VERSION ""

NS_ :

BS_:

BU_: BSM BSM2 CADM CVADAS ECM EPS ORC CANOE EVCU2

BO_ 609 BRAKE_FD_4: 32 BSM
 SG_ FD14_ASRActive : 90|1@0+ (1,0) [0|1] "-" Vector__XXX
 SG_ FD14_BSM_LnchAbrtSts : 33|2@0+ (1,0) [0|2] "-" Vector__XXX
 SG_ FD14_BSM_LnchCtrl_SftBtn_SelectS : 0|1@0+ (1,0) [0|1] "-" Vector__XXX
 SG_ FD14_BSM_LnchMode : 55|3@0+ (1,0) [0|6] "-" Vector__XXX
 SG_ FD14_CRC_BRAKE4 : 191|8@0+ (1,0) [0|255] "-"  CADM
 SG_ FD14_EPBSts : 115|4@0+ (1,0) [0|14] "-"  CADM,CVADAS
 SG_ FD14_ESC_OFF_Hrd_Sft_Button_sts : 151|3@0+ (1,0) [0|6] "-" Vector__XXX
 SG_ FD14_LaunchRPMsetting_BSM : 63|6@0+ (100,1000) [1000|7300] "rpm" Vector__XXX
 SG_ FD14_MessageCounter_BRAKE4 : 179|4@0+ (1,0) [0|15] "-"  CADM
 SG_ FD14_MSRActive : 92|1@0+ (1,0) [0|1] "-" Vector__XXX
 SG_ FD14_TravelDistance : 87|8@0+ (1,0) [0|255] "m" Vector__XXX

BO_ 1155 BRAKE_FD_5: 32 BSM
 SG_ FD14_ABSFailSts : 87|1@0+ (1,0) [0|1] "-"  ECM
 SG_ FD14_ACCEngaged : 92|1@0+ (1,0) [0|1] "-" Vector__XXX
 SG_ FD14_BSM_THA_Brk_Resp : 15|2@0+ (1,0) [0|3] "-"  CVADAS
 SG_ FD14_BSMSysSts : 89|2@0+ (1,0) [0|3] "-"  CADM
 SG_ FD14_CMMIntervention : 86|1@0+ (1,0) [0|1] "-" Vector__XXX
 SG_ FD14_CRC_BRAKE5 : 191|8@0+ (1,0) [0|255] "-"  BSM2,CADM,CVADAS,ECM
 SG_ FD14_EBDFailSts : 84|1@0+ (1,0) [0|1] "-" Vector__XXX
 SG_ FD14_ERMActive : 111|1@0+ (1,0) [0|1] "-" Vector__XXX
 SG_ FD14_ESC_TRSC_Brk_Resp : 5|2@0+ (1,0) [0|2] "-"  CVADAS
 SG_ FD14_ESCFailSts : 83|1@0+ (1,0) [0|1] "-"  CADM
 SG_ FD14_Function2Sts : 94|1@0+ (1,0) [0|1] "-" Vector__XXX
 SG_ FD14_FunctionFailSts : 81|1@0+ (1,0) [0|1] "-" Vector__XXX
 SG_ FD14_FunctionIntervention : 80|1@0+ (1,0) [0|1] "-" Vector__XXX
 SG_ FD14_FunctionSts : 95|1@0+ (1,0) [0|1] "-"  CADM
 SG_ FD14_MessageCounter_BRAKE5 : 179|4@0+ (1,0) [0|15] "-"  BSM2,CADM,CVADAS,ECM
 SG_ FD14_RollsModeAct : 91|1@0+ (1,0) [0|1] "-"  BSM2,CADM
 SG_ FD14_TSCActive : 110|1@0+ (1,0) [0|1] "-" Vector__XXX

BO_ 205 BRAKE_FD_6: 64 BSM
 SG_ FD14_CRC_BRAKE_FD_6 : 447|8@0+ (1,0) [0|255] "-"  ECM
 SG_ FD14_DriverReq_AxleTrq_Enabled_B : 175|4@0+ (1,0) [0|15] ""  CVADAS,ECM
 SG_ FD14_DriverRequested_AxleTrq_BSM : 159|16@0+ (2,-65534) [-65534|65536] "Nm"  ECM
 SG_ FD14_MessageCounter_BRAKE_FD_6 : 435|4@0+ (1,0) [0|15] "-"  ECM
 SG_ FD14_TotalAxle_Max_Rq_BSM : 51|1@0+ (1,0) [0|1] ""  ECM
 SG_ FD14_TotalAxle_Min_Rq_BSM : 50|1@0+ (1,0) [0|1] ""  ECM
 SG_ FD14_TotalAxle_Rq_BSM : 95|16@0+ (2,-65534) [-65534|65536] "Nm"  ECM

BO_ 514 BRAKE_FD_7: 32 BSM
 SG_ FD14_AEB_Type_Brk : 67|4@0+ (1,0) [0|14] "-"  BSM2,CADM,ORC
 SG_ FD14_Brake_OpStat_Prim : 82|3@0+ (1,0) [0|5] ""  CADM,ORC
 SG_ FD14_BrakePdlPosn : 63|8@0+ (0.4,0) [0|100] "%"  BSM2,CADM
 SG_ FD14_BrkPdl_Flt : 86|1@0+ (1,0) [0|1] "-"  CADM
 SG_ FD14_BrkPdl_Stat : 85|2@0+ (1,0) [0|2] "-"  BSM2,CADM,CVADAS,ECM
 SG_ FD14_BSM_HEALTH_CHECK : 7|8@0+ (1,0) [0|255] ""  BSM2
 SG_ FD14_BSM_OpStat : 74|3@0+ (1,0) [0|5] ""  BSM2,CADM
 SG_ FD14_CRC_BRAKE7 : 191|8@0+ (1,0) [0|255] "-"  BSM2,CADM
 SG_ FD14_MessageCounter_BRAKE7 : 179|4@0+ (1,0) [0|15] "-"  BSM2,CADM
 SG_ FD14_PAM_Brk_Rq_RspSts : 28|2@0+ (1,0) [0|3] "-"  CVADAS

BO_ 257 BRAKE2_FD_1: 64 BSM2
 SG_ FD14_ABSActive_B2 : 37|1@0+ (1,0) [0|1] ""  CADM
 SG_ FD14_Brk_Stat_B2 : 71|2@0+ (1,0) [0|2] ""  CADM
 SG_ FD14_CRC_BRAKE2_1 : 447|8@0+ (1,0) [0|255] "-"  CADM,CVADAS,EPS,ORC
 SG_ FD14_Ft_RrAxleCoupling_TrqRq_B2 : 143|8@0+ (12,0) [0|3060] "Nm" Vector__XXX
 SG_ FD14_Ft_RrTrqCoupling_ModeRq_B2 : 158|2@0+ (1,0) [0|3] "-" Vector__XXX
 SG_ FD14_Inlet_Pressure_Pos : 98|2@0+ (1,0) [0|2] ""  CADM
 SG_ FD14_LHF_FastPulseCounter_B2 : 87|8@0+ (1,0) [0|255] "pulse"  CADM
 SG_ FD14_LHF_Spin_B2 : 39|2@0+ (1,0) [0|3] ""  CADM
 SG_ FD14_LHF_WheelSensorFailSts_B2 : 53|1@0+ (1,0) [0|1] ""  CADM
 SG_ FD14_LHFWheelSpeed_B2 : 52|13@0+ (0.0625,0) [0|511.875] "Km/h"  CADM
 SG_ FD14_MessageCounter_BRAKE2_1 : 435|4@0+ (1,0) [0|15] "-"  CADM,CVADAS,EPS,ORC
 SG_ FD14_R_DIFF_TRQ_RQ_B2 : 151|9@0+ (10,0) [0|5100] "Nm" Vector__XXX
 SG_ FD14_Rear_Diff_BSM_RQ_B2 : 156|2@0+ (1,0) [0|2] "-" Vector__XXX
 SG_ FD14_RHF_FastPulseCounter_B2 : 95|8@0+ (1,0) [0|255] "pulse"  CADM
 SG_ FD14_RHF_Spin_B2 : 55|2@0+ (1,0) [0|3] ""  CADM
 SG_ FD14_RHF_WheelSensorFailSts_B2 : 69|1@0+ (1,0) [0|1] ""  CADM
 SG_ FD14_RHFWheelSpeed_B2 : 68|13@0+ (0.0625,0) [0|511.875] "Km/h"  CADM
 SG_ FD14_VehicleSpeedVSOSig_B2 : 36|13@0+ (0.0625,0) [0|511.875] "Km/h"  CADM,CVADAS,EPS

BO_ 524 BRAKE2_FD_2: 32 BSM2
 SG_ FD14_AEB_Type_Brk_B2 : 43|4@0+ (1,0) [0|15] ""  CADM
 SG_ FD14_Brake_OpStat_Sec : 53|3@0+ (1,0) [0|5] ""  CADM
 SG_ FD14_BrkTrq_B2 : 6|15@0+ (3,0) [0|98301] "Nm"  CADM
 SG_ FD14_BSM2_HEALTH_CHECK : 63|8@0+ (1,0) [0|255] ""  BSM
 SG_ FD14_BSM2_OpStat : 50|3@0+ (1,0) [0|5] ""  BSM,CADM
 SG_ FD14_CRC_BRAKE2_2 : 191|8@0+ (1,0) [0|255] "-"  BSM,CADM,ORC
 SG_ FD14_MessageCounter_BRAKE2_2 : 179|4@0+ (1,0) [0|15] "-"  BSM,CADM,ORC
 SG_ FD14_VehicleStandStillSts_B2 : 47|2@0+ (1,0) [0|2] ""  BSM,CADM

BO_ 1156 BRAKE2_FD_3: 32 BSM2
 SG_ FD14_ABSFailSts_B2 : 7|1@0+ (1,0) [0|1] ""  CADM
 SG_ FD14_CRC_BRAKE2_3 : 191|8@0+ (1,0) [0|255] "-"  CADM,ORC
 SG_ FD14_MessageCounter_BRAKE2_3 : 179|4@0+ (1,0) [0|15] "-"  CADM,ORC
 SG_ FD14_RollsModeAct_B2 : 6|1@0+ (1,0) [0|1] ""  CADM

BO_ 275 CVPAM_FD_Control: 32 CVADAS
 SG_ FD14_CRC_CVPAM_FD_Control : 191|8@0+ (1,0) [0|255] "-"  BSM,EPS
 SG_ FD14_ManoeuvrePhase : 149|1@0+ (1,0) [0|1] "-"  EPS
 SG_ FD14_MessageCounter_CVPAM_FD_Con : 179|4@0+ (1,0) [0|15] "-"  BSM,EPS
 SG_ FD14_ParkingGearShiftReq : 164|3@0+ (1,0) [0|6] "-"  BSM
 SG_ FD14_PPPA_AccelMax : 116|5@0+ (0.1,0) [0|3.1] "m/s2"  BSM
 SG_ FD14_PPPA_AccelMin : 108|5@0+ (0.1,0) [0|3.1] "m/s2"  BSM
 SG_ FD14_PPPA_DecelMax : 100|5@0+ (0.1,0) [0|3.1] "m/s2"  BSM
 SG_ FD14_PPPA_DecelMin : 92|5@0+ (0.1,0) [0|3.1] "m/s2"  BSM
 SG_ FD14_PPPA_Interface_BSM : 182|2@0+ (1,0) [0|2] "-"  BSM
 SG_ FD14_PPPA_JerkAccelMax : 85|6@0+ (0.05,0) [0|3.15] "m/s3"  BSM
 SG_ FD14_PPPA_JerkAccelMin : 77|6@0+ (0.05,0) [0|3.15] "m/s3"  BSM
 SG_ FD14_PPPA_JerkDecelMax : 69|6@0+ (0.05,0) [0|3.15] "m/s3"  BSM
 SG_ FD14_PPPA_JerkDecelMin : 61|6@0+ (0.05,0) [0|3.15] "m/s3"  BSM
 SG_ FD14_PPPA_MaxSpeed : 127|8@0+ (0.0625,0) [0|15.875] "kph"  BSM
 SG_ FD14_PPPA_StandstillRqst : 180|1@0+ (1,0) [0|1] "-"  BSM
 SG_ FD14_PPPA_TargetDistance : 129|10@0+ (1,0) [0|1022] "cm"  BSM
 SG_ FD14_RR_PAM_Brk_RqSts : 150|1@0+ (1,0) [0|1] "-"  BSM
 SG_ FD14_RR_PAM_Dist : 161|10@0+ (1,0) [0|1022] "cm"  BSM
 SG_ FD14_SPM_Lat_Ctrl_RequestSts : 148|2@0+ (1,0) [0|2] "-"  EPS,ORC
 SG_ FD14_TorqueOverlaySteeringReq_SP : 146|11@0+ (0.0078125,-8) [-8|7.9921875] "Nm"  EPS,ORC

BO_ 950 CVPAM_FD_Info: 32 CVADAS
 SG_ FD14_CRC_CVPAM_FD_Info : 191|8@0+ (1,0) [0|255] ""  BSM
 SG_ FD14_MessageCounter_CVPAM_FD_Inf : 179|4@0+ (1,0) [0|15] ""  BSM
 SG_ FD14_ParkingManeuverActive : 66|3@0+ (1,0) [0|6] "-"  BSM

BO_ 1054 ENGINE_FD_1: 32 ECM
 SG_ FD14_CRC_ENGINE1 : 191|8@0+ (1,0) [0|255] "-"  CADM
 SG_ FD14_MessageCounter_ENGINE1 : 179|4@0+ (1,0) [0|15] "-"  CADM
 SG_ FD14_ThermalManagementActive_W : 1|1@0+ (1,0) [0|1] "-"  CADM

BO_ 262 ENGINE_FD_2: 64 ECM
 SG_ FD14_CRC_ENGINE2 : 447|8@0+ (1,0) [0|255] "-"  BSM,CADM,CVADAS,EPS
 SG_ FD14_ECM_LHOM_W : 188|1@0+ (1,0) [0|1] "-"  CADM
 SG_ FD14_EngineSpeed_W : 21|14@0+ (1,0) [0|16382] "1/min"  BSM,CADM,EPS
 SG_ FD14_EngineSts_W : 87|2@0+ (1,0) [0|3] "-"  BSM,CADM,CVADAS,EPS
 SG_ FD14_ESS_ENG_ST_W : 175|4@0+ (1,0) [0|15] "-"  BSM,CADM,CVADAS,EPS
 SG_ FD14_GasPedalPosition_W : 143|8@0+ (0.392,0) [0|99.568] "%"  BSM
 SG_ FD14_GasPedalPositionFailSts_W : 169|1@0+ (1,0) [0|1] "-"  BSM,CADM
 SG_ FD14_LV12PwrFreeRq_W : 176|1@0+ (1,0) [0|1] "-" Vector__XXX
 SG_ FD14_MessageCounter_ENGINE2 : 435|4@0+ (1,0) [0|15] "-"  BSM,CADM,CVADAS,EPS
 SG_ FD14_PowertrainPrplsnActv : 181|1@0+ (1,0) [0|1] ""  BSM,CADM

BO_ 1036 ENGINE_FD_3: 32 ECM
 SG_ FD14_CRC_ENGINE3 : 191|8@0+ (1,0) [0|255] "-"  BSM
 SG_ FD14_MessageCounter_ENGINE3 : 179|4@0+ (1,0) [0|15] "-"  BSM

BO_ 518 ENGINE_FD_5: 32 ECM
 SG_ FD14_CRC_ENGINE5 : 191|8@0+ (1,0) [0|255] "-"  BSM,BSM2,CADM
 SG_ FD14_MessageCounter_ENGINE5 : 179|4@0+ (1,0) [0|15] "-"  BSM,BSM2,CADM
 SG_ FD14_PdlPosActual : 87|8@0+ (0.4,0) [0|100] "%"  BSM,BSM2,CADM,CVADAS
 SG_ FD14_RPMOverRev_W : 115|1@0+ (1,0) [0|1] "-"  CADM

BO_ 1448 ENGINE_FD_7: 32 ECM
 SG_ FD14_CRC_ENGINE7 : 191|8@0+ (1,0) [0|255] "-"  CVADAS
 SG_ FD14_ECM_THA_Resp : 73|2@0+ (1,0) [0|2] "-"  CVADAS
 SG_ FD14_ECM_TRSC_Resp : 7|2@0+ (1,0) [0|2] "-"  CVADAS
 SG_ FD14_MessageCounter_ENGINE7 : 179|4@0+ (1,0) [0|15] "-"  CVADAS

BO_ 264 EPS_FD_1: 32 EPS
 SG_ FD14_CRC_EPS1 : 191|8@0+ (1,0) [0|255] "-"  BSM,CADM,CVADAS,ORC
 SG_ FD14_ElectricSteeringFailSts : 37|1@0+ (1,0) [0|1] "-" Vector__XXX
 SG_ FD14_EngineFanRequestActivation : 38|1@0+ (1,0) [0|1] "-" Vector__XXX
 SG_ FD14_EPS_ADAS_IMC_Fault : 69|1@0+ (1,0) [0|1] ""  CADM
 SG_ FD14_EPS_AsstStat : 55|3@0+ (1,0) [0|6] "-"  CADM
 SG_ FD14_EPS_Curr : 87|8@0+ (1,-50) [-50|204] "Amp" Vector__XXX
 SG_ FD14_EPS_Hands_On_Sts : 67|1@0+ (1,0) [0|1] "-"  CADM,ORC
 SG_ FD14_EPS_HandsOnRecognition : 22|1@0+ (1,0) [0|1] "-"  CVADAS,ORC
 SG_ FD14_EPSMotorTorque : 66|11@0+ (0.004882815,-5) [-5|4.99023949] "Nm"  CADM,ORC
 SG_ FD14_ESA_LAT_CTRL_ResponseSts : 135|3@0+ (1,0) [0|6] "-"  BSM,CADM
 SG_ FD14_HAS_LAT_CTRL_ResponseSts : 101|3@0+ (1,0) [0|7] "-"  CADM,ORC
 SG_ FD14_LKA_LAT_CTRL_ResponseSts : 71|2@0+ (1,0) [0|3] "-"  CADM,ORC
 SG_ FD14_LwsAngle : 7|16@0+ (0.1,-720) [-720|720] "°"  BSM,CADM,CVADAS
 SG_ FD14_LwsAngleType : 52|2@0+ (1,0) [0|2] "-"  BSM,CADM,CVADAS
 SG_ FD14_LwsCalibration : 36|1@0+ (1,0) [0|1] "-"  BSM,CADM
 SG_ FD14_LwsSpeed : 19|12@0+ (1,-2000) [-2000|2094] "°/s"  CADM,CVADAS
 SG_ FD14_MessageCounter_EPS1 : 179|4@0+ (1,0) [0|15] "-"  BSM,CADM,CVADAS,ORC
 SG_ FD14_SPM_Lat_Ctrl_ResponseSts : 103|2@0+ (1,0) [0|3] "-"  CVADAS,ORC
 SG_ FD14_Steering_Column_Torque : 50|11@0+ (0.0078125,-8) [-8|7.984375] "NM"  CADM,CVADAS
 SG_ FD14_Steering_OpStat_Prim : 111|3@0+ (1,0) [0|5] ""  CADM,ORC
 SG_ FD14_SteeringVibration_Fault : 39|1@0+ (1,0) [0|1] "-"  CADM
 SG_ FD14_SteeringVibration_Status : 23|1@0+ (1,0) [0|1] "-"  CADM,ORC

BO_ 1056 EPS_FD_2: 32 EPS
 SG_ FD14_CRC_EPS2 : 191|8@0+ (1,0) [0|255] "0"  CVADAS
 SG_ FD14_EPS_MODE_STAT : 7|3@0+ (1,0) [0|3] "" Vector__XXX
 SG_ FD14_EPS_SteeringTouchStat : 4|1@0+ (1,0) [0|1] ""  CVADAS
 SG_ FD14_EPS_SteeringTouq_Resp : 3|2@0+ (1,0) [0|1] ""  CVADAS
 SG_ FD14_EPS_THA_DriverTorqueOverrid : 1|2@0+ (1,0) [0|1] ""  CVADAS
 SG_ FD14_EPS_THA_SteeringTorqueResp : 13|3@0+ (1,0) [0|6] ""  CVADAS
 SG_ FD14_EPS_Warn_Disp_Rq : 87|3@0+ (1,0) [0|3] "" Vector__XXX
 SG_ FD14_MessageCounter_EPS2 : 179|4@0+ (1,0) [0|15] "0"  CVADAS
 SG_ FD14_THA_SteeringTouchStat : 15|2@0+ (1,0) [0|1] ""  CVADAS

BO_ 1626 IMPACT_INFO: 32 ORC
 SG_ FD14_IMPACT_B : 84|1@0+ (1,0) [0|1] "-" Vector__XXX
 SG_ FD14_IMPACT_C : 85|1@0+ (1,0) [0|1] "-" Vector__XXX
 SG_ FD14_IMPACT_F : 88|1@0+ (1,0) [0|1] "-" Vector__XXX
 SG_ FD14_IMPACT_I : 91|1@0+ (1,0) [0|1] "-" Vector__XXX
 SG_ FD14_IMPACT_K : 92|1@0+ (1,0) [0|1] "-" Vector__XXX
 SG_ FD14_IMPACT_M : 94|1@0+ (1,0) [0|1] "-" Vector__XXX
 SG_ FD14_IMPACTCommand : 80|1@0+ (1,0) [0|1] "-"  CADM
 SG_ FD14_IMPACTConfirm : 81|1@0+ (1,0) [0|1] "-"  CADM
 SG_ FD14_IMPACTFailSts : 82|1@0+ (1,0) [0|1] "-" Vector__XXX
 SG_ FD14_IMPACTThreshold : 103|1@0+ (1,0) [0|1] "-" Vector__XXX

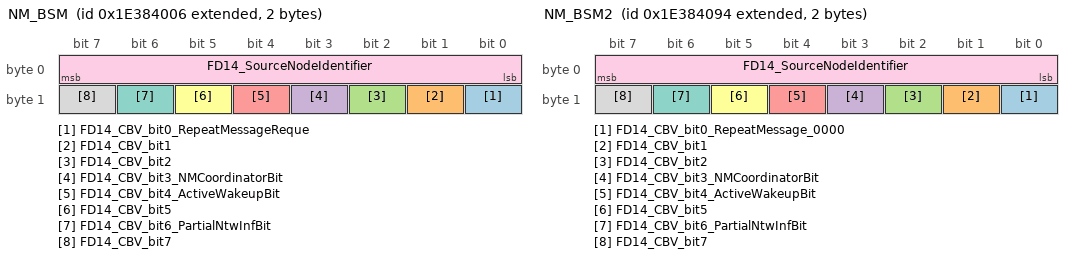
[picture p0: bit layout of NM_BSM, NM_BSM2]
BO_ 2654486534 NM_BSM: 2 BSM
 SG_ FD14_CBV_bit0_RepeatMessageReque : 8|1@0+ (1,0) [0|1] ""  BSM2,CADM,CVADAS,ECM,EPS,ORC
 SG_ FD14_CBV_bit1 : 9|1@0+ (1,0) [0|1] ""  BSM2,CADM,CVADAS,ECM,EPS,ORC
 SG_ FD14_CBV_bit2 : 10|1@0+ (1,0) [0|1] ""  BSM2,CADM,CVADAS,ECM,EPS,ORC
 SG_ FD14_CBV_bit3_NMCoordinatorBit : 11|1@0+ (1,0) [0|1] ""  BSM2,CADM,CVADAS,ECM,EPS,ORC
 SG_ FD14_CBV_bit4_ActiveWakeupBit : 12|1@0+ (1,0) [0|1] ""  BSM2,CADM,CVADAS,ECM,EPS,ORC
 SG_ FD14_CBV_bit5 : 13|1@0+ (1,0) [0|1] ""  BSM2,CADM,CVADAS,ECM,EPS,ORC
 SG_ FD14_CBV_bit6_PartialNtwInfBit : 14|1@0+ (1,0) [0|1] ""  BSM2,CADM,CVADAS,ECM,EPS,ORC
 SG_ FD14_CBV_bit7 : 15|1@0+ (1,0) [0|1] ""  BSM2,CADM,CVADAS,ECM,EPS,ORC
 SG_ FD14_SourceNodeIdentifier : 7|8@0+ (1,0) [0|255] "-"  BSM2,CADM,CVADAS,ECM,EPS,ORC

BO_ 2654486676 NM_BSM2: 2 BSM2
 SG_ FD14_CBV_bit0_RepeatMessage_0000 : 8|1@0+ (1,0) [0|1] ""  BSM,CADM,CVADAS,ECM,EPS,ORC
 SG_ FD14_CBV_bit1 : 9|1@0+ (1,0) [0|1] ""  BSM,CADM,CVADAS,ECM,EPS,ORC
 SG_ FD14_CBV_bit2 : 10|1@0+ (1,0) [0|1] ""  BSM,CADM,CVADAS,ECM,EPS,ORC
 SG_ FD14_CBV_bit3_NMCoordinatorBit : 11|1@0+ (1,0) [0|1] ""  BSM,CADM,CVADAS,ECM,EPS,ORC
 SG_ FD14_CBV_bit4_ActiveWakeupBit : 12|1@0+ (1,0) [0|1] ""  BSM,CADM,CVADAS,ECM,EPS,ORC
 SG_ FD14_CBV_bit5 : 13|1@0+ (1,0) [0|1] ""  BSM,CADM,CVADAS,ECM,EPS,ORC
 SG_ FD14_CBV_bit6_PartialNtwInfBit : 14|1@0+ (1,0) [0|1] ""  BSM,CADM,CVADAS,ECM,EPS,ORC
 SG_ FD14_CBV_bit7 : 15|1@0+ (1,0) [0|1] ""  BSM,CADM,CVADAS,ECM,EPS,ORC
 SG_ FD14_SourceNodeIdentifier : 7|8@0+ (1,0) [0|255] "-"  BSM,CADM,CVADAS,ECM,EPS,ORC

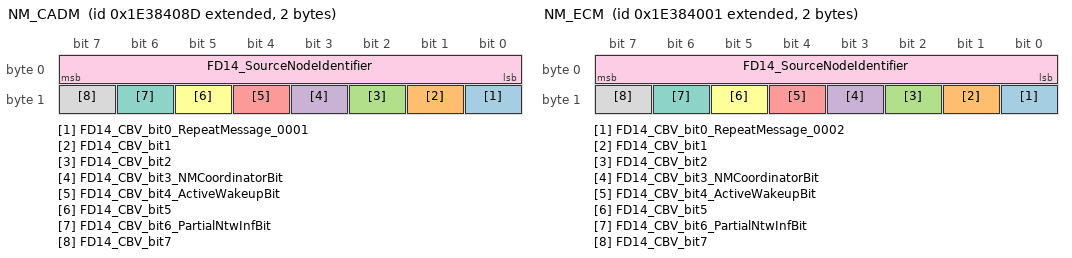
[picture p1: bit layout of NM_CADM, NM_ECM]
BO_ 2654486669 NM_CADM: 2 CADM
 SG_ FD14_CBV_bit0_RepeatMessage_0001 : 8|1@0+ (1,0) [0|1] ""  BSM,BSM2,CVADAS,ECM,EPS,ORC
 SG_ FD14_CBV_bit1 : 9|1@0+ (1,0) [0|1] ""  BSM,BSM2,CVADAS,ECM,EPS,ORC
 SG_ FD14_CBV_bit2 : 10|1@0+ (1,0) [0|1] ""  BSM,BSM2,CVADAS,ECM,EPS,ORC
 SG_ FD14_CBV_bit3_NMCoordinatorBit : 11|1@0+ (1,0) [0|1] ""  BSM,BSM2,CVADAS,ECM,EPS,ORC
 SG_ FD14_CBV_bit4_ActiveWakeupBit : 12|1@0+ (1,0) [0|1] ""  BSM,BSM2,CVADAS,ECM,EPS,ORC
 SG_ FD14_CBV_bit5 : 13|1@0+ (1,0) [0|1] ""  BSM,BSM2,CVADAS,ECM,EPS,ORC
 SG_ FD14_CBV_bit6_PartialNtwInfBit : 14|1@0+ (1,0) [0|1] ""  BSM,BSM2,CVADAS,ECM,EPS,ORC
 SG_ FD14_CBV_bit7 : 15|1@0+ (1,0) [0|1] ""  BSM,BSM2,CVADAS,ECM,EPS,ORC
 SG_ FD14_SourceNodeIdentifier : 7|8@0+ (1,0) [0|255] "-"  BSM,BSM2,CVADAS,ECM,EPS,ORC

BO_ 2654486529 NM_ECM: 2 ECM
 SG_ FD14_CBV_bit0_RepeatMessage_0002 : 8|1@0+ (1,0) [0|1] ""  BSM,BSM2,CADM,CVADAS,EPS,ORC
 SG_ FD14_CBV_bit1 : 9|1@0+ (1,0) [0|1] ""  BSM,BSM2,CADM,CVADAS,EPS,ORC
 SG_ FD14_CBV_bit2 : 10|1@0+ (1,0) [0|1] ""  BSM,BSM2,CADM,CVADAS,EPS,ORC
 SG_ FD14_CBV_bit3_NMCoordinatorBit : 11|1@0+ (1,0) [0|1] ""  BSM,BSM2,CADM,CVADAS,EPS,ORC
 SG_ FD14_CBV_bit4_ActiveWakeupBit : 12|1@0+ (1,0) [0|1] ""  BSM,BSM2,CADM,CVADAS,EPS,ORC
 SG_ FD14_CBV_bit5 : 13|1@0+ (1,0) [0|1] ""  BSM,BSM2,CADM,CVADAS,EPS,ORC
 SG_ FD14_CBV_bit6_PartialNtwInfBit : 14|1@0+ (1,0) [0|1] ""  BSM,BSM2,CADM,CVADAS,EPS,ORC
 SG_ FD14_CBV_bit7 : 15|1@0+ (1,0) [0|1] ""  BSM,BSM2,CADM,CVADAS,EPS,ORC
 SG_ FD14_SourceNodeIdentifier : 7|8@0+ (1,0) [0|255] "-"  BSM,BSM2,CADM,CVADAS,EPS,ORC

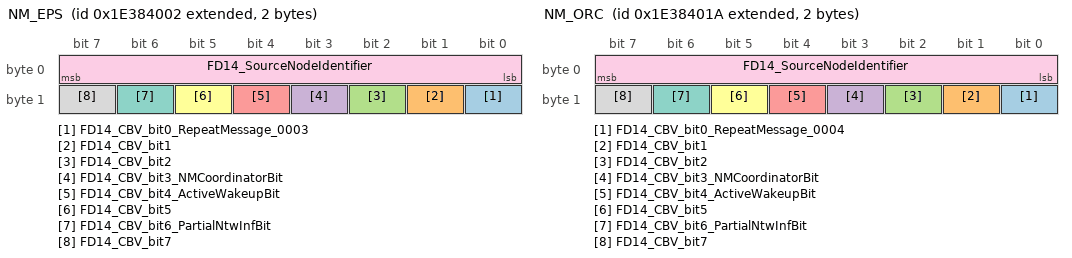
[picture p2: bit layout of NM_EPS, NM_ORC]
BO_ 2654486530 NM_EPS: 2 EPS
 SG_ FD14_CBV_bit0_RepeatMessage_0003 : 8|1@0+ (1,0) [0|1] ""  BSM,BSM2,CADM,CVADAS,ECM,ORC
 SG_ FD14_CBV_bit1 : 9|1@0+ (1,0) [0|1] ""  BSM,BSM2,CADM,CVADAS,ECM,ORC
 SG_ FD14_CBV_bit2 : 10|1@0+ (1,0) [0|1] ""  BSM,BSM2,CADM,CVADAS,ECM,ORC
 SG_ FD14_CBV_bit3_NMCoordinatorBit : 11|1@0+ (1,0) [0|1] ""  BSM,BSM2,CADM,CVADAS,ECM,ORC
 SG_ FD14_CBV_bit4_ActiveWakeupBit : 12|1@0+ (1,0) [0|1] ""  BSM,BSM2,CADM,CVADAS,ECM,ORC
 SG_ FD14_CBV_bit5 : 13|1@0+ (1,0) [0|1] ""  BSM,BSM2,CADM,CVADAS,ECM,ORC
 SG_ FD14_CBV_bit6_PartialNtwInfBit : 14|1@0+ (1,0) [0|1] ""  BSM,BSM2,CADM,CVADAS,ECM,ORC
 SG_ FD14_CBV_bit7 : 15|1@0+ (1,0) [0|1] ""  BSM,BSM2,CADM,CVADAS,ECM,ORC
 SG_ FD14_SourceNodeIdentifier : 7|8@0+ (1,0) [0|255] "-"  BSM,BSM2,CADM,CVADAS,ECM,ORC

BO_ 2654486554 NM_ORC: 2 ORC
 SG_ FD14_CBV_bit0_RepeatMessage_0004 : 8|1@0+ (1,0) [0|1] ""  BSM,BSM2,CADM,CVADAS,ECM,EPS
 SG_ FD14_CBV_bit1 : 9|1@0+ (1,0) [0|1] ""  BSM,BSM2,CADM,CVADAS,ECM,EPS
 SG_ FD14_CBV_bit2 : 10|1@0+ (1,0) [0|1] ""  BSM,BSM2,CADM,CVADAS,ECM,EPS
 SG_ FD14_CBV_bit3_NMCoordinatorBit : 11|1@0+ (1,0) [0|1] ""  BSM,BSM2,CADM,CVADAS,ECM,EPS
 SG_ FD14_CBV_bit4_ActiveWakeupBit : 12|1@0+ (1,0) [0|1] ""  BSM,BSM2,CADM,CVADAS,ECM,EPS
 SG_ FD14_CBV_bit5 : 13|1@0+ (1,0) [0|1] ""  BSM,BSM2,CADM,CVADAS,ECM,EPS
 SG_ FD14_CBV_bit6_PartialNtwInfBit : 14|1@0+ (1,0) [0|1] ""  BSM,BSM2,CADM,CVADAS,ECM,EPS
 SG_ FD14_CBV_bit7 : 15|1@0+ (1,0) [0|1] ""  BSM,BSM2,CADM,CVADAS,ECM,EPS
 SG_ FD14_SourceNodeIdentifier : 7|8@0+ (1,0) [0|255] "-"  BSM,BSM2,CADM,CVADAS,ECM,EPS

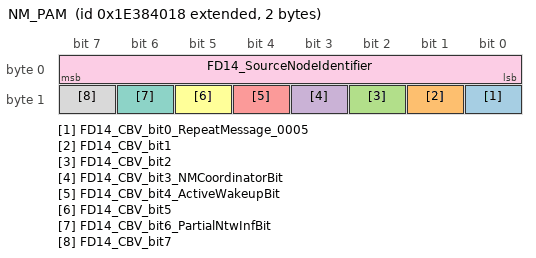
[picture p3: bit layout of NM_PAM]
BO_ 2654486552 NM_PAM: 2 CVADAS
 SG_ FD14_CBV_bit0_RepeatMessage_0005 : 8|1@0+ (1,0) [0|1] ""  BSM,BSM2,CADM,ECM,EPS,ORC
 SG_ FD14_CBV_bit1 : 9|1@0+ (1,0) [0|1] ""  BSM,BSM2,CADM,ECM,EPS,ORC
 SG_ FD14_CBV_bit2 : 10|1@0+ (1,0) [0|1] ""  BSM,BSM2,CADM,ECM,EPS,ORC
 SG_ FD14_CBV_bit3_NMCoordinatorBit : 11|1@0+ (1,0) [0|1] ""  BSM,BSM2,CADM,ECM,EPS,ORC
 SG_ FD14_CBV_bit4_ActiveWakeupBit : 12|1@0+ (1,0) [0|1] ""  BSM,BSM2,CADM,ECM,EPS,ORC
 SG_ FD14_CBV_bit5 : 13|1@0+ (1,0) [0|1] ""  BSM,BSM2,CADM,ECM,EPS,ORC
 SG_ FD14_CBV_bit6_PartialNtwInfBit : 14|1@0+ (1,0) [0|1] ""  BSM,BSM2,CADM,ECM,EPS,ORC
 SG_ FD14_CBV_bit7 : 15|1@0+ (1,0) [0|1] ""  BSM,BSM2,CADM,ECM,EPS,ORC
 SG_ FD14_SourceNodeIdentifier : 7|8@0+ (1,0) [0|255] "-"  BSM,BSM2,CADM,ECM,EPS,ORC

BO_ 611 ORC_FD_1: 32 ORC
 SG_ FD14_CRC_ORC1 : 191|8@0+ (1,0) [0|255] "-"  BSM,CADM
 SG_ FD14_MessageCounter_ORC1 : 179|4@0+ (1,0) [0|15] "-"  BSM,CADM
 SG_ FD14_SBR1RowDriverSeatSts : 94|2@0+ (1,0) [0|2] "-"  BSM,CADM

BO_ 1954 ORC_FD_2: 32 ORC
 SG_ FD14_CRC_ORC2 : 191|8@0+ (1,0) [0|255] "-"  BSM
 SG_ FD14_MessageCounter_ORC2 : 179|4@0+ (1,0) [0|15] "-"  BSM
 SG_ FD14_ORCIdentification : 87|32@0+ (1,0) [0|4294967295] "-"  BSM

BO_ 274 ORC_FD_3: 32 ORC
 SG_ FD14_CRC_ORC3 : 191|8@0+ (1,0) [0|255] "-"  BSM,CADM
 SG_ FD14_InternalError : 165|1@0+ (1,0) [0|1] "-"  BSM,CADM
 SG_ FD14_LatAcceleration : 147|12@0+ (0.02,-40.96) [-40.96|40.92] "m/s^2"  BSM,CADM
 SG_ FD14_LatAccelerationFailSts : 182|1@0+ (1,0) [0|1] "-"  BSM,CADM
 SG_ FD14_LongAcceleration : 131|12@0+ (0.02,-40.96) [-40.96|40.92] "m/s^2"  BSM,CADM
 SG_ FD14_LongAccelerationFailSts : 183|1@0+ (1,0) [0|1] "-"  BSM,CADM
 SG_ FD14_MessageCounter_ORC3 : 179|4@0+ (1,0) [0|15] "-"  BSM,CADM
 SG_ FD14_YawRate : 163|12@0+ (0.08,-163.84) [-163.84|163.68] "deg/s"  BSM,CADM
 SG_ FD14_YawRate_HR : 10|3@0+ (0.02,0) [0|0.06] "deg/s"  CADM
 SG_ FD14_YawRate_HR_Sign : 7|1@0+ (1,0) [0|1] "deg/s"  CADM
 SG_ FD14_YawRateFailSts : 181|1@0+ (1,0) [0|1] "-"  BSM,CADM

BO_ 255 PT_TORQUE_FD_1: 48 ECM
 SG_ FD14_ACC_NCC_TrqEnblRq_Allowed : 23|1@0+ (1,0) [0|1] "-"  CADM
 SG_ FD14_Accel_Pedal_Override : 37|1@0+ (1,0) [0|1] "-"  BSM,CADM,CVADAS
 SG_ FD14_CRC_PT_TORQUE_FD_1 : 319|8@0+ (1,0) [0|255] "-"  BSM,CADM
 SG_ FD14_ESC_TrqEnblRq_Allowed : 38|1@0+ (1,0) [0|1] "-" Vector__XXX
 SG_ FD14_MessageCounter_PT_TORQUE_FD : 307|4@0+ (1,0) [0|15] "-"  BSM,CADM
 SG_ FD14_PPPA_TrqEnblRq_Allowed : 21|1@0+ (1,0) [0|1] "-"  BSM,CVADAS
 SG_ FD14_SSC_TrqEnblRq_Allowed : 22|1@0+ (1,0) [0|1] "-" Vector__XXX
 SG_ FD14_SumTorque_DrvReqMod : 20|13@0+ (0.25,-500) [-500|1547.5] "Nm" Vector__XXX
 SG_ FD14_SumTorqueExp : 34|11@0+ (1,-500) [-500|1546] "Nm" Vector__XXX
 SG_ FD14_SumTorqueMax : 50|11@0+ (1,-500) [-500|1546] "Nm" Vector__XXX
 SG_ FD14_SumTorqueMin : 66|11@0+ (1,-500) [-500|1546] "Nm" Vector__XXX
 SG_ FD14_SumTorqueSel_D_TTC : 82|11@0+ (1,-500) [-500|1546] "Nm" Vector__XXX
 SG_ FD14_SumTorqueStatic : 98|11@0+ (1,-500) [-500|1546] "Nm" Vector__XXX
 SG_ FD14_Total_AxleTorque_Static : 151|16@0+ (2,-65534) [-65534|65536] "Nm"  CADM

BO_ 1472 TRSCM_FD_1: 32 CVADAS
 SG_ FD14_CRC_TRSCM1 : 191|8@0+ (1,0) [0|255] "-"  BSM,ECM,EPS
 SG_ FD14_MessageCounter_TRSCM1 : 179|4@0+ (1,0) [0|15] "-"  BSM,ECM,EPS
 SG_ FD14_THA_EPB_Req : 95|2@0+ (1,0) [0|3] ""  BSM
 SG_ FD14_THA_Speed_Limit : 85|5@0+ (1,0) [0|31] ""  BSM,ECM,EPS
 SG_ FD14_THA_SpeedLimit_Req : 52|2@0+ (1,0) [0|3] ""  BSM,ECM
 SG_ FD14_THA_STAT : 55|3@0+ (1,0) [0|6] ""  BSM,ECM,EPS
 SG_ FD14_THA_SteeringDamping : 79|8@0+ (0.78125,0) [0|199.21875] "%"  EPS
 SG_ FD14_THA_SteeringTorqueInfo : 63|11@0+ (0.0078125,-8) [-8|7.9921875] ""  EPS
 SG_ FD14_THA_SteeringTorqueReq : 87|2@0+ (1,0) [0|3] ""  EPS
 SG_ FD14_TRSC_SpeedLimit_Req : 15|4@0+ (1,0) [0|14] ""  BSM,ECM
 SG_ FD14_TRSC_STAT : 7|3@0+ (1,0) [0|6] ""  BSM,ECM
 SG_ FD14_TRSC_SteeringDamping : 23|8@0+ (0.78125,0) [0|199.21875] "%"  EPS
 SG_ FD14_TRSC_SteeringTorqueInfo : 31|11@0+ (0.0078125,-8) [-8|7.9921875] ""  EPS
 SG_ FD14_TRSC_SteeringTorqueReq : 11|2@0+ (1,0) [0|2] ""  EPS
 SG_ FD14_TRSC_VehicleStop_Req : 36|2@0+ (1,0) [0|2] ""  BSM

CM_ SG_ 609 FD14_ASRActive "This signal is set to Active when the intervention by ASR is Active";
CM_ SG_ 609 FD14_BSM_LnchAbrtSts "Launch Control Abort Status";
CM_ SG_ 609 FD14_BSM_LnchCtrl_SftBtn_SelectS "Soft button launch selected; Launch selected = [1]";
CM_ SG_ 609 FD14_BSM_LnchMode "Launch Control Status";
CM_ SG_ 609 FD14_CRC_BRAKE4 "CRC according to SAE J1850 standard at each frame transmission.";
CM_ SG_ 609 FD14_EPBSts "0";
CM_ SG_ 609 FD14_ESC_OFF_Hrd_Sft_Button_sts "ESC hard button status";
CM_ SG_ 609 FD14_LaunchRPMsetting_BSM "BSM  Launch RPM setting";
CM_ SG_ 609 FD14_MessageCounter_BRAKE4 "This signal is a counter used for safety checks strategies. This counter is incremented of 1 (one) unit at each frame transmission.";
CM_ SG_ 609 FD14_MSRActive "0";
CM_ SG_ 609 FD14_TravelDistance "This signal indicates the travel distance value.";
CM_ SG_ 1155 FD14_ABSFailSts "0";
CM_ SG_ 1155 FD14_ACCEngaged "ACC is engaged";
CM_ SG_ 1155 FD14_BSM_THA_Brk_Resp "BSM braking status for trailer hitch assist";
CM_ SG_ 1155 FD14_BSMSysSts "This signal is used by BSM to indicate its mode";
CM_ SG_ 1155 FD14_CMMIntervention "0";
CM_ SG_ 1155 FD14_CRC_BRAKE5 "CRC according to SAE J1850 standard at each frame transmission.";
CM_ SG_ 1155 FD14_EBDFailSts "0";
CM_ SG_ 1155 FD14_ERMActive "This signal is set to \"active\" when Electronic Roll Mitigation functionality is acting.";
CM_ SG_ 1155 FD14_ESC_TRSC_Brk_Resp "ESC break activation response";
CM_ SG_ 1155 FD14_ESCFailSts "0";
CM_ SG_ 1155 FD14_Function2Sts "Indicates the partial off status of the ESC/TCS system. [0]: Not_Active - Indicates that the ESC/TCS system is enabled, [1]: Active - Indicates that the ESC/TCS engine management is disabled";
CM_ SG_ 1155 FD14_FunctionFailSts "This signal indicates the health status of the traction control system. [0]: Fail_Not_Present, [1]: Fail_Present";
CM_ SG_ 1155 FD14_FunctionIntervention "This signal indicates the BSM is actively controlling the vehicle through either engine torque management or brake pressure modulation.";
CM_ SG_ 1155 FD14_FunctionSts "Indicates the full off status of the ESC/TCS system. [0]: Not_Active - Indicates that the ESC/TCS system is enabled, [1]: Active - Indicates that the ESC/TCS system is completely disabled";
CM_ SG_ 1155 FD14_MessageCounter_BRAKE5 "This signal is a counter used for safety checks strategies. This counter is incremented of 1 (one) unit at each frame transmission.";
CM_ SG_ 1155 FD14_RollsModeAct "This signal indicates when the brake system module is in the Rolls Test mode.";
CM_ SG_ 1155 FD14_TSCActive "This signal is set to \"active\" when Trailer Sway Control functionality is acting";
CM_ SG_ 205 FD14_CRC_BRAKE_FD_6 "CRC according to SAE J1850 standard at each frame transmission.";
CM_ SG_ 205 FD14_DriverReq_AxleTrq_Enabled_B "It indicates the request to enable virtual driver torque interface for BSM driver functions";
CM_ SG_ 205 FD14_DriverRequested_AxleTrq_BSM "Virtual driver torque request from BSM";
CM_ SG_ 205 FD14_MessageCounter_BRAKE_FD_6 "This signal is a counter used for safety checks strategies. This counter is incremented of 1 (one) unit at each frame transmission.";
CM_ SG_ 205 FD14_TotalAxle_Max_Rq_BSM "Combined axle traction torque max limit flag. Active = [1]";
CM_ SG_ 205 FD14_TotalAxle_Min_Rq_BSM "Combined axle traction torque min limit flag. Active = [1]";
CM_ SG_ 205 FD14_TotalAxle_Rq_BSM "Combined axle traction torque request";
CM_ SG_ 514 FD14_AEB_Type_Brk "AEB type brake signal";
CM_ SG_ 514 FD14_Brake_OpStat_Prim "Capability of the Braking system to perform deceleration and/or stability control as reported by primary actuator";
CM_ SG_ 514 FD14_BrakePdlPosn "Brake pedal travel sensor 0-100% (0 = upstop)";
CM_ SG_ 514 FD14_BrkPdl_Flt "Brake Pedal Fault is active, 1=Faulted";
CM_ SG_ 514 FD14_BrkPdl_Stat "Brake pedal state";
CM_ SG_ 514 FD14_BSM_HEALTH_CHECK "BSM_HEALTH_CHECK";
CM_ SG_ 514 FD14_BSM_OpStat "Capability of the primary brake control module to provide deceleration and/or stability control";
CM_ SG_ 514 FD14_CRC_BRAKE7 "CRC according to SAE J1850 standard at each frame transmission.";
CM_ SG_ 514 FD14_MessageCounter_BRAKE7 "This signal is a counter used for safety checks strategies. This counter is incremented of 1 (one) unit at each frame transmission.";
CM_ SG_ 514 FD14_PAM_Brk_Rq_RspSts "PAM Brake Request Response Status made by the BSM for Park Assist with Stop.";
CM_ SG_ 257 FD14_ABSActive_B2 "ABSActive_B2";
CM_ SG_ 257 FD14_Brk_Stat_B2 "Signifies a general braking event (both autonomous and driver requested) with the secondary brake control module";
CM_ SG_ 257 FD14_CRC_BRAKE2_1 "CRC according to SAE J1850 standard at each frame transmission.";
CM_ SG_ 257 FD14_Ft_RrAxleCoupling_TrqRq_B2 "Desired Torque for Center Diff";
CM_ SG_ 257 FD14_Ft_RrTrqCoupling_ModeRq_B2 "ESP Requested Center Differential State";
CM_ SG_ 257 FD14_Inlet_Pressure_Pos "Inlet Pressure Pos Indicates if the secondary brake control module detects upstream brake pressure";
CM_ SG_ 257 FD14_LHF_FastPulseCounter_B2 "LHF_FastPulseCounter_B2";
CM_ SG_ 257 FD14_LHF_Spin_B2 "LHF_Spin_B2";
CM_ SG_ 257 FD14_LHF_WheelSensorFailSts_B2 "LHF_WheelSensorFailSts_B2";
CM_ SG_ 257 FD14_LHFWheelSpeed_B2 "LHFWheelSpeed_B2";
CM_ SG_ 257 FD14_MessageCounter_BRAKE2_1 "This signal is a counter used for safety checks strategies. This counter is incremented of 1 (one) unit at each frame transmission.";
CM_ SG_ 257 FD14_R_DIFF_TRQ_RQ_B2 "Desired Torque for Rear Diff.";
CM_ SG_ 257 FD14_Rear_Diff_BSM_RQ_B2 "ESP Requested Rear Differential State";
CM_ SG_ 257 FD14_RHF_FastPulseCounter_B2 "RHF_FastPulseCounter_B2";
CM_ SG_ 257 FD14_RHF_Spin_B2 "RHF_Spin_B2";
CM_ SG_ 257 FD14_RHF_WheelSensorFailSts_B2 "RHF_WheelSensorFailSts_B2";
CM_ SG_ 257 FD14_RHFWheelSpeed_B2 "RHFWheelSpeed_B2";
CM_ SG_ 257 FD14_VehicleSpeedVSOSig_B2 "VehicleSpeedVSOSig_B2";
CM_ SG_ 524 FD14_AEB_Type_Brk_B2 "AEB_Type_Brk_B2";
CM_ SG_ 524 FD14_Brake_OpStat_Sec "Capability of the Braking system to perform deceleration and/or stability control as reported by the secondary actuator.";
CM_ SG_ 524 FD14_BrkTrq_B2 "BrkTrq_B2";
CM_ SG_ 524 FD14_BSM2_HEALTH_CHECK "BSM2_HEALTH_CHECK";
CM_ SG_ 524 FD14_BSM2_OpStat "Capability of the secondary brake control module to provide deceleration and/or stability control";
CM_ SG_ 524 FD14_CRC_BRAKE2_2 "CRC according to SAE J1850 standard at each frame transmission.";
CM_ SG_ 524 FD14_MessageCounter_BRAKE2_2 "This signal is a counter used for safety checks strategies. This counter is incremented of 1 (one) unit at each frame transmission.";
CM_ SG_ 524 FD14_VehicleStandStillSts_B2 "VehicleStandStillSts_B2";
CM_ SG_ 1156 FD14_ABSFailSts_B2 "ABSFailSts_B2";
CM_ SG_ 1156 FD14_CRC_BRAKE2_3 "CRC according to SAE J1850 standard at each frame transmission.";
CM_ SG_ 1156 FD14_MessageCounter_BRAKE2_3 "This signal is a counter used for safety checks strategies. This counter is incremented of 1 (one) unit at each frame transmission.";
CM_ SG_ 1156 FD14_RollsModeAct_B2 "RollsModeAct_B2";
CM_ SG_ 275 FD14_CRC_CVPAM_FD_Control "CRC according to SAE J1850 standard at each frame transmission.";
CM_ SG_ 275 FD14_ManoeuvrePhase "It indicates the vehicle movement estimated by SPM during semiautomatic parking manoeuvre.";
CM_ SG_ 275 FD14_MessageCounter_CVPAM_FD_Con "This signal is a counter used for safety checks strategies. This counter is incremented of 1 (one) unit at each frame transmission.";
CM_ SG_ 275 FD14_ParkingGearShiftReq "CVPAM Request to autonomously shift gears";
CM_ SG_ 275 FD14_PPPA_AccelMax "Maximum acceleration during a fully autonomous parking maneuver";
CM_ SG_ 275 FD14_PPPA_AccelMin "Minimum acceleration during a fully autonomous parking maneuver";
CM_ SG_ 275 FD14_PPPA_DecelMax "Maximum deceleration (absolute value) during a fully autonomous parking maneuver";
CM_ SG_ 275 FD14_PPPA_DecelMin "Minimum deceleration (absolute value) during a fully autonomous parking maneuver";
CM_ SG_ 275 FD14_PPPA_Interface_BSM "Fully Autonomous Parking Interface status with CVPAM and BSM";
CM_ SG_ 275 FD14_PPPA_JerkAccelMax "Maximum accelerating jerk rate during a fully autonomous parking maneuver";
CM_ SG_ 275 FD14_PPPA_JerkAccelMin "Minimum accelerating jerk rate during a fully autonomous parking maneuver";
CM_ SG_ 275 FD14_PPPA_JerkDecelMax "Maximum decelerating jerk rate (absolute value) during a fully autonomous parking maneuver";
CM_ SG_ 275 FD14_PPPA_JerkDecelMin "Minimum decelerating jerk rate (absolute value) during a fully autonomous parking maneuver";
CM_ SG_ 275 FD14_PPPA_StandstillRqst "Request for vehicle standstill";
CM_ SG_ 275 FD14_RR_PAM_Brk_RqSts "PAM rear brake request";
CM_ SG_ 275 FD14_RR_PAM_Dist "Rear Distance to Nearest Obstacle";
CM_ SG_ 275 FD14_SPM_Lat_Ctrl_RequestSts "SPM Lat Ctrl Request Sts";
CM_ SG_ 275 FD14_TorqueOverlaySteeringReq_SP "This signal indicates the value of the torque requested by the SPM torque overlay.";
CM_ SG_ 950 FD14_CRC_CVPAM_FD_Info "CRC according to SAE J1850 standard at each frame transmission.";
CM_ SG_ 950 FD14_MessageCounter_CVPAM_FD_Inf "This signal is a counter used for safety checks strategies. This counter is incremented of 1 (one) unit at each frame transmission.";
CM_ SG_ 950 FD14_ParkingManeuverActive "Parking information active";
CM_ SG_ 1054 FD14_CRC_ENGINE1 "CRC according to SAE J1850 standard at each frame transmission.";
CM_ SG_ 1054 FD14_MessageCounter_ENGINE1 "This signal is a counter used for safety checks strategies. This counter is incremented of 1 (one) unit at each frame transmission.";
CM_ SG_ 1054 FD14_ThermalManagementActive_W "-";
CM_ SG_ 262 FD14_CRC_ENGINE2 "CRC according to SAE J1850 standard at each frame transmission.";
CM_ SG_ 262 FD14_ECM_LHOM_W "-";
CM_ SG_ 262 FD14_EngineSpeed_W "It gives information on C-CAN network about  engine speed";
CM_ SG_ 262 FD14_EngineSts_W "-";
CM_ SG_ 262 FD14_ESS_ENG_ST_W "ESS Engine State";
CM_ SG_ 262 FD14_GasPedalPosition_W "-";
CM_ SG_ 262 FD14_GasPedalPositionFailSts_W "-";
CM_ SG_ 262 FD14_LV12PwrFreeRq_W "-";
CM_ SG_ 262 FD14_MessageCounter_ENGINE2 "This signal is a counter used for safety checks strategies. This counter is incremented of 1 (one) unit at each frame transmission.";
CM_ SG_ 262 FD14_PowertrainPrplsnActv "Powertrain Propulsion Status.";
CM_ SG_ 1036 FD14_CRC_ENGINE3 "CRC according to SAE J1850 standard at each frame transmission.";
CM_ SG_ 1036 FD14_MessageCounter_ENGINE3 "This signal is a counter used for safety checks strategies. This counter is incremented of 1 (one) unit at each frame transmission.";
CM_ SG_ 518 FD14_CRC_ENGINE5 "CRC according to SAE J1850 standard at each frame transmission.";
CM_ SG_ 518 FD14_MessageCounter_ENGINE5 "This signal is a counter used for safety checks strategies. This counter is incremented of 1 (one) unit at each frame transmission.";
CM_ SG_ 518 FD14_PdlPosActual "Actual pedal position.";
CM_ SG_ 518 FD14_RPMOverRev_W "-";
CM_ SG_ 1448 FD14_CRC_ENGINE7 "CRC according to SAE J1850 standard at each frame transmission.";
CM_ SG_ 1448 FD14_ECM_THA_Resp "ECM speed limiting availability response for trailer hitch assist";
CM_ SG_ 1448 FD14_ECM_TRSC_Resp "Engine break activation response";
CM_ SG_ 1448 FD14_MessageCounter_ENGINE7 "This signal is a counter used for safety checks strategies. This counter is incremented of 1 (one) unit at each frame transmission.";
CM_ SG_ 264 FD14_CRC_EPS1 "CRC according to SAE J1850 standard at each frame transmission.";
CM_ SG_ 264 FD14_ElectricSteeringFailSts "It indicates if system EPS has an internal fault.";
CM_ SG_ 264 FD14_EngineFanRequestActivation "This signal is used to activate the cooling fun by the electric power steering.";
CM_ SG_ 264 FD14_EPS_ADAS_IMC_Fault "Status of the EPS Intra-Module Communciation channel as reported by the primary EPS unit";
CM_ SG_ 264 FD14_EPS_AsstStat "Electric Power Steering Assistance Status";
CM_ SG_ 264 FD14_EPS_Curr "Electric power steering current";
CM_ SG_ 264 FD14_EPS_Hands_On_Sts "EPS Hands on steering wheel status; Hands on steering wheel detected = [1]";
CM_ SG_ 264 FD14_EPS_HandsOnRecognition "EPS Hands On Recognition";
CM_ SG_ 264 FD14_EPSMotorTorque "It represents the torque on the EPS motor output shaft at all times";
CM_ SG_ 264 FD14_ESA_LAT_CTRL_ResponseSts "ESA Lateral Response Status";
CM_ SG_ 264 FD14_HAS_LAT_CTRL_ResponseSts "HAS LAT CTRL Response Sts";
CM_ SG_ 264 FD14_LKA_LAT_CTRL_ResponseSts "LKA LAT CTRL Response Sts";
CM_ SG_ 264 FD14_LwsAngle "This signal indicates the steering angle value, counterclockwise positive.";
CM_ SG_ 264 FD14_LwsAngleType "This signal indicates whether the angle sensor is absolute (all the possible turns/degrees) or not absolute (relative, torque only, etc.).";
CM_ SG_ 264 FD14_LwsCalibration "This signal indicates if the sensor has been calibrated and therefore the steering angle value is exported over Can.";
CM_ SG_ 264 FD14_LwsSpeed "This signal indicates the steering speed value, counterclockwise positive.";
CM_ SG_ 264 FD14_MessageCounter_EPS1 "This signal is a counter used for safety checks strategies. This counter is incremented of 1 (one) unit at each frame transmission.";
CM_ SG_ 264 FD14_SPM_Lat_Ctrl_ResponseSts "SPM Lat Ctrl Response Sts";
CM_ SG_ 264 FD14_Steering_Column_Torque "Steering Column Torque";
CM_ SG_ 264 FD14_Steering_OpStat_Prim "Capability of the Steering system to steer the vehicle as reported by primary actuator";
CM_ SG_ 264 FD14_SteeringVibration_Fault "EPS Steering Wheel vibration fault status";
CM_ SG_ 264 FD14_SteeringVibration_Status "EPS Steering Wheel vibration status";
CM_ SG_ 1056 FD14_CRC_EPS2 "CRC according to SAE J1850 standard at each frame transmission.";
CM_ SG_ 1056 FD14_EPS_MODE_STAT "EPS mode personalization status";
CM_ SG_ 1056 FD14_EPS_SteeringTouchStat "EPS Driver interference during the TRSC event; True = [1] , False= [0]";
CM_ SG_ 1056 FD14_EPS_SteeringTouq_Resp "EPS steering torque overlay activation response";
CM_ SG_ 1056 FD14_EPS_THA_DriverTorqueOverrid "Determines if EPS driver torque on hand wheel is large enough to  override THA";
CM_ SG_ 1056 FD14_EPS_THA_SteeringTorqueResp "EPS steering torque overlay availability response for trailer hitch assist";
CM_ SG_ 1056 FD14_EPS_Warn_Disp_Rq "Electric Power Steering Warning Display Request";
CM_ SG_ 1056 FD14_MessageCounter_EPS2 "This signal is a counter used for safety checks strategies. This counter is incremented of 1 (one) unit at each frame transmission.";
CM_ SG_ 1056 FD14_THA_SteeringTouchStat "EPS hands on status for trailer hitch assist";
CM_ SG_ 1626 FD14_IMPACT_B "EARS Rear Event";
CM_ SG_ 1626 FD14_IMPACT_C "EARS Higher Severity Front Event";
CM_ SG_ 1626 FD14_IMPACT_F "EARS Lower Severity Front Event";
CM_ SG_ 1626 FD14_IMPACT_I "EARS RolloverEvent";
CM_ SG_ 1626 FD14_IMPACT_K "EARS Driver/Left Side Event";
CM_ SG_ 1626 FD14_IMPACT_M "EARS Passenger/Right Side Event";
CM_ SG_ 1626 FD14_IMPACTCommand "This signal is used to indicate that a crash happened";
CM_ SG_ 1626 FD14_IMPACTConfirm "This signal is used to confirm that a crash happened";
CM_ SG_ 1626 FD14_IMPACTFailSts "This signal is used to inform that an internal fault is present in the ORC";
CM_ SG_ 1626 FD14_IMPACTThreshold "Upon a crash, the ORC Calibration Threshold was either \"Met\" or \"Not_Met\".";
CM_ SG_ 2654486534 FD14_CBV_bit0_RepeatMessageReque "Repeat Message Request Bit";
CM_ SG_ 2654486534 FD14_CBV_bit3_NMCoordinatorBit "NM Coordinator Sleep Bit";
CM_ SG_ 2654486534 FD14_CBV_bit4_ActiveWakeupBit "Active Wakeup Bit";
CM_ SG_ 2654486534 FD14_CBV_bit6_PartialNtwInfBit "Partial Network Information Bit (PNI)";
CM_ SG_ 2654486534 FD14_SourceNodeIdentifier "Source Node Identifier";
CM_ SG_ 2654486676 FD14_CBV_bit0_RepeatMessage_0000 "Repeat Message Request Bit";
CM_ SG_ 2654486676 FD14_CBV_bit3_NMCoordinatorBit "NM Coordinator Sleep Bit";
CM_ SG_ 2654486676 FD14_CBV_bit4_ActiveWakeupBit "Active Wakeup Bit";
CM_ SG_ 2654486676 FD14_CBV_bit6_PartialNtwInfBit "Partial Network Information Bit (PNI)";
CM_ SG_ 2654486676 FD14_SourceNodeIdentifier "Source Node Identifier";
CM_ SG_ 2654486669 FD14_CBV_bit0_RepeatMessage_0001 "Repeat Message Request Bit";
CM_ SG_ 2654486669 FD14_CBV_bit3_NMCoordinatorBit "NM Coordinator Sleep Bit";
CM_ SG_ 2654486669 FD14_CBV_bit4_ActiveWakeupBit "Active Wakeup Bit";
CM_ SG_ 2654486669 FD14_CBV_bit6_PartialNtwInfBit "Partial Network Information Bit (PNI)";
CM_ SG_ 2654486669 FD14_SourceNodeIdentifier "Source Node Identifier";
CM_ SG_ 2654486529 FD14_CBV_bit0_RepeatMessage_0002 "Repeat Message Request Bit";
CM_ SG_ 2654486529 FD14_CBV_bit3_NMCoordinatorBit "NM Coordinator Sleep Bit";
CM_ SG_ 2654486529 FD14_CBV_bit4_ActiveWakeupBit "Active Wakeup Bit";
CM_ SG_ 2654486529 FD14_CBV_bit6_PartialNtwInfBit "Partial Network Information Bit (PNI)";
CM_ SG_ 2654486529 FD14_SourceNodeIdentifier "Source Node Identifier";
CM_ SG_ 2654486530 FD14_CBV_bit0_RepeatMessage_0003 "Repeat Message Request Bit";
CM_ SG_ 2654486530 FD14_CBV_bit3_NMCoordinatorBit "NM Coordinator Sleep Bit";
CM_ SG_ 2654486530 FD14_CBV_bit4_ActiveWakeupBit "Active Wakeup Bit";
CM_ SG_ 2654486530 FD14_CBV_bit6_PartialNtwInfBit "Partial Network Information Bit (PNI)";
CM_ SG_ 2654486530 FD14_SourceNodeIdentifier "Source Node Identifier";
CM_ SG_ 2654486554 FD14_CBV_bit0_RepeatMessage_0004 "Repeat Message Request Bit";
CM_ SG_ 2654486554 FD14_CBV_bit3_NMCoordinatorBit "NM Coordinator Sleep Bit";
CM_ SG_ 2654486554 FD14_CBV_bit4_ActiveWakeupBit "Active Wakeup Bit";
CM_ SG_ 2654486554 FD14_CBV_bit6_PartialNtwInfBit "Partial Network Information Bit (PNI)";
CM_ SG_ 2654486554 FD14_SourceNodeIdentifier "Source Node Identifier";
CM_ SG_ 2654486552 FD14_CBV_bit0_RepeatMessage_0005 "Repeat Message Request Bit";
CM_ SG_ 2654486552 FD14_CBV_bit3_NMCoordinatorBit "NM Coordinator Sleep Bit";
CM_ SG_ 2654486552 FD14_CBV_bit4_ActiveWakeupBit "Active Wakeup Bit";
CM_ SG_ 2654486552 FD14_CBV_bit6_PartialNtwInfBit "Partial Network Information Bit (PNI)";
CM_ SG_ 2654486552 FD14_SourceNodeIdentifier "Source Node Identifier";
CM_ SG_ 611 FD14_CRC_ORC1 "CRC according to SAE J1850 standard at each frame transmission.";
CM_ SG_ 611 FD14_MessageCounter_ORC1 "This signal is a counter used for safety checks strategies. This counter is incremented of 1 (one) unit at each frame transmission.";
CM_ SG_ 611 FD14_SBR1RowDriverSeatSts "First row driver seatbelt switch status";
CM_ SG_ 1954 FD14_CRC_ORC2 "CRC according to SAE J1850 standard at each frame transmission.";
CM_ SG_ 1954 FD14_MessageCounter_ORC2 "This signal is a counter used for safety checks strategies. This counter is incremented of 1 (one) unit at each frame transmission.";
CM_ SG_ 1954 FD14_ORCIdentification "ORC identification number.";
CM_ SG_ 274 FD14_CRC_ORC3 "CRC according to SAE J1850 standard at each frame transmission.";
CM_ SG_ 274 FD14_InternalError "This signal indicates if an internal error has been processed";
CM_ SG_ 274 FD14_LatAcceleration "This signal indicates the Lateral Acceleration Value";
CM_ SG_ 274 FD14_LatAccelerationFailSts "This signal indicates the status of Lateral Acceleration Signal";
CM_ SG_ 274 FD14_LongAcceleration "This signal indicates the Longitudinal Acceleration Value";
CM_ SG_ 274 FD14_LongAccelerationFailSts "This signal indicates the status of Longitudinal acceleration signal";
CM_ SG_ 274 FD14_MessageCounter_ORC3 "This signal is a counter used for safety checks strategies. This counter is incremented of 1 (one) unit at each frame transmission.";
CM_ SG_ 274 FD14_YawRate "This signal indicates the Yaw Rate Value";
CM_ SG_ 274 FD14_YawRate_HR "Yaw Rate Additional signal for high resolution.";
CM_ SG_ 274 FD14_YawRate_HR_Sign "Sign of High resolution Yaw Rate signal. 0 = Negative [-]. 1 = Positive [+].";
CM_ SG_ 274 FD14_YawRateFailSts "This signal indicates the Status of Yaw Rate Signal";
CM_ SG_ 255 FD14_ACC_NCC_TrqEnblRq_Allowed "ACC/NCC Torque request allowed. True =[1]";
CM_ SG_ 255 FD14_Accel_Pedal_Override "Driver Accelerator Pedal Override. True =[1]";
CM_ SG_ 255 FD14_CRC_PT_TORQUE_FD_1 "CRC according to SAE J1850 standard at each frame transmission.";
CM_ SG_ 255 FD14_ESC_TrqEnblRq_Allowed "ESC Torque request allowed. True =[1]";
CM_ SG_ 255 FD14_MessageCounter_PT_TORQUE_FD "This signal is a counter used for safety checks strategies. This counter is incremented of 1 (one) unit at each frame transmission.";
CM_ SG_ 255 FD14_PPPA_TrqEnblRq_Allowed "PPPA Torque request allowed. True =[1]";
CM_ SG_ 255 FD14_SSC_TrqEnblRq_Allowed "SCC Torque request allowed. True =[1]";
CM_ SG_ 255 FD14_SumTorque_DrvReqMod "Driver requested sum torque modified";
CM_ SG_ 255 FD14_SumTorqueExp "Expected sum torque based on target transmission input speed";
CM_ SG_ 255 FD14_SumTorqueMax "Maximum sum torque";
CM_ SG_ 255 FD14_SumTorqueMin "Minimum sum torque";
CM_ SG_ 255 FD14_SumTorqueSel_D_TTC "Corrected (substitute) driver torque demand";
CM_ SG_ 255 FD14_SumTorqueStatic "Static sum torque (effective sum torque)";
CM_ SG_ 255 FD14_Total_AxleTorque_Static "Static Axle Torque (effective total Axle torque)";
CM_ SG_ 1472 FD14_CRC_TRSCM1 "CRC according to SAE J1850 standard at each frame transmission.";
CM_ SG_ 1472 FD14_MessageCounter_TRSCM1 "This signal is a counter used for safety checks strategies. This counter is incremented of 1 (one) unit at each frame transmission.";
CM_ SG_ 1472 FD14_THA_EPB_Req "THA EPB securement request";
CM_ SG_ 1472 FD14_THA_Speed_Limit "THA Speed Limiter Threshold";
CM_ SG_ 1472 FD14_THA_SpeedLimit_Req "THA requested speed limit";
CM_ SG_ 1472 FD14_THA_STAT "Current trailer hitch assist maneuver state";
CM_ SG_ 1472 FD14_THA_SteeringDamping "THA Steering Damping";
CM_ SG_ 1472 FD14_THA_SteeringTorqueInfo "THA Steering Torque";
CM_ SG_ 1472 FD14_THA_SteeringTorqueReq "Trailer Hitch Assist steering torque request";
CM_ SG_ 1472 FD14_TRSC_SpeedLimit_Req "TRSC ECM Speed limit request";
CM_ SG_ 1472 FD14_TRSC_STAT "Trailer Reverse steering status signal";
CM_ SG_ 1472 FD14_TRSC_SteeringDamping "TRSC Steering damping percentage";
CM_ SG_ 1472 FD14_TRSC_SteeringTorqueInfo "TRSC Steering Torque";
CM_ SG_ 1472 FD14_TRSC_SteeringTorqueReq "TRSC steering torque overlay activation request";
CM_ SG_ 1472 FD14_TRSC_VehicleStop_Req "TRSC break activation request";
BA_DEF_ SG_  "GenSigStartValue" INT 0 2147483647;
BA_DEF_ SG_  "GenSigInactiveValue" INT 0 2147483647;
BA_DEF_ SG_  "GenSigSendType" ENUM  "NotUsed","OnWrite","OnWriteWithRepetition","OnChange","OnChangeWithRepetition","IfActive","IfActiveWithRepetition","NoSigSendType";
BA_DEF_ SG_  "GenSigTimeoutTime_BSM" INT 0 65535;
BA_DEF_ SG_  "GenSigTimeoutTime_BSM2" INT 0 65535;
BA_DEF_ SG_  "GenSigTimeoutTime_CADM" INT 0 65535;
BA_DEF_ SG_  "GenSigTimeoutTime_CVADAS" INT 0 65535;
BA_DEF_ SG_  "GenSigTimeoutTime_ECM" INT 0 65535;
BA_DEF_ SG_  "GenSigTimeoutTime_EPS" INT 0 65535;
BA_DEF_ SG_  "GenSigTimeoutTime_EVCU2" INT 0 65535;
BA_DEF_ SG_  "GenSigTimeoutTime_ORC" INT 0 65535;
BA_DEF_ BO_  "DiagRequest" ENUM  "No","Yes";
BA_DEF_ BO_  "Type" ENUM  "P","C","PE","COC","PE_Cntrl","E","E_Cntrl","OC","S","BAF","DC","EM","MM","ISO-TP","-";
BA_DEF_ BO_  "DiagResponse" ENUM  "No","Yes";
BA_DEF_ BO_  "NmMessage" ENUM  "No","Yes";
BA_DEF_ BO_  "GenMsgSendType" ENUM  "Cyclic","NotUsed","NotUsed","NotUsed","NotUsed","NotUsed","NotUsed","NotUsed","NoMsgSendType";
BA_DEF_ BO_  "GenMsgNrOfRepetition" INT 0 255;
BA_DEF_ BO_  "GenMsgILSupport" ENUM  "No","Yes";
BA_DEF_ BO_  "GenMsgCycleTimeFast" INT 0 65535;
BA_DEF_ BO_  "GenMsgCycleTime" INT 0 65535;
BA_DEF_ BO_  "GenMsgDelayTime" INT 0 65535;
BA_DEF_ BO_  "NmAsrMessage" ENUM  "No","Yes";
BA_DEF_ BO_  "DiagState" ENUM  "No","Yes";
BA_DEF_ BO_  "DiagConnection" HEX 0 65535;
BA_DEF_ BO_  "VFrameFormat" ENUM  "StandardCAN","ExtendedCAN","reserved","reserved","reserved","reserved","reserved","reserved","reserved","reserved","reserved","reserved","reserved","reserved","StandardCAN_FD","ExtendedCAN_FD";
BA_DEF_ BO_  "CANFD_BRS" ENUM  "No","Yes";
BA_DEF_ SG_  "SystemSignalLongSymbol" STRING ;
BA_DEF_DEF_  "GenSigStartValue" 0;
BA_DEF_DEF_  "GenSigInactiveValue" 0;
BA_DEF_DEF_  "GenSigSendType" "NoSigSendType";
BA_DEF_DEF_  "GenSigTimeoutTime_BSM" 2500;
BA_DEF_DEF_  "GenSigTimeoutTime_BSM2" 2500;
BA_DEF_DEF_  "GenSigTimeoutTime_CADM" 2500;
BA_DEF_DEF_  "GenSigTimeoutTime_CVADAS" 2500;
BA_DEF_DEF_  "GenSigTimeoutTime_ECM" 2500;
BA_DEF_DEF_  "GenSigTimeoutTime_EPS" 2500;
BA_DEF_DEF_  "GenSigTimeoutTime_EVCU2" 2500;
BA_DEF_DEF_  "GenSigTimeoutTime_ORC" 2500;
BA_DEF_DEF_  "DiagRequest" "No";
BA_DEF_DEF_  "Type" "-";
BA_DEF_DEF_  "DiagResponse" "No";
BA_DEF_DEF_  "NmMessage" "No";
BA_DEF_DEF_  "GenMsgSendType" "NoMsgSendType";
BA_DEF_DEF_  "GenMsgNrOfRepetition" 0;
BA_DEF_DEF_  "GenMsgILSupport" "No";
BA_DEF_DEF_  "GenMsgCycleTimeFast" 0;
BA_DEF_DEF_  "GenMsgCycleTime" 0;
BA_DEF_DEF_  "GenMsgDelayTime" 0;
BA_DEF_DEF_  "NmAsrMessage" "No";
BA_DEF_DEF_  "DiagState" "No";
BA_DEF_DEF_  "DiagConnection" 0;
BA_DEF_DEF_  "VFrameFormat" "StandardCAN_FD";
BA_DEF_DEF_  "CANFD_BRS" "No";
BA_DEF_DEF_  "SystemSignalLongSymbol" "";
BA_ "Type" BO_ 609 3;
BA_ "GenMsgSendType" BO_ 609 0;
BA_ "GenMsgNrOfRepetition" BO_ 609 2;
BA_ "GenMsgILSupport" BO_ 609 1;
BA_ "GenMsgCycleTimeFast" BO_ 609 20;
BA_ "GenMsgCycleTime" BO_ 609 100;
BA_ "CANFD_BRS" BO_ 609 1;
BA_ "Type" BO_ 1155 3;
BA_ "GenMsgSendType" BO_ 1155 0;
BA_ "GenMsgNrOfRepetition" BO_ 1155 2;
BA_ "GenMsgILSupport" BO_ 1155 1;
BA_ "GenMsgCycleTimeFast" BO_ 1155 20;
BA_ "GenMsgCycleTime" BO_ 1155 500;
BA_ "GenMsgDelayTime" BO_ 1155 20;
BA_ "CANFD_BRS" BO_ 1155 1;
BA_ "Type" BO_ 205 1;
BA_ "GenMsgSendType" BO_ 205 0;
BA_ "GenMsgILSupport" BO_ 205 1;
BA_ "GenMsgCycleTime" BO_ 205 10;
BA_ "CANFD_BRS" BO_ 205 1;
BA_ "Type" BO_ 514 1;
BA_ "GenMsgSendType" BO_ 514 0;
BA_ "GenMsgILSupport" BO_ 514 1;
BA_ "GenMsgCycleTime" BO_ 514 20;
BA_ "CANFD_BRS" BO_ 514 1;
BA_ "Type" BO_ 257 1;
BA_ "GenMsgSendType" BO_ 257 0;
BA_ "GenMsgILSupport" BO_ 257 1;
BA_ "GenMsgCycleTime" BO_ 257 10;
BA_ "CANFD_BRS" BO_ 257 1;
BA_ "Type" BO_ 524 1;
BA_ "GenMsgSendType" BO_ 524 0;
BA_ "GenMsgILSupport" BO_ 524 1;
BA_ "GenMsgCycleTime" BO_ 524 20;
BA_ "CANFD_BRS" BO_ 524 1;
BA_ "Type" BO_ 1156 3;
BA_ "GenMsgSendType" BO_ 1156 0;
BA_ "GenMsgNrOfRepetition" BO_ 1156 2;
BA_ "GenMsgILSupport" BO_ 1156 1;
BA_ "GenMsgCycleTimeFast" BO_ 1156 20;
BA_ "GenMsgCycleTime" BO_ 1156 500;
BA_ "GenMsgDelayTime" BO_ 1156 20;
BA_ "CANFD_BRS" BO_ 1156 1;
BA_ "Type" BO_ 275 1;
BA_ "GenMsgSendType" BO_ 275 0;
BA_ "GenMsgILSupport" BO_ 275 1;
BA_ "GenMsgCycleTime" BO_ 275 10;
BA_ "CANFD_BRS" BO_ 275 1;
BA_ "Type" BO_ 950 3;
BA_ "GenMsgSendType" BO_ 950 0;
BA_ "GenMsgILSupport" BO_ 950 1;
BA_ "GenMsgCycleTime" BO_ 950 250;
BA_ "CANFD_BRS" BO_ 950 1;
BA_ "Type" BO_ 1054 1;
BA_ "GenMsgSendType" BO_ 1054 0;
BA_ "GenMsgILSupport" BO_ 1054 1;
BA_ "GenMsgCycleTime" BO_ 1054 100;
BA_ "CANFD_BRS" BO_ 1054 1;
BA_ "Type" BO_ 262 1;
BA_ "GenMsgSendType" BO_ 262 0;
BA_ "GenMsgILSupport" BO_ 262 1;
BA_ "GenMsgCycleTime" BO_ 262 10;
BA_ "CANFD_BRS" BO_ 262 1;
BA_ "Type" BO_ 1036 3;
BA_ "GenMsgSendType" BO_ 1036 0;
BA_ "GenMsgNrOfRepetition" BO_ 1036 2;
BA_ "GenMsgILSupport" BO_ 1036 1;
BA_ "GenMsgCycleTimeFast" BO_ 1036 20;
BA_ "GenMsgCycleTime" BO_ 1036 100;
BA_ "GenMsgDelayTime" BO_ 1036 20;
BA_ "CANFD_BRS" BO_ 1036 1;
BA_ "Type" BO_ 518 1;
BA_ "GenMsgSendType" BO_ 518 0;
BA_ "GenMsgILSupport" BO_ 518 1;
BA_ "GenMsgCycleTime" BO_ 518 20;
BA_ "CANFD_BRS" BO_ 518 1;
BA_ "Type" BO_ 1448 3;
BA_ "GenMsgSendType" BO_ 1448 0;
BA_ "GenMsgNrOfRepetition" BO_ 1448 2;
BA_ "GenMsgILSupport" BO_ 1448 1;
BA_ "GenMsgCycleTimeFast" BO_ 1448 20;
BA_ "GenMsgCycleTime" BO_ 1448 1000;
BA_ "GenMsgDelayTime" BO_ 1448 20;
BA_ "CANFD_BRS" BO_ 1448 1;
BA_ "Type" BO_ 264 1;
BA_ "GenMsgSendType" BO_ 264 0;
BA_ "GenMsgILSupport" BO_ 264 1;
BA_ "GenMsgCycleTime" BO_ 264 10;
BA_ "CANFD_BRS" BO_ 264 1;
BA_ "Type" BO_ 1056 1;
BA_ "GenMsgSendType" BO_ 1056 0;
BA_ "GenMsgILSupport" BO_ 1056 1;
BA_ "GenMsgCycleTime" BO_ 1056 100;
BA_ "CANFD_BRS" BO_ 1056 1;
BA_ "Type" BO_ 1626 10;
BA_ "GenMsgSendType" BO_ 1626 0;
BA_ "GenMsgILSupport" BO_ 1626 1;
BA_ "GenMsgCycleTimeFast" BO_ 1626 10;
BA_ "GenMsgCycleTime" BO_ 1626 500;
BA_ "CANFD_BRS" BO_ 1626 1;
BA_ "Type" BO_ 2654486534 8;
BA_ "NmMessage" BO_ 2654486534 1;
BA_ "NmAsrMessage" BO_ 2654486534 1;
BA_ "CANFD_BRS" BO_ 2654486534 1;
BA_ "VFrameFormat" BO_ 2654486534 15;
BA_ "Type" BO_ 2654486676 8;
BA_ "NmMessage" BO_ 2654486676 1;
BA_ "NmAsrMessage" BO_ 2654486676 1;
BA_ "CANFD_BRS" BO_ 2654486676 1;
BA_ "VFrameFormat" BO_ 2654486676 15;
BA_ "Type" BO_ 2654486669 8;
BA_ "NmMessage" BO_ 2654486669 1;
BA_ "NmAsrMessage" BO_ 2654486669 1;
BA_ "CANFD_BRS" BO_ 2654486669 1;
BA_ "VFrameFormat" BO_ 2654486669 15;
BA_ "Type" BO_ 2654486529 8;
BA_ "NmMessage" BO_ 2654486529 1;
BA_ "NmAsrMessage" BO_ 2654486529 1;
BA_ "CANFD_BRS" BO_ 2654486529 1;
BA_ "VFrameFormat" BO_ 2654486529 15;
BA_ "Type" BO_ 2654486530 8;
BA_ "NmMessage" BO_ 2654486530 1;
BA_ "NmAsrMessage" BO_ 2654486530 1;
BA_ "CANFD_BRS" BO_ 2654486530 1;
BA_ "VFrameFormat" BO_ 2654486530 15;
BA_ "Type" BO_ 2654486554 8;
BA_ "NmMessage" BO_ 2654486554 1;
BA_ "NmAsrMessage" BO_ 2654486554 1;
BA_ "CANFD_BRS" BO_ 2654486554 1;
BA_ "VFrameFormat" BO_ 2654486554 15;
BA_ "Type" BO_ 2654486552 8;
BA_ "NmMessage" BO_ 2654486552 1;
BA_ "NmAsrMessage" BO_ 2654486552 1;
BA_ "CANFD_BRS" BO_ 2654486552 1;
BA_ "VFrameFormat" BO_ 2654486552 15;
BA_ "Type" BO_ 611 3;
BA_ "GenMsgSendType" BO_ 611 0;
BA_ "GenMsgILSupport" BO_ 611 1;
BA_ "GenMsgCycleTime" BO_ 611 100;
BA_ "GenMsgDelayTime" BO_ 611 20;
BA_ "CANFD_BRS" BO_ 611 1;
BA_ "Type" BO_ 1954 3;
BA_ "GenMsgSendType" BO_ 1954 0;
BA_ "GenMsgILSupport" BO_ 1954 1;
BA_ "GenMsgCycleTime" BO_ 1954 1000;
BA_ "CANFD_BRS" BO_ 1954 1;
BA_ "Type" BO_ 274 1;
BA_ "GenMsgSendType" BO_ 274 0;
BA_ "GenMsgILSupport" BO_ 274 1;
BA_ "GenMsgCycleTime" BO_ 274 10;
BA_ "CANFD_BRS" BO_ 274 1;
BA_ "Type" BO_ 255 1;
BA_ "GenMsgSendType" BO_ 255 0;
BA_ "GenMsgILSupport" BO_ 255 1;
BA_ "GenMsgCycleTime" BO_ 255 10;
BA_ "CANFD_BRS" BO_ 255 1;
BA_ "Type" BO_ 1472 3;
BA_ "GenMsgSendType" BO_ 1472 0;
BA_ "GenMsgILSupport" BO_ 1472 1;
BA_ "GenMsgCycleTime" BO_ 1472 1000;
BA_ "GenMsgDelayTime" BO_ 1472 20;
BA_ "CANFD_BRS" BO_ 1472 1;
BA_ "GenSigSendType" SG_ 609 FD14_ASRActive 3;
BA_ "GenSigTimeoutTime_BSM" SG_ 609 FD14_ASRActive 0;
BA_ "GenSigTimeoutTime_BSM2" SG_ 609 FD14_ASRActive 0;
BA_ "GenSigTimeoutTime_CADM" SG_ 609 FD14_ASRActive 0;
BA_ "GenSigTimeoutTime_CVADAS" SG_ 609 FD14_ASRActive 0;
BA_ "GenSigTimeoutTime_ECM" SG_ 609 FD14_ASRActive 0;
BA_ "GenSigTimeoutTime_EPS" SG_ 609 FD14_ASRActive 0;
BA_ "GenSigTimeoutTime_ORC" SG_ 609 FD14_ASRActive 0;
BA_ "GenSigTimeoutTime_BSM" SG_ 609 FD14_BSM_LnchAbrtSts 0;
BA_ "GenSigTimeoutTime_BSM2" SG_ 609 FD14_BSM_LnchAbrtSts 0;
BA_ "GenSigTimeoutTime_CADM" SG_ 609 FD14_BSM_LnchAbrtSts 0;
BA_ "GenSigTimeoutTime_CVADAS" SG_ 609 FD14_BSM_LnchAbrtSts 0;
BA_ "GenSigTimeoutTime_ECM" SG_ 609 FD14_BSM_LnchAbrtSts 0;
BA_ "GenSigTimeoutTime_EPS" SG_ 609 FD14_BSM_LnchAbrtSts 0;
BA_ "GenSigTimeoutTime_ORC" SG_ 609 FD14_BSM_LnchAbrtSts 0;
BA_ "GenSigTimeoutTime_BSM" SG_ 609 FD14_BSM_LnchCtrl_SftBtn_SelectS 0;
BA_ "GenSigTimeoutTime_BSM2" SG_ 609 FD14_BSM_LnchCtrl_SftBtn_SelectS 0;
BA_ "GenSigTimeoutTime_CADM" SG_ 609 FD14_BSM_LnchCtrl_SftBtn_SelectS 0;
BA_ "GenSigTimeoutTime_CVADAS" SG_ 609 FD14_BSM_LnchCtrl_SftBtn_SelectS 0;
BA_ "GenSigTimeoutTime_ECM" SG_ 609 FD14_BSM_LnchCtrl_SftBtn_SelectS 0;
BA_ "GenSigTimeoutTime_EPS" SG_ 609 FD14_BSM_LnchCtrl_SftBtn_SelectS 0;
BA_ "GenSigTimeoutTime_ORC" SG_ 609 FD14_BSM_LnchCtrl_SftBtn_SelectS 0;
BA_ "SystemSignalLongSymbol" SG_ 609 FD14_BSM_LnchCtrl_SftBtn_SelectS "FD14_BSM_LnchCtrl_SftBtn_SelectSts";
BA_ "GenSigTimeoutTime_BSM" SG_ 609 FD14_BSM_LnchMode 0;
BA_ "GenSigTimeoutTime_BSM2" SG_ 609 FD14_BSM_LnchMode 0;
BA_ "GenSigTimeoutTime_CADM" SG_ 609 FD14_BSM_LnchMode 0;
BA_ "GenSigTimeoutTime_CVADAS" SG_ 609 FD14_BSM_LnchMode 0;
BA_ "GenSigTimeoutTime_ECM" SG_ 609 FD14_BSM_LnchMode 0;
BA_ "GenSigTimeoutTime_EPS" SG_ 609 FD14_BSM_LnchMode 0;
BA_ "GenSigTimeoutTime_ORC" SG_ 609 FD14_BSM_LnchMode 0;
BA_ "GenSigTimeoutTime_BSM" SG_ 609 FD14_CRC_BRAKE4 0;
BA_ "GenSigTimeoutTime_BSM2" SG_ 609 FD14_CRC_BRAKE4 0;
BA_ "GenSigTimeoutTime_CVADAS" SG_ 609 FD14_CRC_BRAKE4 0;
BA_ "GenSigTimeoutTime_ECM" SG_ 609 FD14_CRC_BRAKE4 0;
BA_ "GenSigTimeoutTime_EPS" SG_ 609 FD14_CRC_BRAKE4 0;
BA_ "GenSigTimeoutTime_ORC" SG_ 609 FD14_CRC_BRAKE4 0;
BA_ "GenSigSendType" SG_ 609 FD14_EPBSts 3;
BA_ "GenSigTimeoutTime_BSM" SG_ 609 FD14_EPBSts 0;
BA_ "GenSigTimeoutTime_BSM2" SG_ 609 FD14_EPBSts 0;
BA_ "GenSigTimeoutTime_ECM" SG_ 609 FD14_EPBSts 0;
BA_ "GenSigTimeoutTime_EPS" SG_ 609 FD14_EPBSts 0;
BA_ "GenSigTimeoutTime_ORC" SG_ 609 FD14_EPBSts 0;
BA_ "GenSigTimeoutTime_BSM" SG_ 609 FD14_ESC_OFF_Hrd_Sft_Button_sts 0;
BA_ "GenSigTimeoutTime_BSM2" SG_ 609 FD14_ESC_OFF_Hrd_Sft_Button_sts 0;
BA_ "GenSigTimeoutTime_CADM" SG_ 609 FD14_ESC_OFF_Hrd_Sft_Button_sts 0;
BA_ "GenSigTimeoutTime_CVADAS" SG_ 609 FD14_ESC_OFF_Hrd_Sft_Button_sts 0;
BA_ "GenSigTimeoutTime_ECM" SG_ 609 FD14_ESC_OFF_Hrd_Sft_Button_sts 0;
BA_ "GenSigTimeoutTime_EPS" SG_ 609 FD14_ESC_OFF_Hrd_Sft_Button_sts 0;
BA_ "GenSigTimeoutTime_ORC" SG_ 609 FD14_ESC_OFF_Hrd_Sft_Button_sts 0;
BA_ "GenSigTimeoutTime_BSM" SG_ 609 FD14_LaunchRPMsetting_BSM 0;
BA_ "GenSigTimeoutTime_BSM2" SG_ 609 FD14_LaunchRPMsetting_BSM 0;
BA_ "GenSigTimeoutTime_CADM" SG_ 609 FD14_LaunchRPMsetting_BSM 0;
BA_ "GenSigTimeoutTime_CVADAS" SG_ 609 FD14_LaunchRPMsetting_BSM 0;
BA_ "GenSigTimeoutTime_ECM" SG_ 609 FD14_LaunchRPMsetting_BSM 0;
BA_ "GenSigTimeoutTime_EPS" SG_ 609 FD14_LaunchRPMsetting_BSM 0;
BA_ "GenSigTimeoutTime_ORC" SG_ 609 FD14_LaunchRPMsetting_BSM 0;
BA_ "GenSigTimeoutTime_BSM" SG_ 609 FD14_MessageCounter_BRAKE4 0;
BA_ "GenSigTimeoutTime_BSM2" SG_ 609 FD14_MessageCounter_BRAKE4 0;
BA_ "GenSigTimeoutTime_CVADAS" SG_ 609 FD14_MessageCounter_BRAKE4 0;
BA_ "GenSigTimeoutTime_ECM" SG_ 609 FD14_MessageCounter_BRAKE4 0;
BA_ "GenSigTimeoutTime_EPS" SG_ 609 FD14_MessageCounter_BRAKE4 0;
BA_ "GenSigTimeoutTime_ORC" SG_ 609 FD14_MessageCounter_BRAKE4 0;
BA_ "GenSigSendType" SG_ 609 FD14_MSRActive 3;
BA_ "GenSigTimeoutTime_BSM" SG_ 609 FD14_MSRActive 0;
BA_ "GenSigTimeoutTime_BSM2" SG_ 609 FD14_MSRActive 0;
BA_ "GenSigTimeoutTime_CADM" SG_ 609 FD14_MSRActive 0;
BA_ "GenSigTimeoutTime_CVADAS" SG_ 609 FD14_MSRActive 0;
BA_ "GenSigTimeoutTime_ECM" SG_ 609 FD14_MSRActive 0;
BA_ "GenSigTimeoutTime_EPS" SG_ 609 FD14_MSRActive 0;
BA_ "GenSigTimeoutTime_ORC" SG_ 609 FD14_MSRActive 0;
BA_ "GenSigTimeoutTime_BSM" SG_ 609 FD14_TravelDistance 0;
BA_ "GenSigTimeoutTime_BSM2" SG_ 609 FD14_TravelDistance 0;
BA_ "GenSigTimeoutTime_CADM" SG_ 609 FD14_TravelDistance 0;
BA_ "GenSigTimeoutTime_CVADAS" SG_ 609 FD14_TravelDistance 0;
BA_ "GenSigTimeoutTime_ECM" SG_ 609 FD14_TravelDistance 0;
BA_ "GenSigTimeoutTime_EPS" SG_ 609 FD14_TravelDistance 0;
BA_ "GenSigTimeoutTime_ORC" SG_ 609 FD14_TravelDistance 0;
BA_ "GenSigSendType" SG_ 1155 FD14_ABSFailSts 3;
BA_ "GenSigTimeoutTime_BSM" SG_ 1155 FD14_ABSFailSts 0;
BA_ "GenSigTimeoutTime_BSM2" SG_ 1155 FD14_ABSFailSts 0;
BA_ "GenSigTimeoutTime_CADM" SG_ 1155 FD14_ABSFailSts 0;
BA_ "GenSigTimeoutTime_CVADAS" SG_ 1155 FD14_ABSFailSts 0;
BA_ "GenSigTimeoutTime_EPS" SG_ 1155 FD14_ABSFailSts 0;
BA_ "GenSigTimeoutTime_ORC" SG_ 1155 FD14_ABSFailSts 0;
BA_ "GenSigSendType" SG_ 1155 FD14_ACCEngaged 3;
BA_ "GenSigTimeoutTime_BSM" SG_ 1155 FD14_ACCEngaged 0;
BA_ "GenSigTimeoutTime_BSM2" SG_ 1155 FD14_ACCEngaged 0;
BA_ "GenSigTimeoutTime_CADM" SG_ 1155 FD14_ACCEngaged 0;
BA_ "GenSigTimeoutTime_CVADAS" SG_ 1155 FD14_ACCEngaged 0;
BA_ "GenSigTimeoutTime_ECM" SG_ 1155 FD14_ACCEngaged 0;
BA_ "GenSigTimeoutTime_EPS" SG_ 1155 FD14_ACCEngaged 0;
BA_ "GenSigTimeoutTime_ORC" SG_ 1155 FD14_ACCEngaged 0;
BA_ "GenSigSendType" SG_ 1155 FD14_BSM_THA_Brk_Resp 4;
BA_ "GenSigTimeoutTime_BSM" SG_ 1155 FD14_BSM_THA_Brk_Resp 0;
BA_ "GenSigTimeoutTime_BSM2" SG_ 1155 FD14_BSM_THA_Brk_Resp 0;
BA_ "GenSigTimeoutTime_CADM" SG_ 1155 FD14_BSM_THA_Brk_Resp 0;
BA_ "GenSigTimeoutTime_ECM" SG_ 1155 FD14_BSM_THA_Brk_Resp 0;
BA_ "GenSigTimeoutTime_EPS" SG_ 1155 FD14_BSM_THA_Brk_Resp 0;
BA_ "GenSigTimeoutTime_ORC" SG_ 1155 FD14_BSM_THA_Brk_Resp 0;
BA_ "GenSigSendType" SG_ 1155 FD14_BSMSysSts 3;
BA_ "GenSigTimeoutTime_BSM" SG_ 1155 FD14_BSMSysSts 0;
BA_ "GenSigTimeoutTime_BSM2" SG_ 1155 FD14_BSMSysSts 0;
BA_ "GenSigTimeoutTime_CVADAS" SG_ 1155 FD14_BSMSysSts 0;
BA_ "GenSigTimeoutTime_ECM" SG_ 1155 FD14_BSMSysSts 0;
BA_ "GenSigTimeoutTime_EPS" SG_ 1155 FD14_BSMSysSts 0;
BA_ "GenSigTimeoutTime_ORC" SG_ 1155 FD14_BSMSysSts 0;
BA_ "GenSigSendType" SG_ 1155 FD14_CMMIntervention 3;
BA_ "GenSigTimeoutTime_BSM" SG_ 1155 FD14_CMMIntervention 0;
BA_ "GenSigTimeoutTime_BSM2" SG_ 1155 FD14_CMMIntervention 0;
BA_ "GenSigTimeoutTime_CADM" SG_ 1155 FD14_CMMIntervention 0;
BA_ "GenSigTimeoutTime_CVADAS" SG_ 1155 FD14_CMMIntervention 0;
BA_ "GenSigTimeoutTime_ECM" SG_ 1155 FD14_CMMIntervention 0;
BA_ "GenSigTimeoutTime_EPS" SG_ 1155 FD14_CMMIntervention 0;
BA_ "GenSigTimeoutTime_ORC" SG_ 1155 FD14_CMMIntervention 0;
BA_ "GenSigTimeoutTime_BSM" SG_ 1155 FD14_CRC_BRAKE5 0;
BA_ "GenSigTimeoutTime_EPS" SG_ 1155 FD14_CRC_BRAKE5 0;
BA_ "GenSigTimeoutTime_ORC" SG_ 1155 FD14_CRC_BRAKE5 0;
BA_ "GenSigSendType" SG_ 1155 FD14_EBDFailSts 3;
BA_ "GenSigTimeoutTime_BSM" SG_ 1155 FD14_EBDFailSts 0;
BA_ "GenSigTimeoutTime_BSM2" SG_ 1155 FD14_EBDFailSts 0;
BA_ "GenSigTimeoutTime_CADM" SG_ 1155 FD14_EBDFailSts 0;
BA_ "GenSigTimeoutTime_CVADAS" SG_ 1155 FD14_EBDFailSts 0;
BA_ "GenSigTimeoutTime_ECM" SG_ 1155 FD14_EBDFailSts 0;
BA_ "GenSigTimeoutTime_EPS" SG_ 1155 FD14_EBDFailSts 0;
BA_ "GenSigTimeoutTime_ORC" SG_ 1155 FD14_EBDFailSts 0;
BA_ "GenSigSendType" SG_ 1155 FD14_ERMActive 3;
BA_ "GenSigTimeoutTime_BSM" SG_ 1155 FD14_ERMActive 0;
BA_ "GenSigTimeoutTime_BSM2" SG_ 1155 FD14_ERMActive 0;
BA_ "GenSigTimeoutTime_CADM" SG_ 1155 FD14_ERMActive 0;
BA_ "GenSigTimeoutTime_CVADAS" SG_ 1155 FD14_ERMActive 0;
BA_ "GenSigTimeoutTime_ECM" SG_ 1155 FD14_ERMActive 0;
BA_ "GenSigTimeoutTime_EPS" SG_ 1155 FD14_ERMActive 0;
BA_ "GenSigTimeoutTime_ORC" SG_ 1155 FD14_ERMActive 0;
BA_ "GenSigSendType" SG_ 1155 FD14_ESC_TRSC_Brk_Resp 3;
BA_ "GenSigTimeoutTime_BSM" SG_ 1155 FD14_ESC_TRSC_Brk_Resp 0;
BA_ "GenSigTimeoutTime_BSM2" SG_ 1155 FD14_ESC_TRSC_Brk_Resp 0;
BA_ "GenSigTimeoutTime_CADM" SG_ 1155 FD14_ESC_TRSC_Brk_Resp 0;
BA_ "GenSigTimeoutTime_ECM" SG_ 1155 FD14_ESC_TRSC_Brk_Resp 0;
BA_ "GenSigTimeoutTime_EPS" SG_ 1155 FD14_ESC_TRSC_Brk_Resp 0;
BA_ "GenSigTimeoutTime_ORC" SG_ 1155 FD14_ESC_TRSC_Brk_Resp 0;
BA_ "GenSigSendType" SG_ 1155 FD14_ESCFailSts 3;
BA_ "GenSigTimeoutTime_BSM" SG_ 1155 FD14_ESCFailSts 0;
BA_ "GenSigTimeoutTime_BSM2" SG_ 1155 FD14_ESCFailSts 0;
BA_ "GenSigTimeoutTime_CVADAS" SG_ 1155 FD14_ESCFailSts 0;
BA_ "GenSigTimeoutTime_ECM" SG_ 1155 FD14_ESCFailSts 0;
BA_ "GenSigTimeoutTime_EPS" SG_ 1155 FD14_ESCFailSts 0;
BA_ "GenSigTimeoutTime_ORC" SG_ 1155 FD14_ESCFailSts 0;
BA_ "GenSigSendType" SG_ 1155 FD14_Function2Sts 3;
BA_ "GenSigTimeoutTime_BSM" SG_ 1155 FD14_Function2Sts 0;
BA_ "GenSigTimeoutTime_BSM2" SG_ 1155 FD14_Function2Sts 0;
BA_ "GenSigTimeoutTime_CADM" SG_ 1155 FD14_Function2Sts 0;
BA_ "GenSigTimeoutTime_CVADAS" SG_ 1155 FD14_Function2Sts 0;
BA_ "GenSigTimeoutTime_ECM" SG_ 1155 FD14_Function2Sts 0;
BA_ "GenSigTimeoutTime_EPS" SG_ 1155 FD14_Function2Sts 0;
BA_ "GenSigTimeoutTime_ORC" SG_ 1155 FD14_Function2Sts 0;
BA_ "GenSigSendType" SG_ 1155 FD14_FunctionFailSts 3;
BA_ "GenSigTimeoutTime_BSM" SG_ 1155 FD14_FunctionFailSts 0;
BA_ "GenSigTimeoutTime_BSM2" SG_ 1155 FD14_FunctionFailSts 0;
BA_ "GenSigTimeoutTime_CADM" SG_ 1155 FD14_FunctionFailSts 0;
BA_ "GenSigTimeoutTime_CVADAS" SG_ 1155 FD14_FunctionFailSts 0;
BA_ "GenSigTimeoutTime_ECM" SG_ 1155 FD14_FunctionFailSts 0;
BA_ "GenSigTimeoutTime_EPS" SG_ 1155 FD14_FunctionFailSts 0;
BA_ "GenSigTimeoutTime_ORC" SG_ 1155 FD14_FunctionFailSts 0;
BA_ "GenSigSendType" SG_ 1155 FD14_FunctionIntervention 3;
BA_ "GenSigTimeoutTime_BSM" SG_ 1155 FD14_FunctionIntervention 0;
BA_ "GenSigTimeoutTime_BSM2" SG_ 1155 FD14_FunctionIntervention 0;
BA_ "GenSigTimeoutTime_CADM" SG_ 1155 FD14_FunctionIntervention 0;
BA_ "GenSigTimeoutTime_CVADAS" SG_ 1155 FD14_FunctionIntervention 0;
BA_ "GenSigTimeoutTime_ECM" SG_ 1155 FD14_FunctionIntervention 0;
BA_ "GenSigTimeoutTime_EPS" SG_ 1155 FD14_FunctionIntervention 0;
BA_ "GenSigTimeoutTime_ORC" SG_ 1155 FD14_FunctionIntervention 0;
BA_ "GenSigSendType" SG_ 1155 FD14_FunctionSts 3;
BA_ "GenSigTimeoutTime_BSM" SG_ 1155 FD14_FunctionSts 0;
BA_ "GenSigTimeoutTime_BSM2" SG_ 1155 FD14_FunctionSts 0;
BA_ "GenSigTimeoutTime_CVADAS" SG_ 1155 FD14_FunctionSts 0;
BA_ "GenSigTimeoutTime_ECM" SG_ 1155 FD14_FunctionSts 0;
BA_ "GenSigTimeoutTime_EPS" SG_ 1155 FD14_FunctionSts 0;
BA_ "GenSigTimeoutTime_ORC" SG_ 1155 FD14_FunctionSts 0;
BA_ "GenSigTimeoutTime_BSM" SG_ 1155 FD14_MessageCounter_BRAKE5 0;
BA_ "GenSigTimeoutTime_EPS" SG_ 1155 FD14_MessageCounter_BRAKE5 0;
BA_ "GenSigTimeoutTime_ORC" SG_ 1155 FD14_MessageCounter_BRAKE5 0;
BA_ "GenSigSendType" SG_ 1155 FD14_RollsModeAct 3;
BA_ "GenSigTimeoutTime_BSM" SG_ 1155 FD14_RollsModeAct 0;
BA_ "GenSigTimeoutTime_CVADAS" SG_ 1155 FD14_RollsModeAct 0;
BA_ "GenSigTimeoutTime_ECM" SG_ 1155 FD14_RollsModeAct 0;
BA_ "GenSigTimeoutTime_EPS" SG_ 1155 FD14_RollsModeAct 0;
BA_ "GenSigTimeoutTime_ORC" SG_ 1155 FD14_RollsModeAct 0;
BA_ "GenSigSendType" SG_ 1155 FD14_TSCActive 3;
BA_ "GenSigTimeoutTime_BSM" SG_ 1155 FD14_TSCActive 0;
BA_ "GenSigTimeoutTime_BSM2" SG_ 1155 FD14_TSCActive 0;
BA_ "GenSigTimeoutTime_CADM" SG_ 1155 FD14_TSCActive 0;
BA_ "GenSigTimeoutTime_CVADAS" SG_ 1155 FD14_TSCActive 0;
BA_ "GenSigTimeoutTime_ECM" SG_ 1155 FD14_TSCActive 0;
BA_ "GenSigTimeoutTime_EPS" SG_ 1155 FD14_TSCActive 0;
BA_ "GenSigTimeoutTime_ORC" SG_ 1155 FD14_TSCActive 0;
BA_ "GenSigTimeoutTime_BSM" SG_ 205 FD14_CRC_BRAKE_FD_6 0;
BA_ "GenSigTimeoutTime_BSM2" SG_ 205 FD14_CRC_BRAKE_FD_6 0;
BA_ "GenSigTimeoutTime_CADM" SG_ 205 FD14_CRC_BRAKE_FD_6 0;
BA_ "GenSigTimeoutTime_CVADAS" SG_ 205 FD14_CRC_BRAKE_FD_6 0;
BA_ "GenSigTimeoutTime_EPS" SG_ 205 FD14_CRC_BRAKE_FD_6 0;
BA_ "GenSigTimeoutTime_ORC" SG_ 205 FD14_CRC_BRAKE_FD_6 0;
BA_ "GenSigTimeoutTime_BSM" SG_ 205 FD14_DriverReq_AxleTrq_Enabled_B 0;
BA_ "GenSigTimeoutTime_BSM2" SG_ 205 FD14_DriverReq_AxleTrq_Enabled_B 0;
BA_ "GenSigTimeoutTime_CADM" SG_ 205 FD14_DriverReq_AxleTrq_Enabled_B 0;
BA_ "GenSigTimeoutTime_EPS" SG_ 205 FD14_DriverReq_AxleTrq_Enabled_B 0;
BA_ "GenSigTimeoutTime_ORC" SG_ 205 FD14_DriverReq_AxleTrq_Enabled_B 0;
BA_ "SystemSignalLongSymbol" SG_ 205 FD14_DriverReq_AxleTrq_Enabled_B "FD14_DriverReq_AxleTrq_Enabled_BSM";
BA_ "GenSigStartValue" SG_ 205 FD14_DriverRequested_AxleTrq_BSM 32767;
BA_ "GenSigTimeoutTime_BSM" SG_ 205 FD14_DriverRequested_AxleTrq_BSM 0;
BA_ "GenSigTimeoutTime_BSM2" SG_ 205 FD14_DriverRequested_AxleTrq_BSM 0;
BA_ "GenSigTimeoutTime_CADM" SG_ 205 FD14_DriverRequested_AxleTrq_BSM 0;
BA_ "GenSigTimeoutTime_CVADAS" SG_ 205 FD14_DriverRequested_AxleTrq_BSM 0;
BA_ "GenSigTimeoutTime_EPS" SG_ 205 FD14_DriverRequested_AxleTrq_BSM 0;
BA_ "GenSigTimeoutTime_ORC" SG_ 205 FD14_DriverRequested_AxleTrq_BSM 0;
BA_ "GenSigTimeoutTime_BSM" SG_ 205 FD14_MessageCounter_BRAKE_FD_6 0;
BA_ "GenSigTimeoutTime_BSM2" SG_ 205 FD14_MessageCounter_BRAKE_FD_6 0;
BA_ "GenSigTimeoutTime_CADM" SG_ 205 FD14_MessageCounter_BRAKE_FD_6 0;
BA_ "GenSigTimeoutTime_CVADAS" SG_ 205 FD14_MessageCounter_BRAKE_FD_6 0;
BA_ "GenSigTimeoutTime_EPS" SG_ 205 FD14_MessageCounter_BRAKE_FD_6 0;
BA_ "GenSigTimeoutTime_ORC" SG_ 205 FD14_MessageCounter_BRAKE_FD_6 0;
BA_ "GenSigTimeoutTime_BSM" SG_ 205 FD14_TotalAxle_Max_Rq_BSM 0;
BA_ "GenSigTimeoutTime_BSM2" SG_ 205 FD14_TotalAxle_Max_Rq_BSM 0;
BA_ "GenSigTimeoutTime_CADM" SG_ 205 FD14_TotalAxle_Max_Rq_BSM 0;
BA_ "GenSigTimeoutTime_CVADAS" SG_ 205 FD14_TotalAxle_Max_Rq_BSM 0;
BA_ "GenSigTimeoutTime_EPS" SG_ 205 FD14_TotalAxle_Max_Rq_BSM 0;
BA_ "GenSigTimeoutTime_ORC" SG_ 205 FD14_TotalAxle_Max_Rq_BSM 0;
BA_ "GenSigTimeoutTime_BSM" SG_ 205 FD14_TotalAxle_Min_Rq_BSM 0;
BA_ "GenSigTimeoutTime_BSM2" SG_ 205 FD14_TotalAxle_Min_Rq_BSM 0;
BA_ "GenSigTimeoutTime_CADM" SG_ 205 FD14_TotalAxle_Min_Rq_BSM 0;
BA_ "GenSigTimeoutTime_CVADAS" SG_ 205 FD14_TotalAxle_Min_Rq_BSM 0;
BA_ "GenSigTimeoutTime_EPS" SG_ 205 FD14_TotalAxle_Min_Rq_BSM 0;
BA_ "GenSigTimeoutTime_ORC" SG_ 205 FD14_TotalAxle_Min_Rq_BSM 0;
BA_ "GenSigStartValue" SG_ 205 FD14_TotalAxle_Rq_BSM 32767;
BA_ "GenSigTimeoutTime_BSM" SG_ 205 FD14_TotalAxle_Rq_BSM 0;
BA_ "GenSigTimeoutTime_BSM2" SG_ 205 FD14_TotalAxle_Rq_BSM 0;
BA_ "GenSigTimeoutTime_CADM" SG_ 205 FD14_TotalAxle_Rq_BSM 0;
BA_ "GenSigTimeoutTime_CVADAS" SG_ 205 FD14_TotalAxle_Rq_BSM 0;
BA_ "GenSigTimeoutTime_EPS" SG_ 205 FD14_TotalAxle_Rq_BSM 0;
BA_ "GenSigTimeoutTime_ORC" SG_ 205 FD14_TotalAxle_Rq_BSM 0;
BA_ "GenSigTimeoutTime_BSM" SG_ 514 FD14_AEB_Type_Brk 0;
BA_ "GenSigTimeoutTime_CVADAS" SG_ 514 FD14_AEB_Type_Brk 0;
BA_ "GenSigTimeoutTime_ECM" SG_ 514 FD14_AEB_Type_Brk 0;
BA_ "GenSigTimeoutTime_EPS" SG_ 514 FD14_AEB_Type_Brk 0;
BA_ "GenSigTimeoutTime_BSM" SG_ 514 FD14_Brake_OpStat_Prim 0;
BA_ "GenSigTimeoutTime_BSM2" SG_ 514 FD14_Brake_OpStat_Prim 0;
BA_ "GenSigTimeoutTime_CVADAS" SG_ 514 FD14_Brake_OpStat_Prim 0;
BA_ "GenSigTimeoutTime_ECM" SG_ 514 FD14_Brake_OpStat_Prim 0;
BA_ "GenSigTimeoutTime_EPS" SG_ 514 FD14_Brake_OpStat_Prim 0;
BA_ "GenSigTimeoutTime_BSM" SG_ 514 FD14_BrakePdlPosn 0;
BA_ "GenSigTimeoutTime_CVADAS" SG_ 514 FD14_BrakePdlPosn 0;
BA_ "GenSigTimeoutTime_ECM" SG_ 514 FD14_BrakePdlPosn 0;
BA_ "GenSigTimeoutTime_EPS" SG_ 514 FD14_BrakePdlPosn 0;
BA_ "GenSigTimeoutTime_ORC" SG_ 514 FD14_BrakePdlPosn 0;
BA_ "GenSigTimeoutTime_BSM" SG_ 514 FD14_BrkPdl_Flt 0;
BA_ "GenSigTimeoutTime_BSM2" SG_ 514 FD14_BrkPdl_Flt 0;
BA_ "GenSigTimeoutTime_CVADAS" SG_ 514 FD14_BrkPdl_Flt 0;
BA_ "GenSigTimeoutTime_ECM" SG_ 514 FD14_BrkPdl_Flt 0;
BA_ "GenSigTimeoutTime_EPS" SG_ 514 FD14_BrkPdl_Flt 0;
BA_ "GenSigTimeoutTime_ORC" SG_ 514 FD14_BrkPdl_Flt 0;
BA_ "GenSigStartValue" SG_ 514 FD14_BrkPdl_Stat 3;
BA_ "GenSigTimeoutTime_BSM" SG_ 514 FD14_BrkPdl_Stat 0;
BA_ "GenSigTimeoutTime_EPS" SG_ 514 FD14_BrkPdl_Stat 0;
BA_ "GenSigTimeoutTime_ORC" SG_ 514 FD14_BrkPdl_Stat 0;
BA_ "GenSigTimeoutTime_BSM" SG_ 514 FD14_BSM_HEALTH_CHECK 0;
BA_ "GenSigTimeoutTime_CADM" SG_ 514 FD14_BSM_HEALTH_CHECK 0;
BA_ "GenSigTimeoutTime_CVADAS" SG_ 514 FD14_BSM_HEALTH_CHECK 0;
BA_ "GenSigTimeoutTime_ECM" SG_ 514 FD14_BSM_HEALTH_CHECK 0;
BA_ "GenSigTimeoutTime_EPS" SG_ 514 FD14_BSM_HEALTH_CHECK 0;
BA_ "GenSigTimeoutTime_ORC" SG_ 514 FD14_BSM_HEALTH_CHECK 0;
BA_ "GenSigTimeoutTime_BSM" SG_ 514 FD14_BSM_OpStat 0;
BA_ "GenSigTimeoutTime_CVADAS" SG_ 514 FD14_BSM_OpStat 0;
BA_ "GenSigTimeoutTime_ECM" SG_ 514 FD14_BSM_OpStat 0;
BA_ "GenSigTimeoutTime_EPS" SG_ 514 FD14_BSM_OpStat 0;
BA_ "GenSigTimeoutTime_ORC" SG_ 514 FD14_BSM_OpStat 0;
BA_ "GenSigTimeoutTime_BSM" SG_ 514 FD14_CRC_BRAKE7 0;
BA_ "GenSigTimeoutTime_CVADAS" SG_ 514 FD14_CRC_BRAKE7 0;
BA_ "GenSigTimeoutTime_ECM" SG_ 514 FD14_CRC_BRAKE7 0;
BA_ "GenSigTimeoutTime_EPS" SG_ 514 FD14_CRC_BRAKE7 0;
BA_ "GenSigTimeoutTime_ORC" SG_ 514 FD14_CRC_BRAKE7 0;
BA_ "GenSigTimeoutTime_BSM" SG_ 514 FD14_MessageCounter_BRAKE7 0;
BA_ "GenSigTimeoutTime_CVADAS" SG_ 514 FD14_MessageCounter_BRAKE7 0;
BA_ "GenSigTimeoutTime_ECM" SG_ 514 FD14_MessageCounter_BRAKE7 0;
BA_ "GenSigTimeoutTime_EPS" SG_ 514 FD14_MessageCounter_BRAKE7 0;
BA_ "GenSigTimeoutTime_ORC" SG_ 514 FD14_MessageCounter_BRAKE7 0;
BA_ "GenSigTimeoutTime_BSM" SG_ 514 FD14_PAM_Brk_Rq_RspSts 0;
BA_ "GenSigTimeoutTime_BSM2" SG_ 514 FD14_PAM_Brk_Rq_RspSts 0;
BA_ "GenSigTimeoutTime_CADM" SG_ 514 FD14_PAM_Brk_Rq_RspSts 0;
BA_ "GenSigTimeoutTime_ECM" SG_ 514 FD14_PAM_Brk_Rq_RspSts 0;
BA_ "GenSigTimeoutTime_EPS" SG_ 514 FD14_PAM_Brk_Rq_RspSts 0;
BA_ "GenSigTimeoutTime_ORC" SG_ 514 FD14_PAM_Brk_Rq_RspSts 0;
BA_ "GenSigTimeoutTime_BSM" SG_ 257 FD14_ABSActive_B2 0;
BA_ "GenSigTimeoutTime_BSM2" SG_ 257 FD14_ABSActive_B2 0;
BA_ "GenSigTimeoutTime_CVADAS" SG_ 257 FD14_ABSActive_B2 0;
BA_ "GenSigTimeoutTime_ECM" SG_ 257 FD14_ABSActive_B2 0;
BA_ "GenSigTimeoutTime_EPS" SG_ 257 FD14_ABSActive_B2 0;
BA_ "GenSigTimeoutTime_ORC" SG_ 257 FD14_ABSActive_B2 0;
BA_ "GenSigTimeoutTime_BSM" SG_ 257 FD14_Brk_Stat_B2 0;
BA_ "GenSigTimeoutTime_BSM2" SG_ 257 FD14_Brk_Stat_B2 0;
BA_ "GenSigTimeoutTime_CVADAS" SG_ 257 FD14_Brk_Stat_B2 0;
BA_ "GenSigTimeoutTime_ECM" SG_ 257 FD14_Brk_Stat_B2 0;
BA_ "GenSigTimeoutTime_EPS" SG_ 257 FD14_Brk_Stat_B2 0;
BA_ "GenSigTimeoutTime_ORC" SG_ 257 FD14_Brk_Stat_B2 0;
BA_ "GenSigTimeoutTime_BSM" SG_ 257 FD14_CRC_BRAKE2_1 0;
BA_ "GenSigTimeoutTime_BSM2" SG_ 257 FD14_CRC_BRAKE2_1 0;
BA_ "GenSigTimeoutTime_ECM" SG_ 257 FD14_CRC_BRAKE2_1 0;
BA_ "GenSigStartValue" SG_ 257 FD14_Ft_RrAxleCoupling_TrqRq_B2 254;
BA_ "GenSigTimeoutTime_BSM" SG_ 257 FD14_Ft_RrAxleCoupling_TrqRq_B2 0;
BA_ "GenSigTimeoutTime_BSM2" SG_ 257 FD14_Ft_RrAxleCoupling_TrqRq_B2 0;
BA_ "GenSigTimeoutTime_CADM" SG_ 257 FD14_Ft_RrAxleCoupling_TrqRq_B2 0;
BA_ "GenSigTimeoutTime_CVADAS" SG_ 257 FD14_Ft_RrAxleCoupling_TrqRq_B2 0;
BA_ "GenSigTimeoutTime_ECM" SG_ 257 FD14_Ft_RrAxleCoupling_TrqRq_B2 0;
BA_ "GenSigTimeoutTime_EPS" SG_ 257 FD14_Ft_RrAxleCoupling_TrqRq_B2 0;
BA_ "GenSigTimeoutTime_ORC" SG_ 257 FD14_Ft_RrAxleCoupling_TrqRq_B2 0;
BA_ "GenSigTimeoutTime_BSM" SG_ 257 FD14_Ft_RrTrqCoupling_ModeRq_B2 0;
BA_ "GenSigTimeoutTime_BSM2" SG_ 257 FD14_Ft_RrTrqCoupling_ModeRq_B2 0;
BA_ "GenSigTimeoutTime_CADM" SG_ 257 FD14_Ft_RrTrqCoupling_ModeRq_B2 0;
BA_ "GenSigTimeoutTime_CVADAS" SG_ 257 FD14_Ft_RrTrqCoupling_ModeRq_B2 0;
BA_ "GenSigTimeoutTime_ECM" SG_ 257 FD14_Ft_RrTrqCoupling_ModeRq_B2 0;
BA_ "GenSigTimeoutTime_EPS" SG_ 257 FD14_Ft_RrTrqCoupling_ModeRq_B2 0;
BA_ "GenSigTimeoutTime_ORC" SG_ 257 FD14_Ft_RrTrqCoupling_ModeRq_B2 0;
BA_ "GenSigTimeoutTime_BSM" SG_ 257 FD14_Inlet_Pressure_Pos 0;
BA_ "GenSigTimeoutTime_BSM2" SG_ 257 FD14_Inlet_Pressure_Pos 0;
BA_ "GenSigTimeoutTime_CVADAS" SG_ 257 FD14_Inlet_Pressure_Pos 0;
BA_ "GenSigTimeoutTime_ECM" SG_ 257 FD14_Inlet_Pressure_Pos 0;
BA_ "GenSigTimeoutTime_EPS" SG_ 257 FD14_Inlet_Pressure_Pos 0;
BA_ "GenSigTimeoutTime_ORC" SG_ 257 FD14_Inlet_Pressure_Pos 0;
BA_ "GenSigTimeoutTime_BSM" SG_ 257 FD14_LHF_FastPulseCounter_B2 0;
BA_ "GenSigTimeoutTime_BSM2" SG_ 257 FD14_LHF_FastPulseCounter_B2 0;
BA_ "GenSigTimeoutTime_CVADAS" SG_ 257 FD14_LHF_FastPulseCounter_B2 0;
BA_ "GenSigTimeoutTime_ECM" SG_ 257 FD14_LHF_FastPulseCounter_B2 0;
BA_ "GenSigTimeoutTime_EPS" SG_ 257 FD14_LHF_FastPulseCounter_B2 0;
BA_ "GenSigTimeoutTime_ORC" SG_ 257 FD14_LHF_FastPulseCounter_B2 0;
BA_ "GenSigTimeoutTime_BSM" SG_ 257 FD14_LHF_Spin_B2 0;
BA_ "GenSigTimeoutTime_BSM2" SG_ 257 FD14_LHF_Spin_B2 0;
BA_ "GenSigTimeoutTime_CVADAS" SG_ 257 FD14_LHF_Spin_B2 0;
BA_ "GenSigTimeoutTime_ECM" SG_ 257 FD14_LHF_Spin_B2 0;
BA_ "GenSigTimeoutTime_EPS" SG_ 257 FD14_LHF_Spin_B2 0;
BA_ "GenSigTimeoutTime_ORC" SG_ 257 FD14_LHF_Spin_B2 0;
BA_ "GenSigTimeoutTime_BSM" SG_ 257 FD14_LHF_WheelSensorFailSts_B2 0;
BA_ "GenSigTimeoutTime_BSM2" SG_ 257 FD14_LHF_WheelSensorFailSts_B2 0;
BA_ "GenSigTimeoutTime_CVADAS" SG_ 257 FD14_LHF_WheelSensorFailSts_B2 0;
BA_ "GenSigTimeoutTime_ECM" SG_ 257 FD14_LHF_WheelSensorFailSts_B2 0;
BA_ "GenSigTimeoutTime_EPS" SG_ 257 FD14_LHF_WheelSensorFailSts_B2 0;
BA_ "GenSigTimeoutTime_ORC" SG_ 257 FD14_LHF_WheelSensorFailSts_B2 0;
BA_ "GenSigTimeoutTime_BSM" SG_ 257 FD14_LHFWheelSpeed_B2 0;
BA_ "GenSigTimeoutTime_BSM2" SG_ 257 FD14_LHFWheelSpeed_B2 0;
BA_ "GenSigTimeoutTime_CVADAS" SG_ 257 FD14_LHFWheelSpeed_B2 0;
BA_ "GenSigTimeoutTime_ECM" SG_ 257 FD14_LHFWheelSpeed_B2 0;
BA_ "GenSigTimeoutTime_EPS" SG_ 257 FD14_LHFWheelSpeed_B2 0;
BA_ "GenSigTimeoutTime_ORC" SG_ 257 FD14_LHFWheelSpeed_B2 0;
BA_ "GenSigTimeoutTime_BSM" SG_ 257 FD14_MessageCounter_BRAKE2_1 0;
BA_ "GenSigTimeoutTime_BSM2" SG_ 257 FD14_MessageCounter_BRAKE2_1 0;
BA_ "GenSigTimeoutTime_ECM" SG_ 257 FD14_MessageCounter_BRAKE2_1 0;
BA_ "GenSigStartValue" SG_ 257 FD14_R_DIFF_TRQ_RQ_B2 511;
BA_ "GenSigTimeoutTime_BSM" SG_ 257 FD14_R_DIFF_TRQ_RQ_B2 0;
BA_ "GenSigTimeoutTime_BSM2" SG_ 257 FD14_R_DIFF_TRQ_RQ_B2 0;
BA_ "GenSigTimeoutTime_CADM" SG_ 257 FD14_R_DIFF_TRQ_RQ_B2 0;
BA_ "GenSigTimeoutTime_CVADAS" SG_ 257 FD14_R_DIFF_TRQ_RQ_B2 0;
BA_ "GenSigTimeoutTime_ECM" SG_ 257 FD14_R_DIFF_TRQ_RQ_B2 0;
BA_ "GenSigTimeoutTime_EPS" SG_ 257 FD14_R_DIFF_TRQ_RQ_B2 0;
BA_ "GenSigTimeoutTime_ORC" SG_ 257 FD14_R_DIFF_TRQ_RQ_B2 0;
BA_ "GenSigTimeoutTime_BSM" SG_ 257 FD14_Rear_Diff_BSM_RQ_B2 0;
BA_ "GenSigTimeoutTime_BSM2" SG_ 257 FD14_Rear_Diff_BSM_RQ_B2 0;
BA_ "GenSigTimeoutTime_CADM" SG_ 257 FD14_Rear_Diff_BSM_RQ_B2 0;
BA_ "GenSigTimeoutTime_CVADAS" SG_ 257 FD14_Rear_Diff_BSM_RQ_B2 0;
BA_ "GenSigTimeoutTime_ECM" SG_ 257 FD14_Rear_Diff_BSM_RQ_B2 0;
BA_ "GenSigTimeoutTime_EPS" SG_ 257 FD14_Rear_Diff_BSM_RQ_B2 0;
BA_ "GenSigTimeoutTime_ORC" SG_ 257 FD14_Rear_Diff_BSM_RQ_B2 0;
BA_ "GenSigTimeoutTime_BSM" SG_ 257 FD14_RHF_FastPulseCounter_B2 0;
BA_ "GenSigTimeoutTime_BSM2" SG_ 257 FD14_RHF_FastPulseCounter_B2 0;
BA_ "GenSigTimeoutTime_CVADAS" SG_ 257 FD14_RHF_FastPulseCounter_B2 0;
BA_ "GenSigTimeoutTime_ECM" SG_ 257 FD14_RHF_FastPulseCounter_B2 0;
BA_ "GenSigTimeoutTime_EPS" SG_ 257 FD14_RHF_FastPulseCounter_B2 0;
BA_ "GenSigTimeoutTime_ORC" SG_ 257 FD14_RHF_FastPulseCounter_B2 0;
BA_ "GenSigTimeoutTime_BSM" SG_ 257 FD14_RHF_Spin_B2 0;
BA_ "GenSigTimeoutTime_BSM2" SG_ 257 FD14_RHF_Spin_B2 0;
BA_ "GenSigTimeoutTime_CVADAS" SG_ 257 FD14_RHF_Spin_B2 0;
BA_ "GenSigTimeoutTime_ECM" SG_ 257 FD14_RHF_Spin_B2 0;
BA_ "GenSigTimeoutTime_EPS" SG_ 257 FD14_RHF_Spin_B2 0;
BA_ "GenSigTimeoutTime_ORC" SG_ 257 FD14_RHF_Spin_B2 0;
BA_ "GenSigTimeoutTime_BSM" SG_ 257 FD14_RHF_WheelSensorFailSts_B2 0;
BA_ "GenSigTimeoutTime_BSM2" SG_ 257 FD14_RHF_WheelSensorFailSts_B2 0;
BA_ "GenSigTimeoutTime_CVADAS" SG_ 257 FD14_RHF_WheelSensorFailSts_B2 0;
BA_ "GenSigTimeoutTime_ECM" SG_ 257 FD14_RHF_WheelSensorFailSts_B2 0;
BA_ "GenSigTimeoutTime_EPS" SG_ 257 FD14_RHF_WheelSensorFailSts_B2 0;
BA_ "GenSigTimeoutTime_ORC" SG_ 257 FD14_RHF_WheelSensorFailSts_B2 0;
BA_ "GenSigTimeoutTime_BSM" SG_ 257 FD14_RHFWheelSpeed_B2 0;
BA_ "GenSigTimeoutTime_BSM2" SG_ 257 FD14_RHFWheelSpeed_B2 0;
BA_ "GenSigTimeoutTime_CVADAS" SG_ 257 FD14_RHFWheelSpeed_B2 0;
BA_ "GenSigTimeoutTime_ECM" SG_ 257 FD14_RHFWheelSpeed_B2 0;
BA_ "GenSigTimeoutTime_EPS" SG_ 257 FD14_RHFWheelSpeed_B2 0;
BA_ "GenSigTimeoutTime_ORC" SG_ 257 FD14_RHFWheelSpeed_B2 0;
BA_ "GenSigTimeoutTime_BSM" SG_ 257 FD14_VehicleSpeedVSOSig_B2 0;
BA_ "GenSigTimeoutTime_BSM2" SG_ 257 FD14_VehicleSpeedVSOSig_B2 0;
BA_ "GenSigTimeoutTime_ECM" SG_ 257 FD14_VehicleSpeedVSOSig_B2 0;
BA_ "GenSigTimeoutTime_ORC" SG_ 257 FD14_VehicleSpeedVSOSig_B2 0;
BA_ "GenSigTimeoutTime_BSM" SG_ 524 FD14_AEB_Type_Brk_B2 0;
BA_ "GenSigTimeoutTime_BSM2" SG_ 524 FD14_AEB_Type_Brk_B2 0;
BA_ "GenSigTimeoutTime_CVADAS" SG_ 524 FD14_AEB_Type_Brk_B2 0;
BA_ "GenSigTimeoutTime_ECM" SG_ 524 FD14_AEB_Type_Brk_B2 0;
BA_ "GenSigTimeoutTime_EPS" SG_ 524 FD14_AEB_Type_Brk_B2 0;
BA_ "GenSigTimeoutTime_ORC" SG_ 524 FD14_AEB_Type_Brk_B2 0;
BA_ "GenSigTimeoutTime_BSM" SG_ 524 FD14_Brake_OpStat_Sec 0;
BA_ "GenSigTimeoutTime_BSM2" SG_ 524 FD14_Brake_OpStat_Sec 0;
BA_ "GenSigTimeoutTime_CVADAS" SG_ 524 FD14_Brake_OpStat_Sec 0;
BA_ "GenSigTimeoutTime_ECM" SG_ 524 FD14_Brake_OpStat_Sec 0;
BA_ "GenSigTimeoutTime_EPS" SG_ 524 FD14_Brake_OpStat_Sec 0;
BA_ "GenSigTimeoutTime_ORC" SG_ 524 FD14_Brake_OpStat_Sec 0;
BA_ "GenSigStartValue" SG_ 524 FD14_BrkTrq_B2 32767;
BA_ "GenSigTimeoutTime_BSM" SG_ 524 FD14_BrkTrq_B2 0;
BA_ "GenSigTimeoutTime_BSM2" SG_ 524 FD14_BrkTrq_B2 0;
BA_ "GenSigTimeoutTime_CVADAS" SG_ 524 FD14_BrkTrq_B2 0;
BA_ "GenSigTimeoutTime_ECM" SG_ 524 FD14_BrkTrq_B2 0;
BA_ "GenSigTimeoutTime_EPS" SG_ 524 FD14_BrkTrq_B2 0;
BA_ "GenSigTimeoutTime_ORC" SG_ 524 FD14_BrkTrq_B2 0;
BA_ "GenSigTimeoutTime_BSM2" SG_ 524 FD14_BSM2_HEALTH_CHECK 0;
BA_ "GenSigTimeoutTime_CADM" SG_ 524 FD14_BSM2_HEALTH_CHECK 0;
BA_ "GenSigTimeoutTime_CVADAS" SG_ 524 FD14_BSM2_HEALTH_CHECK 0;
BA_ "GenSigTimeoutTime_ECM" SG_ 524 FD14_BSM2_HEALTH_CHECK 0;
BA_ "GenSigTimeoutTime_EPS" SG_ 524 FD14_BSM2_HEALTH_CHECK 0;
BA_ "GenSigTimeoutTime_ORC" SG_ 524 FD14_BSM2_HEALTH_CHECK 0;
BA_ "GenSigTimeoutTime_BSM2" SG_ 524 FD14_BSM2_OpStat 0;
BA_ "GenSigTimeoutTime_CVADAS" SG_ 524 FD14_BSM2_OpStat 0;
BA_ "GenSigTimeoutTime_ECM" SG_ 524 FD14_BSM2_OpStat 0;
BA_ "GenSigTimeoutTime_EPS" SG_ 524 FD14_BSM2_OpStat 0;
BA_ "GenSigTimeoutTime_ORC" SG_ 524 FD14_BSM2_OpStat 0;
BA_ "GenSigTimeoutTime_BSM2" SG_ 524 FD14_CRC_BRAKE2_2 0;
BA_ "GenSigTimeoutTime_CVADAS" SG_ 524 FD14_CRC_BRAKE2_2 0;
BA_ "GenSigTimeoutTime_ECM" SG_ 524 FD14_CRC_BRAKE2_2 0;
BA_ "GenSigTimeoutTime_EPS" SG_ 524 FD14_CRC_BRAKE2_2 0;
BA_ "GenSigTimeoutTime_BSM2" SG_ 524 FD14_MessageCounter_BRAKE2_2 0;
BA_ "GenSigTimeoutTime_CVADAS" SG_ 524 FD14_MessageCounter_BRAKE2_2 0;
BA_ "GenSigTimeoutTime_ECM" SG_ 524 FD14_MessageCounter_BRAKE2_2 0;
BA_ "GenSigTimeoutTime_EPS" SG_ 524 FD14_MessageCounter_BRAKE2_2 0;
BA_ "GenSigStartValue" SG_ 524 FD14_VehicleStandStillSts_B2 1;
BA_ "GenSigTimeoutTime_BSM2" SG_ 524 FD14_VehicleStandStillSts_B2 0;
BA_ "GenSigTimeoutTime_CVADAS" SG_ 524 FD14_VehicleStandStillSts_B2 0;
BA_ "GenSigTimeoutTime_ECM" SG_ 524 FD14_VehicleStandStillSts_B2 0;
BA_ "GenSigTimeoutTime_EPS" SG_ 524 FD14_VehicleStandStillSts_B2 0;
BA_ "GenSigTimeoutTime_ORC" SG_ 524 FD14_VehicleStandStillSts_B2 0;
BA_ "GenSigSendType" SG_ 1156 FD14_ABSFailSts_B2 4;
BA_ "GenSigTimeoutTime_BSM" SG_ 1156 FD14_ABSFailSts_B2 0;
BA_ "GenSigTimeoutTime_BSM2" SG_ 1156 FD14_ABSFailSts_B2 0;
BA_ "GenSigTimeoutTime_CVADAS" SG_ 1156 FD14_ABSFailSts_B2 0;
BA_ "GenSigTimeoutTime_ECM" SG_ 1156 FD14_ABSFailSts_B2 0;
BA_ "GenSigTimeoutTime_EPS" SG_ 1156 FD14_ABSFailSts_B2 0;
BA_ "GenSigTimeoutTime_ORC" SG_ 1156 FD14_ABSFailSts_B2 0;
BA_ "GenSigTimeoutTime_BSM" SG_ 1156 FD14_CRC_BRAKE2_3 0;
BA_ "GenSigTimeoutTime_BSM2" SG_ 1156 FD14_CRC_BRAKE2_3 0;
BA_ "GenSigTimeoutTime_CVADAS" SG_ 1156 FD14_CRC_BRAKE2_3 0;
BA_ "GenSigTimeoutTime_ECM" SG_ 1156 FD14_CRC_BRAKE2_3 0;
BA_ "GenSigTimeoutTime_EPS" SG_ 1156 FD14_CRC_BRAKE2_3 0;
BA_ "GenSigTimeoutTime_BSM" SG_ 1156 FD14_MessageCounter_BRAKE2_3 0;
BA_ "GenSigTimeoutTime_BSM2" SG_ 1156 FD14_MessageCounter_BRAKE2_3 0;
BA_ "GenSigTimeoutTime_CVADAS" SG_ 1156 FD14_MessageCounter_BRAKE2_3 0;
BA_ "GenSigTimeoutTime_ECM" SG_ 1156 FD14_MessageCounter_BRAKE2_3 0;
BA_ "GenSigTimeoutTime_EPS" SG_ 1156 FD14_MessageCounter_BRAKE2_3 0;
BA_ "GenSigSendType" SG_ 1156 FD14_RollsModeAct_B2 4;
BA_ "GenSigTimeoutTime_BSM" SG_ 1156 FD14_RollsModeAct_B2 0;
BA_ "GenSigTimeoutTime_BSM2" SG_ 1156 FD14_RollsModeAct_B2 0;
BA_ "GenSigTimeoutTime_CVADAS" SG_ 1156 FD14_RollsModeAct_B2 0;
BA_ "GenSigTimeoutTime_ECM" SG_ 1156 FD14_RollsModeAct_B2 0;
BA_ "GenSigTimeoutTime_EPS" SG_ 1156 FD14_RollsModeAct_B2 0;
BA_ "GenSigTimeoutTime_ORC" SG_ 1156 FD14_RollsModeAct_B2 0;
BA_ "GenSigTimeoutTime_BSM2" SG_ 275 FD14_CRC_CVPAM_FD_Control 0;
BA_ "GenSigTimeoutTime_CADM" SG_ 275 FD14_CRC_CVPAM_FD_Control 0;
BA_ "GenSigTimeoutTime_CVADAS" SG_ 275 FD14_CRC_CVPAM_FD_Control 0;
BA_ "GenSigTimeoutTime_ECM" SG_ 275 FD14_CRC_CVPAM_FD_Control 0;
BA_ "GenSigTimeoutTime_ORC" SG_ 275 FD14_CRC_CVPAM_FD_Control 0;
BA_ "GenSigTimeoutTime_BSM" SG_ 275 FD14_ManoeuvrePhase 0;
BA_ "GenSigTimeoutTime_BSM2" SG_ 275 FD14_ManoeuvrePhase 0;
BA_ "GenSigTimeoutTime_CADM" SG_ 275 FD14_ManoeuvrePhase 0;
BA_ "GenSigTimeoutTime_CVADAS" SG_ 275 FD14_ManoeuvrePhase 0;
BA_ "GenSigTimeoutTime_ECM" SG_ 275 FD14_ManoeuvrePhase 0;
BA_ "GenSigTimeoutTime_ORC" SG_ 275 FD14_ManoeuvrePhase 0;
BA_ "GenSigTimeoutTime_BSM2" SG_ 275 FD14_MessageCounter_CVPAM_FD_Con 0;
BA_ "GenSigTimeoutTime_CADM" SG_ 275 FD14_MessageCounter_CVPAM_FD_Con 0;
BA_ "GenSigTimeoutTime_CVADAS" SG_ 275 FD14_MessageCounter_CVPAM_FD_Con 0;
BA_ "GenSigTimeoutTime_ECM" SG_ 275 FD14_MessageCounter_CVPAM_FD_Con 0;
BA_ "GenSigTimeoutTime_ORC" SG_ 275 FD14_MessageCounter_CVPAM_FD_Con 0;
BA_ "SystemSignalLongSymbol" SG_ 275 FD14_MessageCounter_CVPAM_FD_Con "FD14_MessageCounter_CVPAM_FD_Control";
BA_ "GenSigTimeoutTime_BSM2" SG_ 275 FD14_ParkingGearShiftReq 0;
BA_ "GenSigTimeoutTime_CADM" SG_ 275 FD14_ParkingGearShiftReq 0;
BA_ "GenSigTimeoutTime_CVADAS" SG_ 275 FD14_ParkingGearShiftReq 0;
BA_ "GenSigTimeoutTime_ECM" SG_ 275 FD14_ParkingGearShiftReq 0;
BA_ "GenSigTimeoutTime_EPS" SG_ 275 FD14_ParkingGearShiftReq 0;
BA_ "GenSigTimeoutTime_ORC" SG_ 275 FD14_ParkingGearShiftReq 0;
BA_ "GenSigTimeoutTime_BSM2" SG_ 275 FD14_PPPA_AccelMax 0;
BA_ "GenSigTimeoutTime_CADM" SG_ 275 FD14_PPPA_AccelMax 0;
BA_ "GenSigTimeoutTime_CVADAS" SG_ 275 FD14_PPPA_AccelMax 0;
BA_ "GenSigTimeoutTime_ECM" SG_ 275 FD14_PPPA_AccelMax 0;
BA_ "GenSigTimeoutTime_EPS" SG_ 275 FD14_PPPA_AccelMax 0;
BA_ "GenSigTimeoutTime_ORC" SG_ 275 FD14_PPPA_AccelMax 0;
BA_ "GenSigTimeoutTime_BSM2" SG_ 275 FD14_PPPA_AccelMin 0;
BA_ "GenSigTimeoutTime_CADM" SG_ 275 FD14_PPPA_AccelMin 0;
BA_ "GenSigTimeoutTime_CVADAS" SG_ 275 FD14_PPPA_AccelMin 0;
BA_ "GenSigTimeoutTime_ECM" SG_ 275 FD14_PPPA_AccelMin 0;
BA_ "GenSigTimeoutTime_EPS" SG_ 275 FD14_PPPA_AccelMin 0;
BA_ "GenSigTimeoutTime_ORC" SG_ 275 FD14_PPPA_AccelMin 0;
BA_ "GenSigTimeoutTime_BSM2" SG_ 275 FD14_PPPA_DecelMax 0;
BA_ "GenSigTimeoutTime_CADM" SG_ 275 FD14_PPPA_DecelMax 0;
BA_ "GenSigTimeoutTime_CVADAS" SG_ 275 FD14_PPPA_DecelMax 0;
BA_ "GenSigTimeoutTime_ECM" SG_ 275 FD14_PPPA_DecelMax 0;
BA_ "GenSigTimeoutTime_EPS" SG_ 275 FD14_PPPA_DecelMax 0;
BA_ "GenSigTimeoutTime_ORC" SG_ 275 FD14_PPPA_DecelMax 0;
BA_ "GenSigTimeoutTime_BSM2" SG_ 275 FD14_PPPA_DecelMin 0;
BA_ "GenSigTimeoutTime_CADM" SG_ 275 FD14_PPPA_DecelMin 0;
BA_ "GenSigTimeoutTime_CVADAS" SG_ 275 FD14_PPPA_DecelMin 0;
BA_ "GenSigTimeoutTime_ECM" SG_ 275 FD14_PPPA_DecelMin 0;
BA_ "GenSigTimeoutTime_EPS" SG_ 275 FD14_PPPA_DecelMin 0;
BA_ "GenSigTimeoutTime_ORC" SG_ 275 FD14_PPPA_DecelMin 0;
BA_ "GenSigTimeoutTime_BSM2" SG_ 275 FD14_PPPA_Interface_BSM 0;
BA_ "GenSigTimeoutTime_CADM" SG_ 275 FD14_PPPA_Interface_BSM 0;
BA_ "GenSigTimeoutTime_CVADAS" SG_ 275 FD14_PPPA_Interface_BSM 0;
BA_ "GenSigTimeoutTime_ECM" SG_ 275 FD14_PPPA_Interface_BSM 0;
BA_ "GenSigTimeoutTime_EPS" SG_ 275 FD14_PPPA_Interface_BSM 0;
BA_ "GenSigTimeoutTime_ORC" SG_ 275 FD14_PPPA_Interface_BSM 0;
BA_ "GenSigTimeoutTime_BSM2" SG_ 275 FD14_PPPA_JerkAccelMax 0;
BA_ "GenSigTimeoutTime_CADM" SG_ 275 FD14_PPPA_JerkAccelMax 0;
BA_ "GenSigTimeoutTime_CVADAS" SG_ 275 FD14_PPPA_JerkAccelMax 0;
BA_ "GenSigTimeoutTime_ECM" SG_ 275 FD14_PPPA_JerkAccelMax 0;
BA_ "GenSigTimeoutTime_EPS" SG_ 275 FD14_PPPA_JerkAccelMax 0;
BA_ "GenSigTimeoutTime_ORC" SG_ 275 FD14_PPPA_JerkAccelMax 0;
BA_ "GenSigTimeoutTime_BSM2" SG_ 275 FD14_PPPA_JerkAccelMin 0;
BA_ "GenSigTimeoutTime_CADM" SG_ 275 FD14_PPPA_JerkAccelMin 0;
BA_ "GenSigTimeoutTime_CVADAS" SG_ 275 FD14_PPPA_JerkAccelMin 0;
BA_ "GenSigTimeoutTime_ECM" SG_ 275 FD14_PPPA_JerkAccelMin 0;
BA_ "GenSigTimeoutTime_EPS" SG_ 275 FD14_PPPA_JerkAccelMin 0;
BA_ "GenSigTimeoutTime_ORC" SG_ 275 FD14_PPPA_JerkAccelMin 0;
BA_ "GenSigTimeoutTime_BSM2" SG_ 275 FD14_PPPA_JerkDecelMax 0;
BA_ "GenSigTimeoutTime_CADM" SG_ 275 FD14_PPPA_JerkDecelMax 0;
BA_ "GenSigTimeoutTime_CVADAS" SG_ 275 FD14_PPPA_JerkDecelMax 0;
BA_ "GenSigTimeoutTime_ECM" SG_ 275 FD14_PPPA_JerkDecelMax 0;
BA_ "GenSigTimeoutTime_EPS" SG_ 275 FD14_PPPA_JerkDecelMax 0;
BA_ "GenSigTimeoutTime_ORC" SG_ 275 FD14_PPPA_JerkDecelMax 0;
BA_ "GenSigTimeoutTime_BSM2" SG_ 275 FD14_PPPA_JerkDecelMin 0;
BA_ "GenSigTimeoutTime_CADM" SG_ 275 FD14_PPPA_JerkDecelMin 0;
BA_ "GenSigTimeoutTime_CVADAS" SG_ 275 FD14_PPPA_JerkDecelMin 0;
BA_ "GenSigTimeoutTime_ECM" SG_ 275 FD14_PPPA_JerkDecelMin 0;
BA_ "GenSigTimeoutTime_EPS" SG_ 275 FD14_PPPA_JerkDecelMin 0;
BA_ "GenSigTimeoutTime_ORC" SG_ 275 FD14_PPPA_JerkDecelMin 0;
BA_ "GenSigTimeoutTime_BSM2" SG_ 275 FD14_PPPA_MaxSpeed 0;
BA_ "GenSigTimeoutTime_CADM" SG_ 275 FD14_PPPA_MaxSpeed 0;
BA_ "GenSigTimeoutTime_CVADAS" SG_ 275 FD14_PPPA_MaxSpeed 0;
BA_ "GenSigTimeoutTime_ECM" SG_ 275 FD14_PPPA_MaxSpeed 0;
BA_ "GenSigTimeoutTime_EPS" SG_ 275 FD14_PPPA_MaxSpeed 0;
BA_ "GenSigTimeoutTime_ORC" SG_ 275 FD14_PPPA_MaxSpeed 0;
BA_ "GenSigTimeoutTime_BSM2" SG_ 275 FD14_PPPA_StandstillRqst 0;
BA_ "GenSigTimeoutTime_CADM" SG_ 275 FD14_PPPA_StandstillRqst 0;
BA_ "GenSigTimeoutTime_CVADAS" SG_ 275 FD14_PPPA_StandstillRqst 0;
BA_ "GenSigTimeoutTime_ECM" SG_ 275 FD14_PPPA_StandstillRqst 0;
BA_ "GenSigTimeoutTime_EPS" SG_ 275 FD14_PPPA_StandstillRqst 0;
BA_ "GenSigTimeoutTime_ORC" SG_ 275 FD14_PPPA_StandstillRqst 0;
BA_ "GenSigTimeoutTime_BSM2" SG_ 275 FD14_PPPA_TargetDistance 0;
BA_ "GenSigTimeoutTime_CADM" SG_ 275 FD14_PPPA_TargetDistance 0;
BA_ "GenSigTimeoutTime_CVADAS" SG_ 275 FD14_PPPA_TargetDistance 0;
BA_ "GenSigTimeoutTime_ECM" SG_ 275 FD14_PPPA_TargetDistance 0;
BA_ "GenSigTimeoutTime_EPS" SG_ 275 FD14_PPPA_TargetDistance 0;
BA_ "GenSigTimeoutTime_ORC" SG_ 275 FD14_PPPA_TargetDistance 0;
BA_ "GenSigTimeoutTime_BSM2" SG_ 275 FD14_RR_PAM_Brk_RqSts 0;
BA_ "GenSigTimeoutTime_CADM" SG_ 275 FD14_RR_PAM_Brk_RqSts 0;
BA_ "GenSigTimeoutTime_CVADAS" SG_ 275 FD14_RR_PAM_Brk_RqSts 0;
BA_ "GenSigTimeoutTime_ECM" SG_ 275 FD14_RR_PAM_Brk_RqSts 0;
BA_ "GenSigTimeoutTime_EPS" SG_ 275 FD14_RR_PAM_Brk_RqSts 0;
BA_ "GenSigTimeoutTime_ORC" SG_ 275 FD14_RR_PAM_Brk_RqSts 0;
BA_ "GenSigTimeoutTime_BSM2" SG_ 275 FD14_RR_PAM_Dist 0;
BA_ "GenSigTimeoutTime_CADM" SG_ 275 FD14_RR_PAM_Dist 0;
BA_ "GenSigTimeoutTime_CVADAS" SG_ 275 FD14_RR_PAM_Dist 0;
BA_ "GenSigTimeoutTime_ECM" SG_ 275 FD14_RR_PAM_Dist 0;
BA_ "GenSigTimeoutTime_EPS" SG_ 275 FD14_RR_PAM_Dist 0;
BA_ "GenSigTimeoutTime_ORC" SG_ 275 FD14_RR_PAM_Dist 0;
BA_ "GenSigTimeoutTime_BSM" SG_ 275 FD14_SPM_Lat_Ctrl_RequestSts 0;
BA_ "GenSigTimeoutTime_BSM2" SG_ 275 FD14_SPM_Lat_Ctrl_RequestSts 0;
BA_ "GenSigTimeoutTime_CADM" SG_ 275 FD14_SPM_Lat_Ctrl_RequestSts 0;
BA_ "GenSigTimeoutTime_CVADAS" SG_ 275 FD14_SPM_Lat_Ctrl_RequestSts 0;
BA_ "GenSigTimeoutTime_ECM" SG_ 275 FD14_SPM_Lat_Ctrl_RequestSts 0;
BA_ "GenSigStartValue" SG_ 275 FD14_TorqueOverlaySteeringReq_SP 1024;
BA_ "GenSigTimeoutTime_BSM" SG_ 275 FD14_TorqueOverlaySteeringReq_SP 0;
BA_ "GenSigTimeoutTime_BSM2" SG_ 275 FD14_TorqueOverlaySteeringReq_SP 0;
BA_ "GenSigTimeoutTime_CADM" SG_ 275 FD14_TorqueOverlaySteeringReq_SP 0;
BA_ "GenSigTimeoutTime_CVADAS" SG_ 275 FD14_TorqueOverlaySteeringReq_SP 0;
BA_ "GenSigTimeoutTime_ECM" SG_ 275 FD14_TorqueOverlaySteeringReq_SP 0;
BA_ "SystemSignalLongSymbol" SG_ 275 FD14_TorqueOverlaySteeringReq_SP "FD14_TorqueOverlaySteeringReq_SPM";
BA_ "GenSigTimeoutTime_BSM2" SG_ 950 FD14_CRC_CVPAM_FD_Info 0;
BA_ "GenSigTimeoutTime_CADM" SG_ 950 FD14_CRC_CVPAM_FD_Info 0;
BA_ "GenSigTimeoutTime_CVADAS" SG_ 950 FD14_CRC_CVPAM_FD_Info 0;
BA_ "GenSigTimeoutTime_ECM" SG_ 950 FD14_CRC_CVPAM_FD_Info 0;
BA_ "GenSigTimeoutTime_EPS" SG_ 950 FD14_CRC_CVPAM_FD_Info 0;
BA_ "SystemSignalLongSymbol" SG_ 950 FD14_MessageCounter_CVPAM_FD_Inf "FD14_MessageCounter_CVPAM_FD_Info";
BA_ "GenSigSendType" SG_ 950 FD14_ParkingManeuverActive 3;
BA_ "GenSigTimeoutTime_BSM2" SG_ 950 FD14_ParkingManeuverActive 0;
BA_ "GenSigTimeoutTime_CADM" SG_ 950 FD14_ParkingManeuverActive 0;
BA_ "GenSigTimeoutTime_CVADAS" SG_ 950 FD14_ParkingManeuverActive 0;
BA_ "GenSigTimeoutTime_ECM" SG_ 950 FD14_ParkingManeuverActive 0;
BA_ "GenSigTimeoutTime_EPS" SG_ 950 FD14_ParkingManeuverActive 0;
BA_ "GenSigTimeoutTime_ORC" SG_ 950 FD14_ParkingManeuverActive 0;
BA_ "GenSigTimeoutTime_BSM" SG_ 1054 FD14_CRC_ENGINE1 0;
BA_ "GenSigTimeoutTime_BSM2" SG_ 1054 FD14_CRC_ENGINE1 0;
BA_ "GenSigTimeoutTime_CVADAS" SG_ 1054 FD14_CRC_ENGINE1 0;
BA_ "GenSigTimeoutTime_ECM" SG_ 1054 FD14_CRC_ENGINE1 0;
BA_ "GenSigTimeoutTime_EPS" SG_ 1054 FD14_CRC_ENGINE1 0;
BA_ "GenSigTimeoutTime_ORC" SG_ 1054 FD14_CRC_ENGINE1 0;
BA_ "GenSigTimeoutTime_BSM" SG_ 1054 FD14_MessageCounter_ENGINE1 0;
BA_ "GenSigTimeoutTime_BSM2" SG_ 1054 FD14_MessageCounter_ENGINE1 0;
BA_ "GenSigTimeoutTime_CVADAS" SG_ 1054 FD14_MessageCounter_ENGINE1 0;
BA_ "GenSigTimeoutTime_ECM" SG_ 1054 FD14_MessageCounter_ENGINE1 0;
BA_ "GenSigTimeoutTime_EPS" SG_ 1054 FD14_MessageCounter_ENGINE1 0;
BA_ "GenSigTimeoutTime_ORC" SG_ 1054 FD14_MessageCounter_ENGINE1 0;
BA_ "GenSigTimeoutTime_BSM" SG_ 1054 FD14_ThermalManagementActive_W 0;
BA_ "GenSigTimeoutTime_BSM2" SG_ 1054 FD14_ThermalManagementActive_W 0;
BA_ "GenSigTimeoutTime_CVADAS" SG_ 1054 FD14_ThermalManagementActive_W 0;
BA_ "GenSigTimeoutTime_ECM" SG_ 1054 FD14_ThermalManagementActive_W 0;
BA_ "GenSigTimeoutTime_EPS" SG_ 1054 FD14_ThermalManagementActive_W 0;
BA_ "GenSigTimeoutTime_ORC" SG_ 1054 FD14_ThermalManagementActive_W 0;
BA_ "GenSigTimeoutTime_BSM2" SG_ 262 FD14_CRC_ENGINE2 0;
BA_ "GenSigTimeoutTime_ECM" SG_ 262 FD14_CRC_ENGINE2 0;
BA_ "GenSigTimeoutTime_ORC" SG_ 262 FD14_CRC_ENGINE2 0;
BA_ "GenSigTimeoutTime_BSM" SG_ 262 FD14_ECM_LHOM_W 0;
BA_ "GenSigTimeoutTime_BSM2" SG_ 262 FD14_ECM_LHOM_W 0;
BA_ "GenSigTimeoutTime_CVADAS" SG_ 262 FD14_ECM_LHOM_W 0;
BA_ "GenSigTimeoutTime_ECM" SG_ 262 FD14_ECM_LHOM_W 0;
BA_ "GenSigTimeoutTime_EPS" SG_ 262 FD14_ECM_LHOM_W 0;
BA_ "GenSigTimeoutTime_ORC" SG_ 262 FD14_ECM_LHOM_W 0;
BA_ "GenSigTimeoutTime_BSM2" SG_ 262 FD14_EngineSpeed_W 0;
BA_ "GenSigTimeoutTime_CVADAS" SG_ 262 FD14_EngineSpeed_W 0;
BA_ "GenSigTimeoutTime_ECM" SG_ 262 FD14_EngineSpeed_W 0;
BA_ "GenSigTimeoutTime_ORC" SG_ 262 FD14_EngineSpeed_W 0;
BA_ "GenSigStartValue" SG_ 262 FD14_EngineSts_W 3;
BA_ "GenSigTimeoutTime_BSM2" SG_ 262 FD14_EngineSts_W 0;
BA_ "GenSigTimeoutTime_ECM" SG_ 262 FD14_EngineSts_W 0;
BA_ "GenSigTimeoutTime_ORC" SG_ 262 FD14_EngineSts_W 0;
BA_ "GenSigStartValue" SG_ 262 FD14_ESS_ENG_ST_W 15;
BA_ "GenSigSendType" SG_ 262 FD14_ESS_ENG_ST_W 3;
BA_ "GenSigTimeoutTime_BSM2" SG_ 262 FD14_ESS_ENG_ST_W 0;
BA_ "GenSigTimeoutTime_ECM" SG_ 262 FD14_ESS_ENG_ST_W 0;
BA_ "GenSigTimeoutTime_ORC" SG_ 262 FD14_ESS_ENG_ST_W 0;
BA_ "GenSigTimeoutTime_BSM2" SG_ 262 FD14_GasPedalPosition_W 0;
BA_ "GenSigTimeoutTime_CADM" SG_ 262 FD14_GasPedalPosition_W 0;
BA_ "GenSigTimeoutTime_CVADAS" SG_ 262 FD14_GasPedalPosition_W 0;
BA_ "GenSigTimeoutTime_ECM" SG_ 262 FD14_GasPedalPosition_W 0;
BA_ "GenSigTimeoutTime_EPS" SG_ 262 FD14_GasPedalPosition_W 0;
BA_ "GenSigTimeoutTime_ORC" SG_ 262 FD14_GasPedalPosition_W 0;
BA_ "GenSigTimeoutTime_BSM2" SG_ 262 FD14_GasPedalPositionFailSts_W 0;
BA_ "GenSigTimeoutTime_CVADAS" SG_ 262 FD14_GasPedalPositionFailSts_W 0;
BA_ "GenSigTimeoutTime_ECM" SG_ 262 FD14_GasPedalPositionFailSts_W 0;
BA_ "GenSigTimeoutTime_EPS" SG_ 262 FD14_GasPedalPositionFailSts_W 0;
BA_ "GenSigTimeoutTime_ORC" SG_ 262 FD14_GasPedalPositionFailSts_W 0;
BA_ "GenSigTimeoutTime_BSM" SG_ 262 FD14_LV12PwrFreeRq_W 0;
BA_ "GenSigTimeoutTime_BSM2" SG_ 262 FD14_LV12PwrFreeRq_W 0;
BA_ "GenSigTimeoutTime_CADM" SG_ 262 FD14_LV12PwrFreeRq_W 0;
BA_ "GenSigTimeoutTime_CVADAS" SG_ 262 FD14_LV12PwrFreeRq_W 0;
BA_ "GenSigTimeoutTime_ECM" SG_ 262 FD14_LV12PwrFreeRq_W 0;
BA_ "GenSigTimeoutTime_EPS" SG_ 262 FD14_LV12PwrFreeRq_W 0;
BA_ "GenSigTimeoutTime_ORC" SG_ 262 FD14_LV12PwrFreeRq_W 0;
BA_ "GenSigTimeoutTime_BSM2" SG_ 262 FD14_MessageCounter_ENGINE2 0;
BA_ "GenSigTimeoutTime_ECM" SG_ 262 FD14_MessageCounter_ENGINE2 0;
BA_ "GenSigTimeoutTime_ORC" SG_ 262 FD14_MessageCounter_ENGINE2 0;
BA_ "GenSigTimeoutTime_BSM2" SG_ 262 FD14_PowertrainPrplsnActv 0;
BA_ "GenSigTimeoutTime_CVADAS" SG_ 262 FD14_PowertrainPrplsnActv 0;
BA_ "GenSigTimeoutTime_ECM" SG_ 262 FD14_PowertrainPrplsnActv 0;
BA_ "GenSigTimeoutTime_EPS" SG_ 262 FD14_PowertrainPrplsnActv 0;
BA_ "GenSigTimeoutTime_ORC" SG_ 262 FD14_PowertrainPrplsnActv 0;
BA_ "GenSigTimeoutTime_BSM2" SG_ 1036 FD14_CRC_ENGINE3 0;
BA_ "GenSigTimeoutTime_CADM" SG_ 1036 FD14_CRC_ENGINE3 0;
BA_ "GenSigTimeoutTime_CVADAS" SG_ 1036 FD14_CRC_ENGINE3 0;
BA_ "GenSigTimeoutTime_ECM" SG_ 1036 FD14_CRC_ENGINE3 0;
BA_ "GenSigTimeoutTime_EPS" SG_ 1036 FD14_CRC_ENGINE3 0;
BA_ "GenSigTimeoutTime_ORC" SG_ 1036 FD14_CRC_ENGINE3 0;
BA_ "GenSigTimeoutTime_BSM2" SG_ 1036 FD14_MessageCounter_ENGINE3 0;
BA_ "GenSigTimeoutTime_CADM" SG_ 1036 FD14_MessageCounter_ENGINE3 0;
BA_ "GenSigTimeoutTime_CVADAS" SG_ 1036 FD14_MessageCounter_ENGINE3 0;
BA_ "GenSigTimeoutTime_ECM" SG_ 1036 FD14_MessageCounter_ENGINE3 0;
BA_ "GenSigTimeoutTime_EPS" SG_ 1036 FD14_MessageCounter_ENGINE3 0;
BA_ "GenSigTimeoutTime_ORC" SG_ 1036 FD14_MessageCounter_ENGINE3 0;
BA_ "GenSigTimeoutTime_CVADAS" SG_ 518 FD14_CRC_ENGINE5 0;
BA_ "GenSigTimeoutTime_ECM" SG_ 518 FD14_CRC_ENGINE5 0;
BA_ "GenSigTimeoutTime_EPS" SG_ 518 FD14_CRC_ENGINE5 0;
BA_ "GenSigTimeoutTime_ORC" SG_ 518 FD14_CRC_ENGINE5 0;
BA_ "GenSigTimeoutTime_CVADAS" SG_ 518 FD14_MessageCounter_ENGINE5 0;
BA_ "GenSigTimeoutTime_ECM" SG_ 518 FD14_MessageCounter_ENGINE5 0;
BA_ "GenSigTimeoutTime_EPS" SG_ 518 FD14_MessageCounter_ENGINE5 0;
BA_ "GenSigTimeoutTime_ORC" SG_ 518 FD14_MessageCounter_ENGINE5 0;
BA_ "GenSigStartValue" SG_ 518 FD14_PdlPosActual 1;
BA_ "GenSigTimeoutTime_ECM" SG_ 518 FD14_PdlPosActual 0;
BA_ "GenSigTimeoutTime_EPS" SG_ 518 FD14_PdlPosActual 0;
BA_ "GenSigTimeoutTime_ORC" SG_ 518 FD14_PdlPosActual 0;
BA_ "GenSigTimeoutTime_BSM" SG_ 518 FD14_RPMOverRev_W 0;
BA_ "GenSigTimeoutTime_BSM2" SG_ 518 FD14_RPMOverRev_W 0;
BA_ "GenSigTimeoutTime_CVADAS" SG_ 518 FD14_RPMOverRev_W 0;
BA_ "GenSigTimeoutTime_ECM" SG_ 518 FD14_RPMOverRev_W 0;
BA_ "GenSigTimeoutTime_EPS" SG_ 518 FD14_RPMOverRev_W 0;
BA_ "GenSigTimeoutTime_ORC" SG_ 518 FD14_RPMOverRev_W 0;
BA_ "GenSigTimeoutTime_BSM" SG_ 1448 FD14_CRC_ENGINE7 0;
BA_ "GenSigTimeoutTime_BSM2" SG_ 1448 FD14_CRC_ENGINE7 0;
BA_ "GenSigTimeoutTime_CADM" SG_ 1448 FD14_CRC_ENGINE7 0;
BA_ "GenSigTimeoutTime_ECM" SG_ 1448 FD14_CRC_ENGINE7 0;
BA_ "GenSigTimeoutTime_EPS" SG_ 1448 FD14_CRC_ENGINE7 0;
BA_ "GenSigTimeoutTime_ORC" SG_ 1448 FD14_CRC_ENGINE7 0;
BA_ "GenSigSendType" SG_ 1448 FD14_ECM_THA_Resp 4;
BA_ "GenSigTimeoutTime_BSM" SG_ 1448 FD14_ECM_THA_Resp 0;
BA_ "GenSigTimeoutTime_BSM2" SG_ 1448 FD14_ECM_THA_Resp 0;
BA_ "GenSigTimeoutTime_CADM" SG_ 1448 FD14_ECM_THA_Resp 0;
BA_ "GenSigTimeoutTime_ECM" SG_ 1448 FD14_ECM_THA_Resp 0;
BA_ "GenSigTimeoutTime_EPS" SG_ 1448 FD14_ECM_THA_Resp 0;
BA_ "GenSigTimeoutTime_ORC" SG_ 1448 FD14_ECM_THA_Resp 0;
BA_ "GenSigSendType" SG_ 1448 FD14_ECM_TRSC_Resp 3;
BA_ "GenSigTimeoutTime_BSM" SG_ 1448 FD14_ECM_TRSC_Resp 0;
BA_ "GenSigTimeoutTime_BSM2" SG_ 1448 FD14_ECM_TRSC_Resp 0;
BA_ "GenSigTimeoutTime_CADM" SG_ 1448 FD14_ECM_TRSC_Resp 0;
BA_ "GenSigTimeoutTime_ECM" SG_ 1448 FD14_ECM_TRSC_Resp 0;
BA_ "GenSigTimeoutTime_EPS" SG_ 1448 FD14_ECM_TRSC_Resp 0;
BA_ "GenSigTimeoutTime_ORC" SG_ 1448 FD14_ECM_TRSC_Resp 0;
BA_ "GenSigTimeoutTime_BSM" SG_ 1448 FD14_MessageCounter_ENGINE7 0;
BA_ "GenSigTimeoutTime_BSM2" SG_ 1448 FD14_MessageCounter_ENGINE7 0;
BA_ "GenSigTimeoutTime_CADM" SG_ 1448 FD14_MessageCounter_ENGINE7 0;
BA_ "GenSigTimeoutTime_ECM" SG_ 1448 FD14_MessageCounter_ENGINE7 0;
BA_ "GenSigTimeoutTime_EPS" SG_ 1448 FD14_MessageCounter_ENGINE7 0;
BA_ "GenSigTimeoutTime_ORC" SG_ 1448 FD14_MessageCounter_ENGINE7 0;
BA_ "GenSigTimeoutTime_BSM2" SG_ 264 FD14_CRC_EPS1 0;
BA_ "GenSigTimeoutTime_ECM" SG_ 264 FD14_CRC_EPS1 0;
BA_ "GenSigTimeoutTime_EPS" SG_ 264 FD14_CRC_EPS1 0;
BA_ "GenSigTimeoutTime_BSM" SG_ 264 FD14_ElectricSteeringFailSts 0;
BA_ "GenSigTimeoutTime_BSM2" SG_ 264 FD14_ElectricSteeringFailSts 0;
BA_ "GenSigTimeoutTime_CADM" SG_ 264 FD14_ElectricSteeringFailSts 0;
BA_ "GenSigTimeoutTime_CVADAS" SG_ 264 FD14_ElectricSteeringFailSts 0;
BA_ "GenSigTimeoutTime_ECM" SG_ 264 FD14_ElectricSteeringFailSts 0;
BA_ "GenSigTimeoutTime_EPS" SG_ 264 FD14_ElectricSteeringFailSts 0;
BA_ "GenSigTimeoutTime_ORC" SG_ 264 FD14_ElectricSteeringFailSts 0;
BA_ "GenSigTimeoutTime_BSM" SG_ 264 FD14_EngineFanRequestActivation 0;
BA_ "GenSigTimeoutTime_BSM2" SG_ 264 FD14_EngineFanRequestActivation 0;
BA_ "GenSigTimeoutTime_CADM" SG_ 264 FD14_EngineFanRequestActivation 0;
BA_ "GenSigTimeoutTime_CVADAS" SG_ 264 FD14_EngineFanRequestActivation 0;
BA_ "GenSigTimeoutTime_ECM" SG_ 264 FD14_EngineFanRequestActivation 0;
BA_ "GenSigTimeoutTime_EPS" SG_ 264 FD14_EngineFanRequestActivation 0;
BA_ "GenSigTimeoutTime_ORC" SG_ 264 FD14_EngineFanRequestActivation 0;
BA_ "GenSigTimeoutTime_BSM" SG_ 264 FD14_EPS_ADAS_IMC_Fault 0;
BA_ "GenSigTimeoutTime_BSM2" SG_ 264 FD14_EPS_ADAS_IMC_Fault 0;
BA_ "GenSigTimeoutTime_CVADAS" SG_ 264 FD14_EPS_ADAS_IMC_Fault 0;
BA_ "GenSigTimeoutTime_ECM" SG_ 264 FD14_EPS_ADAS_IMC_Fault 0;
BA_ "GenSigTimeoutTime_EPS" SG_ 264 FD14_EPS_ADAS_IMC_Fault 0;
BA_ "GenSigTimeoutTime_ORC" SG_ 264 FD14_EPS_ADAS_IMC_Fault 0;
BA_ "GenSigStartValue" SG_ 264 FD14_EPS_AsstStat 1;
BA_ "GenSigTimeoutTime_BSM" SG_ 264 FD14_EPS_AsstStat 0;
BA_ "GenSigTimeoutTime_BSM2" SG_ 264 FD14_EPS_AsstStat 0;
BA_ "GenSigTimeoutTime_CVADAS" SG_ 264 FD14_EPS_AsstStat 0;
BA_ "GenSigTimeoutTime_ECM" SG_ 264 FD14_EPS_AsstStat 0;
BA_ "GenSigTimeoutTime_EPS" SG_ 264 FD14_EPS_AsstStat 0;
BA_ "GenSigTimeoutTime_ORC" SG_ 264 FD14_EPS_AsstStat 0;
BA_ "GenSigStartValue" SG_ 264 FD14_EPS_Curr 255;
BA_ "GenSigTimeoutTime_BSM" SG_ 264 FD14_EPS_Curr 0;
BA_ "GenSigTimeoutTime_BSM2" SG_ 264 FD14_EPS_Curr 0;
BA_ "GenSigTimeoutTime_CADM" SG_ 264 FD14_EPS_Curr 0;
BA_ "GenSigTimeoutTime_CVADAS" SG_ 264 FD14_EPS_Curr 0;
BA_ "GenSigTimeoutTime_ECM" SG_ 264 FD14_EPS_Curr 0;
BA_ "GenSigTimeoutTime_EPS" SG_ 264 FD14_EPS_Curr 0;
BA_ "GenSigTimeoutTime_ORC" SG_ 264 FD14_EPS_Curr 0;
BA_ "GenSigTimeoutTime_BSM" SG_ 264 FD14_EPS_Hands_On_Sts 0;
BA_ "GenSigTimeoutTime_BSM2" SG_ 264 FD14_EPS_Hands_On_Sts 0;
BA_ "GenSigTimeoutTime_CVADAS" SG_ 264 FD14_EPS_Hands_On_Sts 0;
BA_ "GenSigTimeoutTime_ECM" SG_ 264 FD14_EPS_Hands_On_Sts 0;
BA_ "GenSigTimeoutTime_EPS" SG_ 264 FD14_EPS_Hands_On_Sts 0;
BA_ "GenSigTimeoutTime_BSM" SG_ 264 FD14_EPS_HandsOnRecognition 0;
BA_ "GenSigTimeoutTime_BSM2" SG_ 264 FD14_EPS_HandsOnRecognition 0;
BA_ "GenSigTimeoutTime_CADM" SG_ 264 FD14_EPS_HandsOnRecognition 0;
BA_ "GenSigTimeoutTime_ECM" SG_ 264 FD14_EPS_HandsOnRecognition 0;
BA_ "GenSigTimeoutTime_EPS" SG_ 264 FD14_EPS_HandsOnRecognition 0;
BA_ "GenSigStartValue" SG_ 264 FD14_EPSMotorTorque 1024;
BA_ "GenSigTimeoutTime_BSM" SG_ 264 FD14_EPSMotorTorque 0;
BA_ "GenSigTimeoutTime_BSM2" SG_ 264 FD14_EPSMotorTorque 0;
BA_ "GenSigTimeoutTime_CVADAS" SG_ 264 FD14_EPSMotorTorque 0;
BA_ "GenSigTimeoutTime_ECM" SG_ 264 FD14_EPSMotorTorque 0;
BA_ "GenSigTimeoutTime_EPS" SG_ 264 FD14_EPSMotorTorque 0;
BA_ "GenSigTimeoutTime_BSM2" SG_ 264 FD14_ESA_LAT_CTRL_ResponseSts 0;
BA_ "GenSigTimeoutTime_CVADAS" SG_ 264 FD14_ESA_LAT_CTRL_ResponseSts 0;
BA_ "GenSigTimeoutTime_ECM" SG_ 264 FD14_ESA_LAT_CTRL_ResponseSts 0;
BA_ "GenSigTimeoutTime_EPS" SG_ 264 FD14_ESA_LAT_CTRL_ResponseSts 0;
BA_ "GenSigTimeoutTime_ORC" SG_ 264 FD14_ESA_LAT_CTRL_ResponseSts 0;
BA_ "GenSigTimeoutTime_BSM" SG_ 264 FD14_HAS_LAT_CTRL_ResponseSts 0;
BA_ "GenSigTimeoutTime_BSM2" SG_ 264 FD14_HAS_LAT_CTRL_ResponseSts 0;
BA_ "GenSigTimeoutTime_CVADAS" SG_ 264 FD14_HAS_LAT_CTRL_ResponseSts 0;
BA_ "GenSigTimeoutTime_ECM" SG_ 264 FD14_HAS_LAT_CTRL_ResponseSts 0;
BA_ "GenSigTimeoutTime_EPS" SG_ 264 FD14_HAS_LAT_CTRL_ResponseSts 0;
BA_ "GenSigTimeoutTime_BSM" SG_ 264 FD14_LKA_LAT_CTRL_ResponseSts 0;
BA_ "GenSigTimeoutTime_BSM2" SG_ 264 FD14_LKA_LAT_CTRL_ResponseSts 0;
BA_ "GenSigTimeoutTime_CVADAS" SG_ 264 FD14_LKA_LAT_CTRL_ResponseSts 0;
BA_ "GenSigTimeoutTime_ECM" SG_ 264 FD14_LKA_LAT_CTRL_ResponseSts 0;
BA_ "GenSigTimeoutTime_EPS" SG_ 264 FD14_LKA_LAT_CTRL_ResponseSts 0;
BA_ "GenSigTimeoutTime_BSM2" SG_ 264 FD14_LwsAngle 0;
BA_ "GenSigTimeoutTime_ECM" SG_ 264 FD14_LwsAngle 0;
BA_ "GenSigTimeoutTime_EPS" SG_ 264 FD14_LwsAngle 0;
BA_ "GenSigTimeoutTime_ORC" SG_ 264 FD14_LwsAngle 0;
BA_ "GenSigTimeoutTime_BSM2" SG_ 264 FD14_LwsAngleType 0;
BA_ "GenSigTimeoutTime_ECM" SG_ 264 FD14_LwsAngleType 0;
BA_ "GenSigTimeoutTime_EPS" SG_ 264 FD14_LwsAngleType 0;
BA_ "GenSigTimeoutTime_ORC" SG_ 264 FD14_LwsAngleType 0;
BA_ "GenSigTimeoutTime_BSM2" SG_ 264 FD14_LwsCalibration 0;
BA_ "GenSigTimeoutTime_CVADAS" SG_ 264 FD14_LwsCalibration 0;
BA_ "GenSigTimeoutTime_ECM" SG_ 264 FD14_LwsCalibration 0;
BA_ "GenSigTimeoutTime_EPS" SG_ 264 FD14_LwsCalibration 0;
BA_ "GenSigTimeoutTime_ORC" SG_ 264 FD14_LwsCalibration 0;
BA_ "GenSigTimeoutTime_BSM" SG_ 264 FD14_LwsSpeed 0;
BA_ "GenSigTimeoutTime_BSM2" SG_ 264 FD14_LwsSpeed 0;
BA_ "GenSigTimeoutTime_ECM" SG_ 264 FD14_LwsSpeed 0;
BA_ "GenSigTimeoutTime_EPS" SG_ 264 FD14_LwsSpeed 0;
BA_ "GenSigTimeoutTime_ORC" SG_ 264 FD14_LwsSpeed 0;
BA_ "GenSigTimeoutTime_BSM2" SG_ 264 FD14_MessageCounter_EPS1 0;
BA_ "GenSigTimeoutTime_ECM" SG_ 264 FD14_MessageCounter_EPS1 0;
BA_ "GenSigTimeoutTime_EPS" SG_ 264 FD14_MessageCounter_EPS1 0;
BA_ "GenSigTimeoutTime_BSM" SG_ 264 FD14_SPM_Lat_Ctrl_ResponseSts 0;
BA_ "GenSigTimeoutTime_BSM2" SG_ 264 FD14_SPM_Lat_Ctrl_ResponseSts 0;
BA_ "GenSigTimeoutTime_CADM" SG_ 264 FD14_SPM_Lat_Ctrl_ResponseSts 0;
BA_ "GenSigTimeoutTime_ECM" SG_ 264 FD14_SPM_Lat_Ctrl_ResponseSts 0;
BA_ "GenSigTimeoutTime_EPS" SG_ 264 FD14_SPM_Lat_Ctrl_ResponseSts 0;
BA_ "GenSigTimeoutTime_BSM" SG_ 264 FD14_Steering_Column_Torque 0;
BA_ "GenSigTimeoutTime_BSM2" SG_ 264 FD14_Steering_Column_Torque 0;
BA_ "GenSigTimeoutTime_ECM" SG_ 264 FD14_Steering_Column_Torque 0;
BA_ "GenSigTimeoutTime_EPS" SG_ 264 FD14_Steering_Column_Torque 0;
BA_ "GenSigTimeoutTime_ORC" SG_ 264 FD14_Steering_Column_Torque 0;
BA_ "GenSigTimeoutTime_BSM" SG_ 264 FD14_Steering_OpStat_Prim 0;
BA_ "GenSigTimeoutTime_BSM2" SG_ 264 FD14_Steering_OpStat_Prim 0;
BA_ "GenSigTimeoutTime_CVADAS" SG_ 264 FD14_Steering_OpStat_Prim 0;
BA_ "GenSigTimeoutTime_ECM" SG_ 264 FD14_Steering_OpStat_Prim 0;
BA_ "GenSigTimeoutTime_EPS" SG_ 264 FD14_Steering_OpStat_Prim 0;
BA_ "GenSigTimeoutTime_BSM" SG_ 264 FD14_SteeringVibration_Fault 0;
BA_ "GenSigTimeoutTime_BSM2" SG_ 264 FD14_SteeringVibration_Fault 0;
BA_ "GenSigTimeoutTime_CVADAS" SG_ 264 FD14_SteeringVibration_Fault 0;
BA_ "GenSigTimeoutTime_ECM" SG_ 264 FD14_SteeringVibration_Fault 0;
BA_ "GenSigTimeoutTime_EPS" SG_ 264 FD14_SteeringVibration_Fault 0;
BA_ "GenSigTimeoutTime_ORC" SG_ 264 FD14_SteeringVibration_Fault 0;
BA_ "GenSigTimeoutTime_BSM" SG_ 264 FD14_SteeringVibration_Status 0;
BA_ "GenSigTimeoutTime_BSM2" SG_ 264 FD14_SteeringVibration_Status 0;
BA_ "GenSigTimeoutTime_CVADAS" SG_ 264 FD14_SteeringVibration_Status 0;
BA_ "GenSigTimeoutTime_ECM" SG_ 264 FD14_SteeringVibration_Status 0;
BA_ "GenSigTimeoutTime_EPS" SG_ 264 FD14_SteeringVibration_Status 0;
BA_ "GenSigTimeoutTime_BSM" SG_ 1056 FD14_CRC_EPS2 0;
BA_ "GenSigTimeoutTime_BSM2" SG_ 1056 FD14_CRC_EPS2 0;
BA_ "GenSigTimeoutTime_CADM" SG_ 1056 FD14_CRC_EPS2 0;
BA_ "GenSigTimeoutTime_ECM" SG_ 1056 FD14_CRC_EPS2 0;
BA_ "GenSigTimeoutTime_EPS" SG_ 1056 FD14_CRC_EPS2 0;
BA_ "GenSigTimeoutTime_ORC" SG_ 1056 FD14_CRC_EPS2 0;
BA_ "GenSigTimeoutTime_BSM" SG_ 1056 FD14_EPS_MODE_STAT 0;
BA_ "GenSigTimeoutTime_BSM2" SG_ 1056 FD14_EPS_MODE_STAT 0;
BA_ "GenSigTimeoutTime_CADM" SG_ 1056 FD14_EPS_MODE_STAT 0;
BA_ "GenSigTimeoutTime_CVADAS" SG_ 1056 FD14_EPS_MODE_STAT 0;
BA_ "GenSigTimeoutTime_ECM" SG_ 1056 FD14_EPS_MODE_STAT 0;
BA_ "GenSigTimeoutTime_EPS" SG_ 1056 FD14_EPS_MODE_STAT 0;
BA_ "GenSigTimeoutTime_ORC" SG_ 1056 FD14_EPS_MODE_STAT 0;
BA_ "GenSigTimeoutTime_BSM" SG_ 1056 FD14_EPS_SteeringTouchStat 0;
BA_ "GenSigTimeoutTime_BSM2" SG_ 1056 FD14_EPS_SteeringTouchStat 0;
BA_ "GenSigTimeoutTime_CADM" SG_ 1056 FD14_EPS_SteeringTouchStat 0;
BA_ "GenSigTimeoutTime_ECM" SG_ 1056 FD14_EPS_SteeringTouchStat 0;
BA_ "GenSigTimeoutTime_EPS" SG_ 1056 FD14_EPS_SteeringTouchStat 0;
BA_ "GenSigTimeoutTime_ORC" SG_ 1056 FD14_EPS_SteeringTouchStat 0;
BA_ "GenSigTimeoutTime_BSM" SG_ 1056 FD14_EPS_SteeringTouq_Resp 0;
BA_ "GenSigTimeoutTime_BSM2" SG_ 1056 FD14_EPS_SteeringTouq_Resp 0;
BA_ "GenSigTimeoutTime_CADM" SG_ 1056 FD14_EPS_SteeringTouq_Resp 0;
BA_ "GenSigTimeoutTime_ECM" SG_ 1056 FD14_EPS_SteeringTouq_Resp 0;
BA_ "GenSigTimeoutTime_EPS" SG_ 1056 FD14_EPS_SteeringTouq_Resp 0;
BA_ "GenSigTimeoutTime_ORC" SG_ 1056 FD14_EPS_SteeringTouq_Resp 0;
BA_ "GenSigTimeoutTime_BSM" SG_ 1056 FD14_EPS_THA_DriverTorqueOverrid 0;
BA_ "GenSigTimeoutTime_BSM2" SG_ 1056 FD14_EPS_THA_DriverTorqueOverrid 0;
BA_ "GenSigTimeoutTime_CADM" SG_ 1056 FD14_EPS_THA_DriverTorqueOverrid 0;
BA_ "GenSigTimeoutTime_ECM" SG_ 1056 FD14_EPS_THA_DriverTorqueOverrid 0;
BA_ "GenSigTimeoutTime_EPS" SG_ 1056 FD14_EPS_THA_DriverTorqueOverrid 0;
BA_ "GenSigTimeoutTime_ORC" SG_ 1056 FD14_EPS_THA_DriverTorqueOverrid 0;
BA_ "SystemSignalLongSymbol" SG_ 1056 FD14_EPS_THA_DriverTorqueOverrid "FD14_EPS_THA_DriverTorqueOverride";
BA_ "GenSigTimeoutTime_BSM" SG_ 1056 FD14_EPS_THA_SteeringTorqueResp 0;
BA_ "GenSigTimeoutTime_BSM2" SG_ 1056 FD14_EPS_THA_SteeringTorqueResp 0;
BA_ "GenSigTimeoutTime_CADM" SG_ 1056 FD14_EPS_THA_SteeringTorqueResp 0;
BA_ "GenSigTimeoutTime_ECM" SG_ 1056 FD14_EPS_THA_SteeringTorqueResp 0;
BA_ "GenSigTimeoutTime_EPS" SG_ 1056 FD14_EPS_THA_SteeringTorqueResp 0;
BA_ "GenSigTimeoutTime_ORC" SG_ 1056 FD14_EPS_THA_SteeringTorqueResp 0;
BA_ "GenSigTimeoutTime_BSM" SG_ 1056 FD14_EPS_Warn_Disp_Rq 0;
BA_ "GenSigTimeoutTime_BSM2" SG_ 1056 FD14_EPS_Warn_Disp_Rq 0;
BA_ "GenSigTimeoutTime_CADM" SG_ 1056 FD14_EPS_Warn_Disp_Rq 0;
BA_ "GenSigTimeoutTime_CVADAS" SG_ 1056 FD14_EPS_Warn_Disp_Rq 0;
BA_ "GenSigTimeoutTime_ECM" SG_ 1056 FD14_EPS_Warn_Disp_Rq 0;
BA_ "GenSigTimeoutTime_EPS" SG_ 1056 FD14_EPS_Warn_Disp_Rq 0;
BA_ "GenSigTimeoutTime_ORC" SG_ 1056 FD14_EPS_Warn_Disp_Rq 0;
BA_ "GenSigTimeoutTime_BSM" SG_ 1056 FD14_MessageCounter_EPS2 0;
BA_ "GenSigTimeoutTime_BSM2" SG_ 1056 FD14_MessageCounter_EPS2 0;
BA_ "GenSigTimeoutTime_CADM" SG_ 1056 FD14_MessageCounter_EPS2 0;
BA_ "GenSigTimeoutTime_ECM" SG_ 1056 FD14_MessageCounter_EPS2 0;
BA_ "GenSigTimeoutTime_EPS" SG_ 1056 FD14_MessageCounter_EPS2 0;
BA_ "GenSigTimeoutTime_ORC" SG_ 1056 FD14_MessageCounter_EPS2 0;
BA_ "GenSigTimeoutTime_BSM" SG_ 1056 FD14_THA_SteeringTouchStat 0;
BA_ "GenSigTimeoutTime_BSM2" SG_ 1056 FD14_THA_SteeringTouchStat 0;
BA_ "GenSigTimeoutTime_CADM" SG_ 1056 FD14_THA_SteeringTouchStat 0;
BA_ "GenSigTimeoutTime_ECM" SG_ 1056 FD14_THA_SteeringTouchStat 0;
BA_ "GenSigTimeoutTime_EPS" SG_ 1056 FD14_THA_SteeringTouchStat 0;
BA_ "GenSigTimeoutTime_ORC" SG_ 1056 FD14_THA_SteeringTouchStat 0;
BA_ "GenSigTimeoutTime_BSM" SG_ 1626 FD14_IMPACT_B 0;
BA_ "GenSigTimeoutTime_BSM2" SG_ 1626 FD14_IMPACT_B 0;
BA_ "GenSigTimeoutTime_CADM" SG_ 1626 FD14_IMPACT_B 0;
BA_ "GenSigTimeoutTime_CVADAS" SG_ 1626 FD14_IMPACT_B 0;
BA_ "GenSigTimeoutTime_ECM" SG_ 1626 FD14_IMPACT_B 0;
BA_ "GenSigTimeoutTime_EPS" SG_ 1626 FD14_IMPACT_B 0;
BA_ "GenSigTimeoutTime_ORC" SG_ 1626 FD14_IMPACT_B 0;
BA_ "GenSigTimeoutTime_BSM" SG_ 1626 FD14_IMPACT_C 0;
BA_ "GenSigTimeoutTime_BSM2" SG_ 1626 FD14_IMPACT_C 0;
BA_ "GenSigTimeoutTime_CADM" SG_ 1626 FD14_IMPACT_C 0;
BA_ "GenSigTimeoutTime_CVADAS" SG_ 1626 FD14_IMPACT_C 0;
BA_ "GenSigTimeoutTime_ECM" SG_ 1626 FD14_IMPACT_C 0;
BA_ "GenSigTimeoutTime_EPS" SG_ 1626 FD14_IMPACT_C 0;
BA_ "GenSigTimeoutTime_ORC" SG_ 1626 FD14_IMPACT_C 0;
BA_ "GenSigTimeoutTime_BSM" SG_ 1626 FD14_IMPACT_F 0;
BA_ "GenSigTimeoutTime_BSM2" SG_ 1626 FD14_IMPACT_F 0;
BA_ "GenSigTimeoutTime_CADM" SG_ 1626 FD14_IMPACT_F 0;
BA_ "GenSigTimeoutTime_CVADAS" SG_ 1626 FD14_IMPACT_F 0;
BA_ "GenSigTimeoutTime_ECM" SG_ 1626 FD14_IMPACT_F 0;
BA_ "GenSigTimeoutTime_EPS" SG_ 1626 FD14_IMPACT_F 0;
BA_ "GenSigTimeoutTime_ORC" SG_ 1626 FD14_IMPACT_F 0;
BA_ "GenSigTimeoutTime_BSM" SG_ 1626 FD14_IMPACT_I 0;
BA_ "GenSigTimeoutTime_BSM2" SG_ 1626 FD14_IMPACT_I 0;
BA_ "GenSigTimeoutTime_CADM" SG_ 1626 FD14_IMPACT_I 0;
BA_ "GenSigTimeoutTime_CVADAS" SG_ 1626 FD14_IMPACT_I 0;
BA_ "GenSigTimeoutTime_ECM" SG_ 1626 FD14_IMPACT_I 0;
BA_ "GenSigTimeoutTime_EPS" SG_ 1626 FD14_IMPACT_I 0;
BA_ "GenSigTimeoutTime_ORC" SG_ 1626 FD14_IMPACT_I 0;
BA_ "GenSigTimeoutTime_BSM" SG_ 1626 FD14_IMPACT_K 0;
BA_ "GenSigTimeoutTime_BSM2" SG_ 1626 FD14_IMPACT_K 0;
BA_ "GenSigTimeoutTime_CADM" SG_ 1626 FD14_IMPACT_K 0;
BA_ "GenSigTimeoutTime_CVADAS" SG_ 1626 FD14_IMPACT_K 0;
BA_ "GenSigTimeoutTime_ECM" SG_ 1626 FD14_IMPACT_K 0;
BA_ "GenSigTimeoutTime_EPS" SG_ 1626 FD14_IMPACT_K 0;
BA_ "GenSigTimeoutTime_ORC" SG_ 1626 FD14_IMPACT_K 0;
BA_ "GenSigTimeoutTime_BSM" SG_ 1626 FD14_IMPACT_M 0;
BA_ "GenSigTimeoutTime_BSM2" SG_ 1626 FD14_IMPACT_M 0;
BA_ "GenSigTimeoutTime_CADM" SG_ 1626 FD14_IMPACT_M 0;
BA_ "GenSigTimeoutTime_CVADAS" SG_ 1626 FD14_IMPACT_M 0;
BA_ "GenSigTimeoutTime_ECM" SG_ 1626 FD14_IMPACT_M 0;
BA_ "GenSigTimeoutTime_EPS" SG_ 1626 FD14_IMPACT_M 0;
BA_ "GenSigTimeoutTime_ORC" SG_ 1626 FD14_IMPACT_M 0;
BA_ "GenSigSendType" SG_ 1626 FD14_IMPACTCommand 5;
BA_ "GenSigTimeoutTime_BSM" SG_ 1626 FD14_IMPACTCommand 0;
BA_ "GenSigTimeoutTime_BSM2" SG_ 1626 FD14_IMPACTCommand 0;
BA_ "GenSigTimeoutTime_CVADAS" SG_ 1626 FD14_IMPACTCommand 0;
BA_ "GenSigTimeoutTime_ECM" SG_ 1626 FD14_IMPACTCommand 0;
BA_ "GenSigTimeoutTime_EPS" SG_ 1626 FD14_IMPACTCommand 0;
BA_ "GenSigTimeoutTime_ORC" SG_ 1626 FD14_IMPACTCommand 0;
BA_ "GenSigStartValue" SG_ 1626 FD14_IMPACTConfirm 1;
BA_ "GenSigInactiveValue" SG_ 1626 FD14_IMPACTConfirm 1;
BA_ "GenSigSendType" SG_ 1626 FD14_IMPACTConfirm 5;
BA_ "GenSigTimeoutTime_BSM" SG_ 1626 FD14_IMPACTConfirm 0;
BA_ "GenSigTimeoutTime_BSM2" SG_ 1626 FD14_IMPACTConfirm 0;
BA_ "GenSigTimeoutTime_CVADAS" SG_ 1626 FD14_IMPACTConfirm 0;
BA_ "GenSigTimeoutTime_ECM" SG_ 1626 FD14_IMPACTConfirm 0;
BA_ "GenSigTimeoutTime_EPS" SG_ 1626 FD14_IMPACTConfirm 0;
BA_ "GenSigTimeoutTime_ORC" SG_ 1626 FD14_IMPACTConfirm 0;
BA_ "GenSigSendType" SG_ 1626 FD14_IMPACTFailSts 5;
BA_ "GenSigTimeoutTime_BSM" SG_ 1626 FD14_IMPACTFailSts 0;
BA_ "GenSigTimeoutTime_BSM2" SG_ 1626 FD14_IMPACTFailSts 0;
BA_ "GenSigTimeoutTime_CADM" SG_ 1626 FD14_IMPACTFailSts 0;
BA_ "GenSigTimeoutTime_CVADAS" SG_ 1626 FD14_IMPACTFailSts 0;
BA_ "GenSigTimeoutTime_ECM" SG_ 1626 FD14_IMPACTFailSts 0;
BA_ "GenSigTimeoutTime_EPS" SG_ 1626 FD14_IMPACTFailSts 0;
BA_ "GenSigTimeoutTime_ORC" SG_ 1626 FD14_IMPACTFailSts 0;
BA_ "GenSigTimeoutTime_BSM" SG_ 1626 FD14_IMPACTThreshold 0;
BA_ "GenSigTimeoutTime_BSM2" SG_ 1626 FD14_IMPACTThreshold 0;
BA_ "GenSigTimeoutTime_CADM" SG_ 1626 FD14_IMPACTThreshold 0;
BA_ "GenSigTimeoutTime_CVADAS" SG_ 1626 FD14_IMPACTThreshold 0;
BA_ "GenSigTimeoutTime_ECM" SG_ 1626 FD14_IMPACTThreshold 0;
BA_ "GenSigTimeoutTime_EPS" SG_ 1626 FD14_IMPACTThreshold 0;
BA_ "GenSigTimeoutTime_ORC" SG_ 1626 FD14_IMPACTThreshold 0;
BA_ "GenSigTimeoutTime_BSM" SG_ 2654486534 FD14_CBV_bit0_RepeatMessageReque 0;
BA_ "GenSigTimeoutTime_BSM2" SG_ 2654486534 FD14_CBV_bit0_RepeatMessageReque 0;
BA_ "GenSigTimeoutTime_CADM" SG_ 2654486534 FD14_CBV_bit0_RepeatMessageReque 0;
BA_ "GenSigTimeoutTime_CVADAS" SG_ 2654486534 FD14_CBV_bit0_RepeatMessageReque 0;
BA_ "GenSigTimeoutTime_ECM" SG_ 2654486534 FD14_CBV_bit0_RepeatMessageReque 0;
BA_ "GenSigTimeoutTime_EPS" SG_ 2654486534 FD14_CBV_bit0_RepeatMessageReque 0;
BA_ "GenSigTimeoutTime_ORC" SG_ 2654486534 FD14_CBV_bit0_RepeatMessageReque 0;
BA_ "SystemSignalLongSymbol" SG_ 2654486534 FD14_CBV_bit0_RepeatMessageReque "FD14_CBV_bit0_RepeatMessageRequestBit";
BA_ "GenSigTimeoutTime_BSM" SG_ 2654486534 FD14_CBV_bit1 0;
BA_ "GenSigTimeoutTime_BSM2" SG_ 2654486534 FD14_CBV_bit1 0;
BA_ "GenSigTimeoutTime_CADM" SG_ 2654486534 FD14_CBV_bit1 0;
BA_ "GenSigTimeoutTime_CVADAS" SG_ 2654486534 FD14_CBV_bit1 0;
BA_ "GenSigTimeoutTime_ECM" SG_ 2654486534 FD14_CBV_bit1 0;
BA_ "GenSigTimeoutTime_EPS" SG_ 2654486534 FD14_CBV_bit1 0;
BA_ "GenSigTimeoutTime_ORC" SG_ 2654486534 FD14_CBV_bit1 0;
BA_ "GenSigTimeoutTime_BSM" SG_ 2654486534 FD14_CBV_bit2 0;
BA_ "GenSigTimeoutTime_BSM2" SG_ 2654486534 FD14_CBV_bit2 0;
BA_ "GenSigTimeoutTime_CADM" SG_ 2654486534 FD14_CBV_bit2 0;
BA_ "GenSigTimeoutTime_CVADAS" SG_ 2654486534 FD14_CBV_bit2 0;
BA_ "GenSigTimeoutTime_ECM" SG_ 2654486534 FD14_CBV_bit2 0;
BA_ "GenSigTimeoutTime_EPS" SG_ 2654486534 FD14_CBV_bit2 0;
BA_ "GenSigTimeoutTime_ORC" SG_ 2654486534 FD14_CBV_bit2 0;
BA_ "GenSigTimeoutTime_BSM" SG_ 2654486534 FD14_CBV_bit3_NMCoordinatorBit 0;
BA_ "GenSigTimeoutTime_BSM2" SG_ 2654486534 FD14_CBV_bit3_NMCoordinatorBit 0;
BA_ "GenSigTimeoutTime_CADM" SG_ 2654486534 FD14_CBV_bit3_NMCoordinatorBit 0;
BA_ "GenSigTimeoutTime_CVADAS" SG_ 2654486534 FD14_CBV_bit3_NMCoordinatorBit 0;
BA_ "GenSigTimeoutTime_ECM" SG_ 2654486534 FD14_CBV_bit3_NMCoordinatorBit 0;
BA_ "GenSigTimeoutTime_EPS" SG_ 2654486534 FD14_CBV_bit3_NMCoordinatorBit 0;
BA_ "GenSigTimeoutTime_ORC" SG_ 2654486534 FD14_CBV_bit3_NMCoordinatorBit 0;
BA_ "GenSigTimeoutTime_BSM" SG_ 2654486534 FD14_CBV_bit4_ActiveWakeupBit 0;
BA_ "GenSigTimeoutTime_BSM2" SG_ 2654486534 FD14_CBV_bit4_ActiveWakeupBit 0;
BA_ "GenSigTimeoutTime_CADM" SG_ 2654486534 FD14_CBV_bit4_ActiveWakeupBit 0;
BA_ "GenSigTimeoutTime_CVADAS" SG_ 2654486534 FD14_CBV_bit4_ActiveWakeupBit 0;
BA_ "GenSigTimeoutTime_ECM" SG_ 2654486534 FD14_CBV_bit4_ActiveWakeupBit 0;
BA_ "GenSigTimeoutTime_EPS" SG_ 2654486534 FD14_CBV_bit4_ActiveWakeupBit 0;
BA_ "GenSigTimeoutTime_ORC" SG_ 2654486534 FD14_CBV_bit4_ActiveWakeupBit 0;
BA_ "GenSigTimeoutTime_BSM" SG_ 2654486534 FD14_CBV_bit5 0;
BA_ "GenSigTimeoutTime_BSM2" SG_ 2654486534 FD14_CBV_bit5 0;
BA_ "GenSigTimeoutTime_CADM" SG_ 2654486534 FD14_CBV_bit5 0;
BA_ "GenSigTimeoutTime_CVADAS" SG_ 2654486534 FD14_CBV_bit5 0;
BA_ "GenSigTimeoutTime_ECM" SG_ 2654486534 FD14_CBV_bit5 0;
BA_ "GenSigTimeoutTime_EPS" SG_ 2654486534 FD14_CBV_bit5 0;
BA_ "GenSigTimeoutTime_ORC" SG_ 2654486534 FD14_CBV_bit5 0;
BA_ "GenSigTimeoutTime_BSM" SG_ 2654486534 FD14_CBV_bit6_PartialNtwInfBit 0;
BA_ "GenSigTimeoutTime_BSM2" SG_ 2654486534 FD14_CBV_bit6_PartialNtwInfBit 0;
BA_ "GenSigTimeoutTime_CADM" SG_ 2654486534 FD14_CBV_bit6_PartialNtwInfBit 0;
BA_ "GenSigTimeoutTime_CVADAS" SG_ 2654486534 FD14_CBV_bit6_PartialNtwInfBit 0;
BA_ "GenSigTimeoutTime_ECM" SG_ 2654486534 FD14_CBV_bit6_PartialNtwInfBit 0;
BA_ "GenSigTimeoutTime_EPS" SG_ 2654486534 FD14_CBV_bit6_PartialNtwInfBit 0;
BA_ "GenSigTimeoutTime_ORC" SG_ 2654486534 FD14_CBV_bit6_PartialNtwInfBit 0;
BA_ "GenSigTimeoutTime_BSM" SG_ 2654486534 FD14_CBV_bit7 0;
BA_ "GenSigTimeoutTime_BSM2" SG_ 2654486534 FD14_CBV_bit7 0;
BA_ "GenSigTimeoutTime_CADM" SG_ 2654486534 FD14_CBV_bit7 0;
BA_ "GenSigTimeoutTime_CVADAS" SG_ 2654486534 FD14_CBV_bit7 0;
BA_ "GenSigTimeoutTime_ECM" SG_ 2654486534 FD14_CBV_bit7 0;
BA_ "GenSigTimeoutTime_EPS" SG_ 2654486534 FD14_CBV_bit7 0;
BA_ "GenSigTimeoutTime_ORC" SG_ 2654486534 FD14_CBV_bit7 0;
BA_ "GenSigTimeoutTime_BSM" SG_ 2654486534 FD14_SourceNodeIdentifier 0;
BA_ "GenSigTimeoutTime_BSM2" SG_ 2654486534 FD14_SourceNodeIdentifier 0;
BA_ "GenSigTimeoutTime_CADM" SG_ 2654486534 FD14_SourceNodeIdentifier 0;
BA_ "GenSigTimeoutTime_CVADAS" SG_ 2654486534 FD14_SourceNodeIdentifier 0;
BA_ "GenSigTimeoutTime_ECM" SG_ 2654486534 FD14_SourceNodeIdentifier 0;
BA_ "GenSigTimeoutTime_EPS" SG_ 2654486534 FD14_SourceNodeIdentifier 0;
BA_ "GenSigTimeoutTime_ORC" SG_ 2654486534 FD14_SourceNodeIdentifier 0;
BA_ "GenSigTimeoutTime_BSM" SG_ 2654486676 FD14_CBV_bit0_RepeatMessage_0000 0;
BA_ "GenSigTimeoutTime_BSM2" SG_ 2654486676 FD14_CBV_bit0_RepeatMessage_0000 0;
BA_ "GenSigTimeoutTime_CADM" SG_ 2654486676 FD14_CBV_bit0_RepeatMessage_0000 0;
BA_ "GenSigTimeoutTime_CVADAS" SG_ 2654486676 FD14_CBV_bit0_RepeatMessage_0000 0;
BA_ "GenSigTimeoutTime_ECM" SG_ 2654486676 FD14_CBV_bit0_RepeatMessage_0000 0;
BA_ "GenSigTimeoutTime_EPS" SG_ 2654486676 FD14_CBV_bit0_RepeatMessage_0000 0;
BA_ "GenSigTimeoutTime_ORC" SG_ 2654486676 FD14_CBV_bit0_RepeatMessage_0000 0;
BA_ "SystemSignalLongSymbol" SG_ 2654486676 FD14_CBV_bit0_RepeatMessage_0000 "FD14_CBV_bit0_RepeatMessageRequestBit";
BA_ "GenSigTimeoutTime_BSM" SG_ 2654486676 FD14_CBV_bit1 0;
BA_ "GenSigTimeoutTime_BSM2" SG_ 2654486676 FD14_CBV_bit1 0;
BA_ "GenSigTimeoutTime_CADM" SG_ 2654486676 FD14_CBV_bit1 0;
BA_ "GenSigTimeoutTime_CVADAS" SG_ 2654486676 FD14_CBV_bit1 0;
BA_ "GenSigTimeoutTime_ECM" SG_ 2654486676 FD14_CBV_bit1 0;
BA_ "GenSigTimeoutTime_EPS" SG_ 2654486676 FD14_CBV_bit1 0;
BA_ "GenSigTimeoutTime_ORC" SG_ 2654486676 FD14_CBV_bit1 0;
BA_ "GenSigTimeoutTime_BSM" SG_ 2654486676 FD14_CBV_bit2 0;
BA_ "GenSigTimeoutTime_BSM2" SG_ 2654486676 FD14_CBV_bit2 0;
BA_ "GenSigTimeoutTime_CADM" SG_ 2654486676 FD14_CBV_bit2 0;
BA_ "GenSigTimeoutTime_CVADAS" SG_ 2654486676 FD14_CBV_bit2 0;
BA_ "GenSigTimeoutTime_ECM" SG_ 2654486676 FD14_CBV_bit2 0;
BA_ "GenSigTimeoutTime_EPS" SG_ 2654486676 FD14_CBV_bit2 0;
BA_ "GenSigTimeoutTime_ORC" SG_ 2654486676 FD14_CBV_bit2 0;
BA_ "GenSigTimeoutTime_BSM" SG_ 2654486676 FD14_CBV_bit3_NMCoordinatorBit 0;
BA_ "GenSigTimeoutTime_BSM2" SG_ 2654486676 FD14_CBV_bit3_NMCoordinatorBit 0;
BA_ "GenSigTimeoutTime_CADM" SG_ 2654486676 FD14_CBV_bit3_NMCoordinatorBit 0;
BA_ "GenSigTimeoutTime_CVADAS" SG_ 2654486676 FD14_CBV_bit3_NMCoordinatorBit 0;
BA_ "GenSigTimeoutTime_ECM" SG_ 2654486676 FD14_CBV_bit3_NMCoordinatorBit 0;
BA_ "GenSigTimeoutTime_EPS" SG_ 2654486676 FD14_CBV_bit3_NMCoordinatorBit 0;
BA_ "GenSigTimeoutTime_ORC" SG_ 2654486676 FD14_CBV_bit3_NMCoordinatorBit 0;
BA_ "GenSigTimeoutTime_BSM" SG_ 2654486676 FD14_CBV_bit4_ActiveWakeupBit 0;
BA_ "GenSigTimeoutTime_BSM2" SG_ 2654486676 FD14_CBV_bit4_ActiveWakeupBit 0;
BA_ "GenSigTimeoutTime_CADM" SG_ 2654486676 FD14_CBV_bit4_ActiveWakeupBit 0;
BA_ "GenSigTimeoutTime_CVADAS" SG_ 2654486676 FD14_CBV_bit4_ActiveWakeupBit 0;
BA_ "GenSigTimeoutTime_ECM" SG_ 2654486676 FD14_CBV_bit4_ActiveWakeupBit 0;
BA_ "GenSigTimeoutTime_EPS" SG_ 2654486676 FD14_CBV_bit4_ActiveWakeupBit 0;
BA_ "GenSigTimeoutTime_ORC" SG_ 2654486676 FD14_CBV_bit4_ActiveWakeupBit 0;
BA_ "GenSigTimeoutTime_BSM" SG_ 2654486676 FD14_CBV_bit5 0;
BA_ "GenSigTimeoutTime_BSM2" SG_ 2654486676 FD14_CBV_bit5 0;
BA_ "GenSigTimeoutTime_CADM" SG_ 2654486676 FD14_CBV_bit5 0;
BA_ "GenSigTimeoutTime_CVADAS" SG_ 2654486676 FD14_CBV_bit5 0;
BA_ "GenSigTimeoutTime_ECM" SG_ 2654486676 FD14_CBV_bit5 0;
BA_ "GenSigTimeoutTime_EPS" SG_ 2654486676 FD14_CBV_bit5 0;
BA_ "GenSigTimeoutTime_ORC" SG_ 2654486676 FD14_CBV_bit5 0;
BA_ "GenSigTimeoutTime_BSM" SG_ 2654486676 FD14_CBV_bit6_PartialNtwInfBit 0;
BA_ "GenSigTimeoutTime_BSM2" SG_ 2654486676 FD14_CBV_bit6_PartialNtwInfBit 0;
BA_ "GenSigTimeoutTime_CADM" SG_ 2654486676 FD14_CBV_bit6_PartialNtwInfBit 0;
BA_ "GenSigTimeoutTime_CVADAS" SG_ 2654486676 FD14_CBV_bit6_PartialNtwInfBit 0;
BA_ "GenSigTimeoutTime_ECM" SG_ 2654486676 FD14_CBV_bit6_PartialNtwInfBit 0;
BA_ "GenSigTimeoutTime_EPS" SG_ 2654486676 FD14_CBV_bit6_PartialNtwInfBit 0;
BA_ "GenSigTimeoutTime_ORC" SG_ 2654486676 FD14_CBV_bit6_PartialNtwInfBit 0;
BA_ "GenSigTimeoutTime_BSM" SG_ 2654486676 FD14_CBV_bit7 0;
BA_ "GenSigTimeoutTime_BSM2" SG_ 2654486676 FD14_CBV_bit7 0;
BA_ "GenSigTimeoutTime_CADM" SG_ 2654486676 FD14_CBV_bit7 0;
BA_ "GenSigTimeoutTime_CVADAS" SG_ 2654486676 FD14_CBV_bit7 0;
BA_ "GenSigTimeoutTime_ECM" SG_ 2654486676 FD14_CBV_bit7 0;
BA_ "GenSigTimeoutTime_EPS" SG_ 2654486676 FD14_CBV_bit7 0;
BA_ "GenSigTimeoutTime_ORC" SG_ 2654486676 FD14_CBV_bit7 0;
BA_ "GenSigTimeoutTime_BSM" SG_ 2654486676 FD14_SourceNodeIdentifier 0;
BA_ "GenSigTimeoutTime_BSM2" SG_ 2654486676 FD14_SourceNodeIdentifier 0;
BA_ "GenSigTimeoutTime_CADM" SG_ 2654486676 FD14_SourceNodeIdentifier 0;
BA_ "GenSigTimeoutTime_CVADAS" SG_ 2654486676 FD14_SourceNodeIdentifier 0;
BA_ "GenSigTimeoutTime_ECM" SG_ 2654486676 FD14_SourceNodeIdentifier 0;
BA_ "GenSigTimeoutTime_EPS" SG_ 2654486676 FD14_SourceNodeIdentifier 0;
BA_ "GenSigTimeoutTime_ORC" SG_ 2654486676 FD14_SourceNodeIdentifier 0;
BA_ "GenSigTimeoutTime_BSM" SG_ 2654486669 FD14_CBV_bit0_RepeatMessage_0001 0;
BA_ "GenSigTimeoutTime_BSM2" SG_ 2654486669 FD14_CBV_bit0_RepeatMessage_0001 0;
BA_ "GenSigTimeoutTime_CADM" SG_ 2654486669 FD14_CBV_bit0_RepeatMessage_0001 0;
BA_ "GenSigTimeoutTime_CVADAS" SG_ 2654486669 FD14_CBV_bit0_RepeatMessage_0001 0;
BA_ "GenSigTimeoutTime_ECM" SG_ 2654486669 FD14_CBV_bit0_RepeatMessage_0001 0;
BA_ "GenSigTimeoutTime_EPS" SG_ 2654486669 FD14_CBV_bit0_RepeatMessage_0001 0;
BA_ "GenSigTimeoutTime_ORC" SG_ 2654486669 FD14_CBV_bit0_RepeatMessage_0001 0;
BA_ "SystemSignalLongSymbol" SG_ 2654486669 FD14_CBV_bit0_RepeatMessage_0001 "FD14_CBV_bit0_RepeatMessageRequestBit";
BA_ "GenSigTimeoutTime_BSM" SG_ 2654486669 FD14_CBV_bit1 0;
BA_ "GenSigTimeoutTime_BSM2" SG_ 2654486669 FD14_CBV_bit1 0;
BA_ "GenSigTimeoutTime_CADM" SG_ 2654486669 FD14_CBV_bit1 0;
BA_ "GenSigTimeoutTime_CVADAS" SG_ 2654486669 FD14_CBV_bit1 0;
BA_ "GenSigTimeoutTime_ECM" SG_ 2654486669 FD14_CBV_bit1 0;
BA_ "GenSigTimeoutTime_EPS" SG_ 2654486669 FD14_CBV_bit1 0;
BA_ "GenSigTimeoutTime_ORC" SG_ 2654486669 FD14_CBV_bit1 0;
BA_ "GenSigTimeoutTime_BSM" SG_ 2654486669 FD14_CBV_bit2 0;
BA_ "GenSigTimeoutTime_BSM2" SG_ 2654486669 FD14_CBV_bit2 0;
BA_ "GenSigTimeoutTime_CADM" SG_ 2654486669 FD14_CBV_bit2 0;
BA_ "GenSigTimeoutTime_CVADAS" SG_ 2654486669 FD14_CBV_bit2 0;
BA_ "GenSigTimeoutTime_ECM" SG_ 2654486669 FD14_CBV_bit2 0;
BA_ "GenSigTimeoutTime_EPS" SG_ 2654486669 FD14_CBV_bit2 0;
BA_ "GenSigTimeoutTime_ORC" SG_ 2654486669 FD14_CBV_bit2 0;
BA_ "GenSigTimeoutTime_BSM" SG_ 2654486669 FD14_CBV_bit3_NMCoordinatorBit 0;
BA_ "GenSigTimeoutTime_BSM2" SG_ 2654486669 FD14_CBV_bit3_NMCoordinatorBit 0;
BA_ "GenSigTimeoutTime_CADM" SG_ 2654486669 FD14_CBV_bit3_NMCoordinatorBit 0;
BA_ "GenSigTimeoutTime_CVADAS" SG_ 2654486669 FD14_CBV_bit3_NMCoordinatorBit 0;
BA_ "GenSigTimeoutTime_ECM" SG_ 2654486669 FD14_CBV_bit3_NMCoordinatorBit 0;
BA_ "GenSigTimeoutTime_EPS" SG_ 2654486669 FD14_CBV_bit3_NMCoordinatorBit 0;
BA_ "GenSigTimeoutTime_ORC" SG_ 2654486669 FD14_CBV_bit3_NMCoordinatorBit 0;
BA_ "GenSigTimeoutTime_BSM" SG_ 2654486669 FD14_CBV_bit4_ActiveWakeupBit 0;
BA_ "GenSigTimeoutTime_BSM2" SG_ 2654486669 FD14_CBV_bit4_ActiveWakeupBit 0;
BA_ "GenSigTimeoutTime_CADM" SG_ 2654486669 FD14_CBV_bit4_ActiveWakeupBit 0;
BA_ "GenSigTimeoutTime_CVADAS" SG_ 2654486669 FD14_CBV_bit4_ActiveWakeupBit 0;
BA_ "GenSigTimeoutTime_ECM" SG_ 2654486669 FD14_CBV_bit4_ActiveWakeupBit 0;
BA_ "GenSigTimeoutTime_EPS" SG_ 2654486669 FD14_CBV_bit4_ActiveWakeupBit 0;
BA_ "GenSigTimeoutTime_ORC" SG_ 2654486669 FD14_CBV_bit4_ActiveWakeupBit 0;
BA_ "GenSigTimeoutTime_BSM" SG_ 2654486669 FD14_CBV_bit5 0;
BA_ "GenSigTimeoutTime_BSM2" SG_ 2654486669 FD14_CBV_bit5 0;
BA_ "GenSigTimeoutTime_CADM" SG_ 2654486669 FD14_CBV_bit5 0;
BA_ "GenSigTimeoutTime_CVADAS" SG_ 2654486669 FD14_CBV_bit5 0;
BA_ "GenSigTimeoutTime_ECM" SG_ 2654486669 FD14_CBV_bit5 0;
BA_ "GenSigTimeoutTime_EPS" SG_ 2654486669 FD14_CBV_bit5 0;
BA_ "GenSigTimeoutTime_ORC" SG_ 2654486669 FD14_CBV_bit5 0;
BA_ "GenSigTimeoutTime_BSM" SG_ 2654486669 FD14_CBV_bit6_PartialNtwInfBit 0;
BA_ "GenSigTimeoutTime_BSM2" SG_ 2654486669 FD14_CBV_bit6_PartialNtwInfBit 0;
BA_ "GenSigTimeoutTime_CADM" SG_ 2654486669 FD14_CBV_bit6_PartialNtwInfBit 0;
BA_ "GenSigTimeoutTime_CVADAS" SG_ 2654486669 FD14_CBV_bit6_PartialNtwInfBit 0;
BA_ "GenSigTimeoutTime_ECM" SG_ 2654486669 FD14_CBV_bit6_PartialNtwInfBit 0;
BA_ "GenSigTimeoutTime_EPS" SG_ 2654486669 FD14_CBV_bit6_PartialNtwInfBit 0;
BA_ "GenSigTimeoutTime_ORC" SG_ 2654486669 FD14_CBV_bit6_PartialNtwInfBit 0;
BA_ "GenSigTimeoutTime_BSM" SG_ 2654486669 FD14_CBV_bit7 0;
BA_ "GenSigTimeoutTime_BSM2" SG_ 2654486669 FD14_CBV_bit7 0;
BA_ "GenSigTimeoutTime_CADM" SG_ 2654486669 FD14_CBV_bit7 0;
BA_ "GenSigTimeoutTime_CVADAS" SG_ 2654486669 FD14_CBV_bit7 0;
BA_ "GenSigTimeoutTime_ECM" SG_ 2654486669 FD14_CBV_bit7 0;
BA_ "GenSigTimeoutTime_EPS" SG_ 2654486669 FD14_CBV_bit7 0;
BA_ "GenSigTimeoutTime_ORC" SG_ 2654486669 FD14_CBV_bit7 0;
BA_ "GenSigTimeoutTime_BSM" SG_ 2654486669 FD14_SourceNodeIdentifier 0;
BA_ "GenSigTimeoutTime_BSM2" SG_ 2654486669 FD14_SourceNodeIdentifier 0;
BA_ "GenSigTimeoutTime_CADM" SG_ 2654486669 FD14_SourceNodeIdentifier 0;
BA_ "GenSigTimeoutTime_CVADAS" SG_ 2654486669 FD14_SourceNodeIdentifier 0;
BA_ "GenSigTimeoutTime_ECM" SG_ 2654486669 FD14_SourceNodeIdentifier 0;
BA_ "GenSigTimeoutTime_EPS" SG_ 2654486669 FD14_SourceNodeIdentifier 0;
BA_ "GenSigTimeoutTime_ORC" SG_ 2654486669 FD14_SourceNodeIdentifier 0;
BA_ "GenSigTimeoutTime_BSM" SG_ 2654486529 FD14_CBV_bit0_RepeatMessage_0002 0;
BA_ "GenSigTimeoutTime_BSM2" SG_ 2654486529 FD14_CBV_bit0_RepeatMessage_0002 0;
BA_ "GenSigTimeoutTime_CADM" SG_ 2654486529 FD14_CBV_bit0_RepeatMessage_0002 0;
BA_ "GenSigTimeoutTime_CVADAS" SG_ 2654486529 FD14_CBV_bit0_RepeatMessage_0002 0;
BA_ "GenSigTimeoutTime_ECM" SG_ 2654486529 FD14_CBV_bit0_RepeatMessage_0002 0;
BA_ "GenSigTimeoutTime_EPS" SG_ 2654486529 FD14_CBV_bit0_RepeatMessage_0002 0;
BA_ "GenSigTimeoutTime_ORC" SG_ 2654486529 FD14_CBV_bit0_RepeatMessage_0002 0;
BA_ "SystemSignalLongSymbol" SG_ 2654486529 FD14_CBV_bit0_RepeatMessage_0002 "FD14_CBV_bit0_RepeatMessageRequestBit";
BA_ "GenSigTimeoutTime_BSM" SG_ 2654486529 FD14_CBV_bit1 0;
BA_ "GenSigTimeoutTime_BSM2" SG_ 2654486529 FD14_CBV_bit1 0;
BA_ "GenSigTimeoutTime_CADM" SG_ 2654486529 FD14_CBV_bit1 0;
BA_ "GenSigTimeoutTime_CVADAS" SG_ 2654486529 FD14_CBV_bit1 0;
BA_ "GenSigTimeoutTime_ECM" SG_ 2654486529 FD14_CBV_bit1 0;
BA_ "GenSigTimeoutTime_EPS" SG_ 2654486529 FD14_CBV_bit1 0;
BA_ "GenSigTimeoutTime_ORC" SG_ 2654486529 FD14_CBV_bit1 0;
BA_ "GenSigTimeoutTime_BSM" SG_ 2654486529 FD14_CBV_bit2 0;
BA_ "GenSigTimeoutTime_BSM2" SG_ 2654486529 FD14_CBV_bit2 0;
BA_ "GenSigTimeoutTime_CADM" SG_ 2654486529 FD14_CBV_bit2 0;
BA_ "GenSigTimeoutTime_CVADAS" SG_ 2654486529 FD14_CBV_bit2 0;
BA_ "GenSigTimeoutTime_ECM" SG_ 2654486529 FD14_CBV_bit2 0;
BA_ "GenSigTimeoutTime_EPS" SG_ 2654486529 FD14_CBV_bit2 0;
BA_ "GenSigTimeoutTime_ORC" SG_ 2654486529 FD14_CBV_bit2 0;
BA_ "GenSigTimeoutTime_BSM" SG_ 2654486529 FD14_CBV_bit3_NMCoordinatorBit 0;
BA_ "GenSigTimeoutTime_BSM2" SG_ 2654486529 FD14_CBV_bit3_NMCoordinatorBit 0;
BA_ "GenSigTimeoutTime_CADM" SG_ 2654486529 FD14_CBV_bit3_NMCoordinatorBit 0;
BA_ "GenSigTimeoutTime_CVADAS" SG_ 2654486529 FD14_CBV_bit3_NMCoordinatorBit 0;
BA_ "GenSigTimeoutTime_ECM" SG_ 2654486529 FD14_CBV_bit3_NMCoordinatorBit 0;
BA_ "GenSigTimeoutTime_EPS" SG_ 2654486529 FD14_CBV_bit3_NMCoordinatorBit 0;
BA_ "GenSigTimeoutTime_ORC" SG_ 2654486529 FD14_CBV_bit3_NMCoordinatorBit 0;
BA_ "GenSigTimeoutTime_BSM" SG_ 2654486529 FD14_CBV_bit4_ActiveWakeupBit 0;
BA_ "GenSigTimeoutTime_BSM2" SG_ 2654486529 FD14_CBV_bit4_ActiveWakeupBit 0;
BA_ "GenSigTimeoutTime_CADM" SG_ 2654486529 FD14_CBV_bit4_ActiveWakeupBit 0;
BA_ "GenSigTimeoutTime_CVADAS" SG_ 2654486529 FD14_CBV_bit4_ActiveWakeupBit 0;
BA_ "GenSigTimeoutTime_ECM" SG_ 2654486529 FD14_CBV_bit4_ActiveWakeupBit 0;
BA_ "GenSigTimeoutTime_EPS" SG_ 2654486529 FD14_CBV_bit4_ActiveWakeupBit 0;
BA_ "GenSigTimeoutTime_ORC" SG_ 2654486529 FD14_CBV_bit4_ActiveWakeupBit 0;
BA_ "GenSigTimeoutTime_BSM" SG_ 2654486529 FD14_CBV_bit5 0;
BA_ "GenSigTimeoutTime_BSM2" SG_ 2654486529 FD14_CBV_bit5 0;
BA_ "GenSigTimeoutTime_CADM" SG_ 2654486529 FD14_CBV_bit5 0;
BA_ "GenSigTimeoutTime_CVADAS" SG_ 2654486529 FD14_CBV_bit5 0;
BA_ "GenSigTimeoutTime_ECM" SG_ 2654486529 FD14_CBV_bit5 0;
BA_ "GenSigTimeoutTime_EPS" SG_ 2654486529 FD14_CBV_bit5 0;
BA_ "GenSigTimeoutTime_ORC" SG_ 2654486529 FD14_CBV_bit5 0;
BA_ "GenSigTimeoutTime_BSM" SG_ 2654486529 FD14_CBV_bit6_PartialNtwInfBit 0;
BA_ "GenSigTimeoutTime_BSM2" SG_ 2654486529 FD14_CBV_bit6_PartialNtwInfBit 0;
BA_ "GenSigTimeoutTime_CADM" SG_ 2654486529 FD14_CBV_bit6_PartialNtwInfBit 0;
BA_ "GenSigTimeoutTime_CVADAS" SG_ 2654486529 FD14_CBV_bit6_PartialNtwInfBit 0;
BA_ "GenSigTimeoutTime_ECM" SG_ 2654486529 FD14_CBV_bit6_PartialNtwInfBit 0;
BA_ "GenSigTimeoutTime_EPS" SG_ 2654486529 FD14_CBV_bit6_PartialNtwInfBit 0;
BA_ "GenSigTimeoutTime_ORC" SG_ 2654486529 FD14_CBV_bit6_PartialNtwInfBit 0;
BA_ "GenSigTimeoutTime_BSM" SG_ 2654486529 FD14_CBV_bit7 0;
BA_ "GenSigTimeoutTime_BSM2" SG_ 2654486529 FD14_CBV_bit7 0;
BA_ "GenSigTimeoutTime_CADM" SG_ 2654486529 FD14_CBV_bit7 0;
BA_ "GenSigTimeoutTime_CVADAS" SG_ 2654486529 FD14_CBV_bit7 0;
BA_ "GenSigTimeoutTime_ECM" SG_ 2654486529 FD14_CBV_bit7 0;
BA_ "GenSigTimeoutTime_EPS" SG_ 2654486529 FD14_CBV_bit7 0;
BA_ "GenSigTimeoutTime_ORC" SG_ 2654486529 FD14_CBV_bit7 0;
BA_ "GenSigTimeoutTime_BSM" SG_ 2654486529 FD14_SourceNodeIdentifier 0;
BA_ "GenSigTimeoutTime_BSM2" SG_ 2654486529 FD14_SourceNodeIdentifier 0;
BA_ "GenSigTimeoutTime_CADM" SG_ 2654486529 FD14_SourceNodeIdentifier 0;
BA_ "GenSigTimeoutTime_CVADAS" SG_ 2654486529 FD14_SourceNodeIdentifier 0;
BA_ "GenSigTimeoutTime_ECM" SG_ 2654486529 FD14_SourceNodeIdentifier 0;
BA_ "GenSigTimeoutTime_EPS" SG_ 2654486529 FD14_SourceNodeIdentifier 0;
BA_ "GenSigTimeoutTime_ORC" SG_ 2654486529 FD14_SourceNodeIdentifier 0;
BA_ "GenSigTimeoutTime_BSM" SG_ 2654486530 FD14_CBV_bit0_RepeatMessage_0003 0;
BA_ "GenSigTimeoutTime_BSM2" SG_ 2654486530 FD14_CBV_bit0_RepeatMessage_0003 0;
BA_ "GenSigTimeoutTime_CADM" SG_ 2654486530 FD14_CBV_bit0_RepeatMessage_0003 0;
BA_ "GenSigTimeoutTime_CVADAS" SG_ 2654486530 FD14_CBV_bit0_RepeatMessage_0003 0;
BA_ "GenSigTimeoutTime_ECM" SG_ 2654486530 FD14_CBV_bit0_RepeatMessage_0003 0;
BA_ "GenSigTimeoutTime_EPS" SG_ 2654486530 FD14_CBV_bit0_RepeatMessage_0003 0;
BA_ "GenSigTimeoutTime_ORC" SG_ 2654486530 FD14_CBV_bit0_RepeatMessage_0003 0;
BA_ "SystemSignalLongSymbol" SG_ 2654486530 FD14_CBV_bit0_RepeatMessage_0003 "FD14_CBV_bit0_RepeatMessageRequestBit";
BA_ "GenSigTimeoutTime_BSM" SG_ 2654486530 FD14_CBV_bit1 0;
BA_ "GenSigTimeoutTime_BSM2" SG_ 2654486530 FD14_CBV_bit1 0;
BA_ "GenSigTimeoutTime_CADM" SG_ 2654486530 FD14_CBV_bit1 0;
BA_ "GenSigTimeoutTime_CVADAS" SG_ 2654486530 FD14_CBV_bit1 0;
BA_ "GenSigTimeoutTime_ECM" SG_ 2654486530 FD14_CBV_bit1 0;
BA_ "GenSigTimeoutTime_EPS" SG_ 2654486530 FD14_CBV_bit1 0;
BA_ "GenSigTimeoutTime_ORC" SG_ 2654486530 FD14_CBV_bit1 0;
BA_ "GenSigTimeoutTime_BSM" SG_ 2654486530 FD14_CBV_bit2 0;
BA_ "GenSigTimeoutTime_BSM2" SG_ 2654486530 FD14_CBV_bit2 0;
BA_ "GenSigTimeoutTime_CADM" SG_ 2654486530 FD14_CBV_bit2 0;
BA_ "GenSigTimeoutTime_CVADAS" SG_ 2654486530 FD14_CBV_bit2 0;
BA_ "GenSigTimeoutTime_ECM" SG_ 2654486530 FD14_CBV_bit2 0;
BA_ "GenSigTimeoutTime_EPS" SG_ 2654486530 FD14_CBV_bit2 0;
BA_ "GenSigTimeoutTime_ORC" SG_ 2654486530 FD14_CBV_bit2 0;
BA_ "GenSigTimeoutTime_BSM" SG_ 2654486530 FD14_CBV_bit3_NMCoordinatorBit 0;
BA_ "GenSigTimeoutTime_BSM2" SG_ 2654486530 FD14_CBV_bit3_NMCoordinatorBit 0;
BA_ "GenSigTimeoutTime_CADM" SG_ 2654486530 FD14_CBV_bit3_NMCoordinatorBit 0;
BA_ "GenSigTimeoutTime_CVADAS" SG_ 2654486530 FD14_CBV_bit3_NMCoordinatorBit 0;
BA_ "GenSigTimeoutTime_ECM" SG_ 2654486530 FD14_CBV_bit3_NMCoordinatorBit 0;
BA_ "GenSigTimeoutTime_EPS" SG_ 2654486530 FD14_CBV_bit3_NMCoordinatorBit 0;
BA_ "GenSigTimeoutTime_ORC" SG_ 2654486530 FD14_CBV_bit3_NMCoordinatorBit 0;
BA_ "GenSigTimeoutTime_BSM" SG_ 2654486530 FD14_CBV_bit4_ActiveWakeupBit 0;
BA_ "GenSigTimeoutTime_BSM2" SG_ 2654486530 FD14_CBV_bit4_ActiveWakeupBit 0;
BA_ "GenSigTimeoutTime_CADM" SG_ 2654486530 FD14_CBV_bit4_ActiveWakeupBit 0;
BA_ "GenSigTimeoutTime_CVADAS" SG_ 2654486530 FD14_CBV_bit4_ActiveWakeupBit 0;
BA_ "GenSigTimeoutTime_ECM" SG_ 2654486530 FD14_CBV_bit4_ActiveWakeupBit 0;
BA_ "GenSigTimeoutTime_EPS" SG_ 2654486530 FD14_CBV_bit4_ActiveWakeupBit 0;
BA_ "GenSigTimeoutTime_ORC" SG_ 2654486530 FD14_CBV_bit4_ActiveWakeupBit 0;
BA_ "GenSigTimeoutTime_BSM" SG_ 2654486530 FD14_CBV_bit5 0;
BA_ "GenSigTimeoutTime_BSM2" SG_ 2654486530 FD14_CBV_bit5 0;
BA_ "GenSigTimeoutTime_CADM" SG_ 2654486530 FD14_CBV_bit5 0;
BA_ "GenSigTimeoutTime_CVADAS" SG_ 2654486530 FD14_CBV_bit5 0;
BA_ "GenSigTimeoutTime_ECM" SG_ 2654486530 FD14_CBV_bit5 0;
BA_ "GenSigTimeoutTime_EPS" SG_ 2654486530 FD14_CBV_bit5 0;
BA_ "GenSigTimeoutTime_ORC" SG_ 2654486530 FD14_CBV_bit5 0;
BA_ "GenSigTimeoutTime_BSM" SG_ 2654486530 FD14_CBV_bit6_PartialNtwInfBit 0;
BA_ "GenSigTimeoutTime_BSM2" SG_ 2654486530 FD14_CBV_bit6_PartialNtwInfBit 0;
BA_ "GenSigTimeoutTime_CADM" SG_ 2654486530 FD14_CBV_bit6_PartialNtwInfBit 0;
BA_ "GenSigTimeoutTime_CVADAS" SG_ 2654486530 FD14_CBV_bit6_PartialNtwInfBit 0;
BA_ "GenSigTimeoutTime_ECM" SG_ 2654486530 FD14_CBV_bit6_PartialNtwInfBit 0;
BA_ "GenSigTimeoutTime_EPS" SG_ 2654486530 FD14_CBV_bit6_PartialNtwInfBit 0;
BA_ "GenSigTimeoutTime_ORC" SG_ 2654486530 FD14_CBV_bit6_PartialNtwInfBit 0;
BA_ "GenSigTimeoutTime_BSM" SG_ 2654486530 FD14_CBV_bit7 0;
BA_ "GenSigTimeoutTime_BSM2" SG_ 2654486530 FD14_CBV_bit7 0;
BA_ "GenSigTimeoutTime_CADM" SG_ 2654486530 FD14_CBV_bit7 0;
BA_ "GenSigTimeoutTime_CVADAS" SG_ 2654486530 FD14_CBV_bit7 0;
BA_ "GenSigTimeoutTime_ECM" SG_ 2654486530 FD14_CBV_bit7 0;
BA_ "GenSigTimeoutTime_EPS" SG_ 2654486530 FD14_CBV_bit7 0;
BA_ "GenSigTimeoutTime_ORC" SG_ 2654486530 FD14_CBV_bit7 0;
BA_ "GenSigTimeoutTime_BSM" SG_ 2654486530 FD14_SourceNodeIdentifier 0;
BA_ "GenSigTimeoutTime_BSM2" SG_ 2654486530 FD14_SourceNodeIdentifier 0;
BA_ "GenSigTimeoutTime_CADM" SG_ 2654486530 FD14_SourceNodeIdentifier 0;
BA_ "GenSigTimeoutTime_CVADAS" SG_ 2654486530 FD14_SourceNodeIdentifier 0;
BA_ "GenSigTimeoutTime_ECM" SG_ 2654486530 FD14_SourceNodeIdentifier 0;
BA_ "GenSigTimeoutTime_EPS" SG_ 2654486530 FD14_SourceNodeIdentifier 0;
BA_ "GenSigTimeoutTime_ORC" SG_ 2654486530 FD14_SourceNodeIdentifier 0;
BA_ "GenSigTimeoutTime_BSM" SG_ 2654486554 FD14_CBV_bit0_RepeatMessage_0004 0;
BA_ "GenSigTimeoutTime_BSM2" SG_ 2654486554 FD14_CBV_bit0_RepeatMessage_0004 0;
BA_ "GenSigTimeoutTime_CADM" SG_ 2654486554 FD14_CBV_bit0_RepeatMessage_0004 0;
BA_ "GenSigTimeoutTime_CVADAS" SG_ 2654486554 FD14_CBV_bit0_RepeatMessage_0004 0;
BA_ "GenSigTimeoutTime_ECM" SG_ 2654486554 FD14_CBV_bit0_RepeatMessage_0004 0;
BA_ "GenSigTimeoutTime_EPS" SG_ 2654486554 FD14_CBV_bit0_RepeatMessage_0004 0;
BA_ "GenSigTimeoutTime_ORC" SG_ 2654486554 FD14_CBV_bit0_RepeatMessage_0004 0;
BA_ "SystemSignalLongSymbol" SG_ 2654486554 FD14_CBV_bit0_RepeatMessage_0004 "FD14_CBV_bit0_RepeatMessageRequestBit";
BA_ "GenSigTimeoutTime_BSM" SG_ 2654486554 FD14_CBV_bit1 0;
BA_ "GenSigTimeoutTime_BSM2" SG_ 2654486554 FD14_CBV_bit1 0;
BA_ "GenSigTimeoutTime_CADM" SG_ 2654486554 FD14_CBV_bit1 0;
BA_ "GenSigTimeoutTime_CVADAS" SG_ 2654486554 FD14_CBV_bit1 0;
BA_ "GenSigTimeoutTime_ECM" SG_ 2654486554 FD14_CBV_bit1 0;
BA_ "GenSigTimeoutTime_EPS" SG_ 2654486554 FD14_CBV_bit1 0;
BA_ "GenSigTimeoutTime_ORC" SG_ 2654486554 FD14_CBV_bit1 0;
BA_ "GenSigTimeoutTime_BSM" SG_ 2654486554 FD14_CBV_bit2 0;
BA_ "GenSigTimeoutTime_BSM2" SG_ 2654486554 FD14_CBV_bit2 0;
BA_ "GenSigTimeoutTime_CADM" SG_ 2654486554 FD14_CBV_bit2 0;
BA_ "GenSigTimeoutTime_CVADAS" SG_ 2654486554 FD14_CBV_bit2 0;
BA_ "GenSigTimeoutTime_ECM" SG_ 2654486554 FD14_CBV_bit2 0;
BA_ "GenSigTimeoutTime_EPS" SG_ 2654486554 FD14_CBV_bit2 0;
BA_ "GenSigTimeoutTime_ORC" SG_ 2654486554 FD14_CBV_bit2 0;
BA_ "GenSigTimeoutTime_BSM" SG_ 2654486554 FD14_CBV_bit3_NMCoordinatorBit 0;
BA_ "GenSigTimeoutTime_BSM2" SG_ 2654486554 FD14_CBV_bit3_NMCoordinatorBit 0;
BA_ "GenSigTimeoutTime_CADM" SG_ 2654486554 FD14_CBV_bit3_NMCoordinatorBit 0;
BA_ "GenSigTimeoutTime_CVADAS" SG_ 2654486554 FD14_CBV_bit3_NMCoordinatorBit 0;
BA_ "GenSigTimeoutTime_ECM" SG_ 2654486554 FD14_CBV_bit3_NMCoordinatorBit 0;
BA_ "GenSigTimeoutTime_EPS" SG_ 2654486554 FD14_CBV_bit3_NMCoordinatorBit 0;
BA_ "GenSigTimeoutTime_ORC" SG_ 2654486554 FD14_CBV_bit3_NMCoordinatorBit 0;
BA_ "GenSigTimeoutTime_BSM" SG_ 2654486554 FD14_CBV_bit4_ActiveWakeupBit 0;
BA_ "GenSigTimeoutTime_BSM2" SG_ 2654486554 FD14_CBV_bit4_ActiveWakeupBit 0;
BA_ "GenSigTimeoutTime_CADM" SG_ 2654486554 FD14_CBV_bit4_ActiveWakeupBit 0;
BA_ "GenSigTimeoutTime_CVADAS" SG_ 2654486554 FD14_CBV_bit4_ActiveWakeupBit 0;
BA_ "GenSigTimeoutTime_ECM" SG_ 2654486554 FD14_CBV_bit4_ActiveWakeupBit 0;
BA_ "GenSigTimeoutTime_EPS" SG_ 2654486554 FD14_CBV_bit4_ActiveWakeupBit 0;
BA_ "GenSigTimeoutTime_ORC" SG_ 2654486554 FD14_CBV_bit4_ActiveWakeupBit 0;
BA_ "GenSigTimeoutTime_BSM" SG_ 2654486554 FD14_CBV_bit5 0;
BA_ "GenSigTimeoutTime_BSM2" SG_ 2654486554 FD14_CBV_bit5 0;
BA_ "GenSigTimeoutTime_CADM" SG_ 2654486554 FD14_CBV_bit5 0;
BA_ "GenSigTimeoutTime_CVADAS" SG_ 2654486554 FD14_CBV_bit5 0;
BA_ "GenSigTimeoutTime_ECM" SG_ 2654486554 FD14_CBV_bit5 0;
BA_ "GenSigTimeoutTime_EPS" SG_ 2654486554 FD14_CBV_bit5 0;
BA_ "GenSigTimeoutTime_ORC" SG_ 2654486554 FD14_CBV_bit5 0;
BA_ "GenSigTimeoutTime_BSM" SG_ 2654486554 FD14_CBV_bit6_PartialNtwInfBit 0;
BA_ "GenSigTimeoutTime_BSM2" SG_ 2654486554 FD14_CBV_bit6_PartialNtwInfBit 0;
BA_ "GenSigTimeoutTime_CADM" SG_ 2654486554 FD14_CBV_bit6_PartialNtwInfBit 0;
BA_ "GenSigTimeoutTime_CVADAS" SG_ 2654486554 FD14_CBV_bit6_PartialNtwInfBit 0;
BA_ "GenSigTimeoutTime_ECM" SG_ 2654486554 FD14_CBV_bit6_PartialNtwInfBit 0;
BA_ "GenSigTimeoutTime_EPS" SG_ 2654486554 FD14_CBV_bit6_PartialNtwInfBit 0;
BA_ "GenSigTimeoutTime_ORC" SG_ 2654486554 FD14_CBV_bit6_PartialNtwInfBit 0;
BA_ "GenSigTimeoutTime_BSM" SG_ 2654486554 FD14_CBV_bit7 0;
BA_ "GenSigTimeoutTime_BSM2" SG_ 2654486554 FD14_CBV_bit7 0;
BA_ "GenSigTimeoutTime_CADM" SG_ 2654486554 FD14_CBV_bit7 0;
BA_ "GenSigTimeoutTime_CVADAS" SG_ 2654486554 FD14_CBV_bit7 0;
BA_ "GenSigTimeoutTime_ECM" SG_ 2654486554 FD14_CBV_bit7 0;
BA_ "GenSigTimeoutTime_EPS" SG_ 2654486554 FD14_CBV_bit7 0;
BA_ "GenSigTimeoutTime_ORC" SG_ 2654486554 FD14_CBV_bit7 0;
BA_ "GenSigTimeoutTime_BSM" SG_ 2654486554 FD14_SourceNodeIdentifier 0;
BA_ "GenSigTimeoutTime_BSM2" SG_ 2654486554 FD14_SourceNodeIdentifier 0;
BA_ "GenSigTimeoutTime_CADM" SG_ 2654486554 FD14_SourceNodeIdentifier 0;
BA_ "GenSigTimeoutTime_CVADAS" SG_ 2654486554 FD14_SourceNodeIdentifier 0;
BA_ "GenSigTimeoutTime_ECM" SG_ 2654486554 FD14_SourceNodeIdentifier 0;
BA_ "GenSigTimeoutTime_EPS" SG_ 2654486554 FD14_SourceNodeIdentifier 0;
BA_ "GenSigTimeoutTime_ORC" SG_ 2654486554 FD14_SourceNodeIdentifier 0;
BA_ "GenSigTimeoutTime_BSM" SG_ 2654486552 FD14_CBV_bit0_RepeatMessage_0005 0;
BA_ "GenSigTimeoutTime_BSM2" SG_ 2654486552 FD14_CBV_bit0_RepeatMessage_0005 0;
BA_ "GenSigTimeoutTime_CADM" SG_ 2654486552 FD14_CBV_bit0_RepeatMessage_0005 0;
BA_ "GenSigTimeoutTime_CVADAS" SG_ 2654486552 FD14_CBV_bit0_RepeatMessage_0005 0;
BA_ "GenSigTimeoutTime_ECM" SG_ 2654486552 FD14_CBV_bit0_RepeatMessage_0005 0;
BA_ "GenSigTimeoutTime_EPS" SG_ 2654486552 FD14_CBV_bit0_RepeatMessage_0005 0;
BA_ "GenSigTimeoutTime_ORC" SG_ 2654486552 FD14_CBV_bit0_RepeatMessage_0005 0;
BA_ "SystemSignalLongSymbol" SG_ 2654486552 FD14_CBV_bit0_RepeatMessage_0005 "FD14_CBV_bit0_RepeatMessageRequestBit";
BA_ "GenSigTimeoutTime_BSM" SG_ 2654486552 FD14_CBV_bit1 0;
BA_ "GenSigTimeoutTime_BSM2" SG_ 2654486552 FD14_CBV_bit1 0;
BA_ "GenSigTimeoutTime_CADM" SG_ 2654486552 FD14_CBV_bit1 0;
BA_ "GenSigTimeoutTime_CVADAS" SG_ 2654486552 FD14_CBV_bit1 0;
BA_ "GenSigTimeoutTime_ECM" SG_ 2654486552 FD14_CBV_bit1 0;
BA_ "GenSigTimeoutTime_EPS" SG_ 2654486552 FD14_CBV_bit1 0;
BA_ "GenSigTimeoutTime_ORC" SG_ 2654486552 FD14_CBV_bit1 0;
BA_ "GenSigTimeoutTime_BSM" SG_ 2654486552 FD14_CBV_bit2 0;
BA_ "GenSigTimeoutTime_BSM2" SG_ 2654486552 FD14_CBV_bit2 0;
BA_ "GenSigTimeoutTime_CADM" SG_ 2654486552 FD14_CBV_bit2 0;
BA_ "GenSigTimeoutTime_CVADAS" SG_ 2654486552 FD14_CBV_bit2 0;
BA_ "GenSigTimeoutTime_ECM" SG_ 2654486552 FD14_CBV_bit2 0;
BA_ "GenSigTimeoutTime_EPS" SG_ 2654486552 FD14_CBV_bit2 0;
BA_ "GenSigTimeoutTime_ORC" SG_ 2654486552 FD14_CBV_bit2 0;
BA_ "GenSigTimeoutTime_BSM" SG_ 2654486552 FD14_CBV_bit3_NMCoordinatorBit 0;
BA_ "GenSigTimeoutTime_BSM2" SG_ 2654486552 FD14_CBV_bit3_NMCoordinatorBit 0;
BA_ "GenSigTimeoutTime_CADM" SG_ 2654486552 FD14_CBV_bit3_NMCoordinatorBit 0;
BA_ "GenSigTimeoutTime_CVADAS" SG_ 2654486552 FD14_CBV_bit3_NMCoordinatorBit 0;
BA_ "GenSigTimeoutTime_ECM" SG_ 2654486552 FD14_CBV_bit3_NMCoordinatorBit 0;
BA_ "GenSigTimeoutTime_EPS" SG_ 2654486552 FD14_CBV_bit3_NMCoordinatorBit 0;
BA_ "GenSigTimeoutTime_ORC" SG_ 2654486552 FD14_CBV_bit3_NMCoordinatorBit 0;
BA_ "GenSigTimeoutTime_BSM" SG_ 2654486552 FD14_CBV_bit4_ActiveWakeupBit 0;
BA_ "GenSigTimeoutTime_BSM2" SG_ 2654486552 FD14_CBV_bit4_ActiveWakeupBit 0;
BA_ "GenSigTimeoutTime_CADM" SG_ 2654486552 FD14_CBV_bit4_ActiveWakeupBit 0;
BA_ "GenSigTimeoutTime_CVADAS" SG_ 2654486552 FD14_CBV_bit4_ActiveWakeupBit 0;
BA_ "GenSigTimeoutTime_ECM" SG_ 2654486552 FD14_CBV_bit4_ActiveWakeupBit 0;
BA_ "GenSigTimeoutTime_EPS" SG_ 2654486552 FD14_CBV_bit4_ActiveWakeupBit 0;
BA_ "GenSigTimeoutTime_ORC" SG_ 2654486552 FD14_CBV_bit4_ActiveWakeupBit 0;
BA_ "GenSigTimeoutTime_BSM" SG_ 2654486552 FD14_CBV_bit5 0;
BA_ "GenSigTimeoutTime_BSM2" SG_ 2654486552 FD14_CBV_bit5 0;
BA_ "GenSigTimeoutTime_CADM" SG_ 2654486552 FD14_CBV_bit5 0;
BA_ "GenSigTimeoutTime_CVADAS" SG_ 2654486552 FD14_CBV_bit5 0;
BA_ "GenSigTimeoutTime_ECM" SG_ 2654486552 FD14_CBV_bit5 0;
BA_ "GenSigTimeoutTime_EPS" SG_ 2654486552 FD14_CBV_bit5 0;
BA_ "GenSigTimeoutTime_ORC" SG_ 2654486552 FD14_CBV_bit5 0;
BA_ "GenSigTimeoutTime_BSM" SG_ 2654486552 FD14_CBV_bit6_PartialNtwInfBit 0;
BA_ "GenSigTimeoutTime_BSM2" SG_ 2654486552 FD14_CBV_bit6_PartialNtwInfBit 0;
BA_ "GenSigTimeoutTime_CADM" SG_ 2654486552 FD14_CBV_bit6_PartialNtwInfBit 0;
BA_ "GenSigTimeoutTime_CVADAS" SG_ 2654486552 FD14_CBV_bit6_PartialNtwInfBit 0;
BA_ "GenSigTimeoutTime_ECM" SG_ 2654486552 FD14_CBV_bit6_PartialNtwInfBit 0;
BA_ "GenSigTimeoutTime_EPS" SG_ 2654486552 FD14_CBV_bit6_PartialNtwInfBit 0;
BA_ "GenSigTimeoutTime_ORC" SG_ 2654486552 FD14_CBV_bit6_PartialNtwInfBit 0;
BA_ "GenSigTimeoutTime_BSM" SG_ 2654486552 FD14_CBV_bit7 0;
BA_ "GenSigTimeoutTime_BSM2" SG_ 2654486552 FD14_CBV_bit7 0;
BA_ "GenSigTimeoutTime_CADM" SG_ 2654486552 FD14_CBV_bit7 0;
BA_ "GenSigTimeoutTime_CVADAS" SG_ 2654486552 FD14_CBV_bit7 0;
BA_ "GenSigTimeoutTime_ECM" SG_ 2654486552 FD14_CBV_bit7 0;
BA_ "GenSigTimeoutTime_EPS" SG_ 2654486552 FD14_CBV_bit7 0;
BA_ "GenSigTimeoutTime_ORC" SG_ 2654486552 FD14_CBV_bit7 0;
BA_ "GenSigTimeoutTime_BSM" SG_ 2654486552 FD14_SourceNodeIdentifier 0;
BA_ "GenSigTimeoutTime_BSM2" SG_ 2654486552 FD14_SourceNodeIdentifier 0;
BA_ "GenSigTimeoutTime_CADM" SG_ 2654486552 FD14_SourceNodeIdentifier 0;
BA_ "GenSigTimeoutTime_CVADAS" SG_ 2654486552 FD14_SourceNodeIdentifier 0;
BA_ "GenSigTimeoutTime_ECM" SG_ 2654486552 FD14_SourceNodeIdentifier 0;
BA_ "GenSigTimeoutTime_EPS" SG_ 2654486552 FD14_SourceNodeIdentifier 0;
BA_ "GenSigTimeoutTime_ORC" SG_ 2654486552 FD14_SourceNodeIdentifier 0;
BA_ "GenSigTimeoutTime_BSM2" SG_ 611 FD14_CRC_ORC1 0;
BA_ "GenSigTimeoutTime_CVADAS" SG_ 611 FD14_CRC_ORC1 0;
BA_ "GenSigTimeoutTime_ECM" SG_ 611 FD14_CRC_ORC1 0;
BA_ "GenSigTimeoutTime_EPS" SG_ 611 FD14_CRC_ORC1 0;
BA_ "GenSigTimeoutTime_ORC" SG_ 611 FD14_CRC_ORC1 0;
BA_ "GenSigTimeoutTime_BSM2" SG_ 611 FD14_MessageCounter_ORC1 0;
BA_ "GenSigTimeoutTime_CVADAS" SG_ 611 FD14_MessageCounter_ORC1 0;
BA_ "GenSigTimeoutTime_ECM" SG_ 611 FD14_MessageCounter_ORC1 0;
BA_ "GenSigTimeoutTime_EPS" SG_ 611 FD14_MessageCounter_ORC1 0;
BA_ "GenSigTimeoutTime_ORC" SG_ 611 FD14_MessageCounter_ORC1 0;
BA_ "GenSigStartValue" SG_ 611 FD14_SBR1RowDriverSeatSts 3;
BA_ "GenSigSendType" SG_ 611 FD14_SBR1RowDriverSeatSts 3;
BA_ "GenSigTimeoutTime_BSM2" SG_ 611 FD14_SBR1RowDriverSeatSts 0;
BA_ "GenSigTimeoutTime_CVADAS" SG_ 611 FD14_SBR1RowDriverSeatSts 0;
BA_ "GenSigTimeoutTime_ECM" SG_ 611 FD14_SBR1RowDriverSeatSts 0;
BA_ "GenSigTimeoutTime_EPS" SG_ 611 FD14_SBR1RowDriverSeatSts 0;
BA_ "GenSigTimeoutTime_ORC" SG_ 611 FD14_SBR1RowDriverSeatSts 0;
BA_ "GenSigTimeoutTime_BSM2" SG_ 1954 FD14_CRC_ORC2 0;
BA_ "GenSigTimeoutTime_CADM" SG_ 1954 FD14_CRC_ORC2 0;
BA_ "GenSigTimeoutTime_CVADAS" SG_ 1954 FD14_CRC_ORC2 0;
BA_ "GenSigTimeoutTime_ECM" SG_ 1954 FD14_CRC_ORC2 0;
BA_ "GenSigTimeoutTime_EPS" SG_ 1954 FD14_CRC_ORC2 0;
BA_ "GenSigTimeoutTime_ORC" SG_ 1954 FD14_CRC_ORC2 0;
BA_ "GenSigTimeoutTime_BSM2" SG_ 1954 FD14_MessageCounter_ORC2 0;
BA_ "GenSigTimeoutTime_CADM" SG_ 1954 FD14_MessageCounter_ORC2 0;
BA_ "GenSigTimeoutTime_CVADAS" SG_ 1954 FD14_MessageCounter_ORC2 0;
BA_ "GenSigTimeoutTime_ECM" SG_ 1954 FD14_MessageCounter_ORC2 0;
BA_ "GenSigTimeoutTime_EPS" SG_ 1954 FD14_MessageCounter_ORC2 0;
BA_ "GenSigTimeoutTime_ORC" SG_ 1954 FD14_MessageCounter_ORC2 0;
BA_ "GenSigTimeoutTime_BSM2" SG_ 1954 FD14_ORCIdentification 0;
BA_ "GenSigTimeoutTime_CADM" SG_ 1954 FD14_ORCIdentification 0;
BA_ "GenSigTimeoutTime_CVADAS" SG_ 1954 FD14_ORCIdentification 0;
BA_ "GenSigTimeoutTime_ECM" SG_ 1954 FD14_ORCIdentification 0;
BA_ "GenSigTimeoutTime_EPS" SG_ 1954 FD14_ORCIdentification 0;
BA_ "GenSigTimeoutTime_ORC" SG_ 1954 FD14_ORCIdentification 0;
BA_ "GenSigTimeoutTime_BSM2" SG_ 274 FD14_CRC_ORC3 0;
BA_ "GenSigTimeoutTime_CVADAS" SG_ 274 FD14_CRC_ORC3 0;
BA_ "GenSigTimeoutTime_ECM" SG_ 274 FD14_CRC_ORC3 0;
BA_ "GenSigTimeoutTime_EPS" SG_ 274 FD14_CRC_ORC3 0;
BA_ "GenSigTimeoutTime_ORC" SG_ 274 FD14_CRC_ORC3 0;
BA_ "GenSigTimeoutTime_BSM2" SG_ 274 FD14_InternalError 0;
BA_ "GenSigTimeoutTime_CVADAS" SG_ 274 FD14_InternalError 0;
BA_ "GenSigTimeoutTime_ECM" SG_ 274 FD14_InternalError 0;
BA_ "GenSigTimeoutTime_EPS" SG_ 274 FD14_InternalError 0;
BA_ "GenSigTimeoutTime_ORC" SG_ 274 FD14_InternalError 0;
BA_ "GenSigStartValue" SG_ 274 FD14_LatAcceleration 4095;
BA_ "GenSigTimeoutTime_BSM2" SG_ 274 FD14_LatAcceleration 0;
BA_ "GenSigTimeoutTime_CVADAS" SG_ 274 FD14_LatAcceleration 0;
BA_ "GenSigTimeoutTime_ECM" SG_ 274 FD14_LatAcceleration 0;
BA_ "GenSigTimeoutTime_EPS" SG_ 274 FD14_LatAcceleration 0;
BA_ "GenSigTimeoutTime_ORC" SG_ 274 FD14_LatAcceleration 0;
BA_ "GenSigTimeoutTime_BSM2" SG_ 274 FD14_LatAccelerationFailSts 0;
BA_ "GenSigTimeoutTime_CVADAS" SG_ 274 FD14_LatAccelerationFailSts 0;
BA_ "GenSigTimeoutTime_ECM" SG_ 274 FD14_LatAccelerationFailSts 0;
BA_ "GenSigTimeoutTime_EPS" SG_ 274 FD14_LatAccelerationFailSts 0;
BA_ "GenSigTimeoutTime_ORC" SG_ 274 FD14_LatAccelerationFailSts 0;
BA_ "GenSigStartValue" SG_ 274 FD14_LongAcceleration 4095;
BA_ "GenSigTimeoutTime_BSM2" SG_ 274 FD14_LongAcceleration 0;
BA_ "GenSigTimeoutTime_CVADAS" SG_ 274 FD14_LongAcceleration 0;
BA_ "GenSigTimeoutTime_ECM" SG_ 274 FD14_LongAcceleration 0;
BA_ "GenSigTimeoutTime_EPS" SG_ 274 FD14_LongAcceleration 0;
BA_ "GenSigTimeoutTime_ORC" SG_ 274 FD14_LongAcceleration 0;
BA_ "GenSigTimeoutTime_BSM2" SG_ 274 FD14_LongAccelerationFailSts 0;
BA_ "GenSigTimeoutTime_CVADAS" SG_ 274 FD14_LongAccelerationFailSts 0;
BA_ "GenSigTimeoutTime_ECM" SG_ 274 FD14_LongAccelerationFailSts 0;
BA_ "GenSigTimeoutTime_EPS" SG_ 274 FD14_LongAccelerationFailSts 0;
BA_ "GenSigTimeoutTime_ORC" SG_ 274 FD14_LongAccelerationFailSts 0;
BA_ "GenSigTimeoutTime_BSM2" SG_ 274 FD14_MessageCounter_ORC3 0;
BA_ "GenSigTimeoutTime_CVADAS" SG_ 274 FD14_MessageCounter_ORC3 0;
BA_ "GenSigTimeoutTime_ECM" SG_ 274 FD14_MessageCounter_ORC3 0;
BA_ "GenSigTimeoutTime_EPS" SG_ 274 FD14_MessageCounter_ORC3 0;
BA_ "GenSigTimeoutTime_ORC" SG_ 274 FD14_MessageCounter_ORC3 0;
BA_ "GenSigStartValue" SG_ 274 FD14_YawRate 4095;
BA_ "GenSigTimeoutTime_BSM2" SG_ 274 FD14_YawRate 0;
BA_ "GenSigTimeoutTime_CVADAS" SG_ 274 FD14_YawRate 0;
BA_ "GenSigTimeoutTime_ECM" SG_ 274 FD14_YawRate 0;
BA_ "GenSigTimeoutTime_EPS" SG_ 274 FD14_YawRate 0;
BA_ "GenSigTimeoutTime_ORC" SG_ 274 FD14_YawRate 0;
BA_ "GenSigTimeoutTime_BSM" SG_ 274 FD14_YawRate_HR 0;
BA_ "GenSigTimeoutTime_BSM2" SG_ 274 FD14_YawRate_HR 0;
BA_ "GenSigTimeoutTime_CVADAS" SG_ 274 FD14_YawRate_HR 0;
BA_ "GenSigTimeoutTime_ECM" SG_ 274 FD14_YawRate_HR 0;
BA_ "GenSigTimeoutTime_EPS" SG_ 274 FD14_YawRate_HR 0;
BA_ "GenSigTimeoutTime_ORC" SG_ 274 FD14_YawRate_HR 0;
BA_ "GenSigTimeoutTime_BSM" SG_ 274 FD14_YawRate_HR_Sign 0;
BA_ "GenSigTimeoutTime_BSM2" SG_ 274 FD14_YawRate_HR_Sign 0;
BA_ "GenSigTimeoutTime_CVADAS" SG_ 274 FD14_YawRate_HR_Sign 0;
BA_ "GenSigTimeoutTime_ECM" SG_ 274 FD14_YawRate_HR_Sign 0;
BA_ "GenSigTimeoutTime_EPS" SG_ 274 FD14_YawRate_HR_Sign 0;
BA_ "GenSigTimeoutTime_ORC" SG_ 274 FD14_YawRate_HR_Sign 0;
BA_ "GenSigTimeoutTime_BSM2" SG_ 274 FD14_YawRateFailSts 0;
BA_ "GenSigTimeoutTime_CVADAS" SG_ 274 FD14_YawRateFailSts 0;
BA_ "GenSigTimeoutTime_ECM" SG_ 274 FD14_YawRateFailSts 0;
BA_ "GenSigTimeoutTime_EPS" SG_ 274 FD14_YawRateFailSts 0;
BA_ "GenSigTimeoutTime_ORC" SG_ 274 FD14_YawRateFailSts 0;
BA_ "GenSigTimeoutTime_BSM" SG_ 255 FD14_ACC_NCC_TrqEnblRq_Allowed 0;
BA_ "GenSigTimeoutTime_BSM2" SG_ 255 FD14_ACC_NCC_TrqEnblRq_Allowed 0;
BA_ "GenSigTimeoutTime_CVADAS" SG_ 255 FD14_ACC_NCC_TrqEnblRq_Allowed 0;
BA_ "GenSigTimeoutTime_ECM" SG_ 255 FD14_ACC_NCC_TrqEnblRq_Allowed 0;
BA_ "GenSigTimeoutTime_EPS" SG_ 255 FD14_ACC_NCC_TrqEnblRq_Allowed 0;
BA_ "GenSigTimeoutTime_ORC" SG_ 255 FD14_ACC_NCC_TrqEnblRq_Allowed 0;
BA_ "GenSigTimeoutTime_BSM2" SG_ 255 FD14_Accel_Pedal_Override 0;
BA_ "GenSigTimeoutTime_ECM" SG_ 255 FD14_Accel_Pedal_Override 0;
BA_ "GenSigTimeoutTime_EPS" SG_ 255 FD14_Accel_Pedal_Override 0;
BA_ "GenSigTimeoutTime_ORC" SG_ 255 FD14_Accel_Pedal_Override 0;
BA_ "GenSigTimeoutTime_BSM2" SG_ 255 FD14_CRC_PT_TORQUE_FD_1 0;
BA_ "GenSigTimeoutTime_CVADAS" SG_ 255 FD14_CRC_PT_TORQUE_FD_1 0;
BA_ "GenSigTimeoutTime_ECM" SG_ 255 FD14_CRC_PT_TORQUE_FD_1 0;
BA_ "GenSigTimeoutTime_EPS" SG_ 255 FD14_CRC_PT_TORQUE_FD_1 0;
BA_ "GenSigTimeoutTime_ORC" SG_ 255 FD14_CRC_PT_TORQUE_FD_1 0;
BA_ "GenSigTimeoutTime_BSM" SG_ 255 FD14_ESC_TrqEnblRq_Allowed 0;
BA_ "GenSigTimeoutTime_BSM2" SG_ 255 FD14_ESC_TrqEnblRq_Allowed 0;
BA_ "GenSigTimeoutTime_CADM" SG_ 255 FD14_ESC_TrqEnblRq_Allowed 0;
BA_ "GenSigTimeoutTime_CVADAS" SG_ 255 FD14_ESC_TrqEnblRq_Allowed 0;
BA_ "GenSigTimeoutTime_ECM" SG_ 255 FD14_ESC_TrqEnblRq_Allowed 0;
BA_ "GenSigTimeoutTime_EPS" SG_ 255 FD14_ESC_TrqEnblRq_Allowed 0;
BA_ "GenSigTimeoutTime_ORC" SG_ 255 FD14_ESC_TrqEnblRq_Allowed 0;
BA_ "GenSigTimeoutTime_BSM2" SG_ 255 FD14_MessageCounter_PT_TORQUE_FD 0;
BA_ "GenSigTimeoutTime_CVADAS" SG_ 255 FD14_MessageCounter_PT_TORQUE_FD 0;
BA_ "GenSigTimeoutTime_ECM" SG_ 255 FD14_MessageCounter_PT_TORQUE_FD 0;
BA_ "GenSigTimeoutTime_EPS" SG_ 255 FD14_MessageCounter_PT_TORQUE_FD 0;
BA_ "GenSigTimeoutTime_ORC" SG_ 255 FD14_MessageCounter_PT_TORQUE_FD 0;
BA_ "SystemSignalLongSymbol" SG_ 255 FD14_MessageCounter_PT_TORQUE_FD "FD14_MessageCounter_PT_TORQUE_FD_1";
BA_ "GenSigTimeoutTime_BSM2" SG_ 255 FD14_PPPA_TrqEnblRq_Allowed 0;
BA_ "GenSigTimeoutTime_CADM" SG_ 255 FD14_PPPA_TrqEnblRq_Allowed 0;
BA_ "GenSigTimeoutTime_ECM" SG_ 255 FD14_PPPA_TrqEnblRq_Allowed 0;
BA_ "GenSigTimeoutTime_EPS" SG_ 255 FD14_PPPA_TrqEnblRq_Allowed 0;
BA_ "GenSigTimeoutTime_ORC" SG_ 255 FD14_PPPA_TrqEnblRq_Allowed 0;
BA_ "GenSigTimeoutTime_BSM" SG_ 255 FD14_SSC_TrqEnblRq_Allowed 0;
BA_ "GenSigTimeoutTime_BSM2" SG_ 255 FD14_SSC_TrqEnblRq_Allowed 0;
BA_ "GenSigTimeoutTime_CADM" SG_ 255 FD14_SSC_TrqEnblRq_Allowed 0;
BA_ "GenSigTimeoutTime_CVADAS" SG_ 255 FD14_SSC_TrqEnblRq_Allowed 0;
BA_ "GenSigTimeoutTime_ECM" SG_ 255 FD14_SSC_TrqEnblRq_Allowed 0;
BA_ "GenSigTimeoutTime_EPS" SG_ 255 FD14_SSC_TrqEnblRq_Allowed 0;
BA_ "GenSigTimeoutTime_ORC" SG_ 255 FD14_SSC_TrqEnblRq_Allowed 0;
BA_ "GenSigTimeoutTime_BSM" SG_ 255 FD14_SumTorque_DrvReqMod 0;
BA_ "GenSigTimeoutTime_BSM2" SG_ 255 FD14_SumTorque_DrvReqMod 0;
BA_ "GenSigTimeoutTime_CADM" SG_ 255 FD14_SumTorque_DrvReqMod 0;
BA_ "GenSigTimeoutTime_CVADAS" SG_ 255 FD14_SumTorque_DrvReqMod 0;
BA_ "GenSigTimeoutTime_ECM" SG_ 255 FD14_SumTorque_DrvReqMod 0;
BA_ "GenSigTimeoutTime_EPS" SG_ 255 FD14_SumTorque_DrvReqMod 0;
BA_ "GenSigTimeoutTime_ORC" SG_ 255 FD14_SumTorque_DrvReqMod 0;
BA_ "GenSigTimeoutTime_BSM" SG_ 255 FD14_SumTorqueExp 0;
BA_ "GenSigTimeoutTime_BSM2" SG_ 255 FD14_SumTorqueExp 0;
BA_ "GenSigTimeoutTime_CADM" SG_ 255 FD14_SumTorqueExp 0;
BA_ "GenSigTimeoutTime_CVADAS" SG_ 255 FD14_SumTorqueExp 0;
BA_ "GenSigTimeoutTime_ECM" SG_ 255 FD14_SumTorqueExp 0;
BA_ "GenSigTimeoutTime_EPS" SG_ 255 FD14_SumTorqueExp 0;
BA_ "GenSigTimeoutTime_ORC" SG_ 255 FD14_SumTorqueExp 0;
BA_ "GenSigTimeoutTime_BSM" SG_ 255 FD14_SumTorqueMax 0;
BA_ "GenSigTimeoutTime_BSM2" SG_ 255 FD14_SumTorqueMax 0;
BA_ "GenSigTimeoutTime_CADM" SG_ 255 FD14_SumTorqueMax 0;
BA_ "GenSigTimeoutTime_CVADAS" SG_ 255 FD14_SumTorqueMax 0;
BA_ "GenSigTimeoutTime_ECM" SG_ 255 FD14_SumTorqueMax 0;
BA_ "GenSigTimeoutTime_EPS" SG_ 255 FD14_SumTorqueMax 0;
BA_ "GenSigTimeoutTime_ORC" SG_ 255 FD14_SumTorqueMax 0;
BA_ "GenSigTimeoutTime_BSM" SG_ 255 FD14_SumTorqueMin 0;
BA_ "GenSigTimeoutTime_BSM2" SG_ 255 FD14_SumTorqueMin 0;
BA_ "GenSigTimeoutTime_CADM" SG_ 255 FD14_SumTorqueMin 0;
BA_ "GenSigTimeoutTime_CVADAS" SG_ 255 FD14_SumTorqueMin 0;
BA_ "GenSigTimeoutTime_ECM" SG_ 255 FD14_SumTorqueMin 0;
BA_ "GenSigTimeoutTime_EPS" SG_ 255 FD14_SumTorqueMin 0;
BA_ "GenSigTimeoutTime_ORC" SG_ 255 FD14_SumTorqueMin 0;
BA_ "GenSigTimeoutTime_BSM" SG_ 255 FD14_SumTorqueSel_D_TTC 0;
BA_ "GenSigTimeoutTime_BSM2" SG_ 255 FD14_SumTorqueSel_D_TTC 0;
BA_ "GenSigTimeoutTime_CADM" SG_ 255 FD14_SumTorqueSel_D_TTC 0;
BA_ "GenSigTimeoutTime_CVADAS" SG_ 255 FD14_SumTorqueSel_D_TTC 0;
BA_ "GenSigTimeoutTime_ECM" SG_ 255 FD14_SumTorqueSel_D_TTC 0;
BA_ "GenSigTimeoutTime_EPS" SG_ 255 FD14_SumTorqueSel_D_TTC 0;
BA_ "GenSigTimeoutTime_ORC" SG_ 255 FD14_SumTorqueSel_D_TTC 0;
BA_ "GenSigTimeoutTime_BSM" SG_ 255 FD14_SumTorqueStatic 0;
BA_ "GenSigTimeoutTime_BSM2" SG_ 255 FD14_SumTorqueStatic 0;
BA_ "GenSigTimeoutTime_CADM" SG_ 255 FD14_SumTorqueStatic 0;
BA_ "GenSigTimeoutTime_CVADAS" SG_ 255 FD14_SumTorqueStatic 0;
BA_ "GenSigTimeoutTime_ECM" SG_ 255 FD14_SumTorqueStatic 0;
BA_ "GenSigTimeoutTime_EPS" SG_ 255 FD14_SumTorqueStatic 0;
BA_ "GenSigTimeoutTime_ORC" SG_ 255 FD14_SumTorqueStatic 0;
BA_ "GenSigStartValue" SG_ 255 FD14_Total_AxleTorque_Static 32767;
BA_ "GenSigTimeoutTime_BSM" SG_ 255 FD14_Total_AxleTorque_Static 0;
BA_ "GenSigTimeoutTime_BSM2" SG_ 255 FD14_Total_AxleTorque_Static 0;
BA_ "GenSigTimeoutTime_CVADAS" SG_ 255 FD14_Total_AxleTorque_Static 0;
BA_ "GenSigTimeoutTime_ECM" SG_ 255 FD14_Total_AxleTorque_Static 0;
BA_ "GenSigTimeoutTime_EPS" SG_ 255 FD14_Total_AxleTorque_Static 0;
BA_ "GenSigTimeoutTime_ORC" SG_ 255 FD14_Total_AxleTorque_Static 0;
BA_ "GenSigTimeoutTime_BSM2" SG_ 1472 FD14_CRC_TRSCM1 0;
BA_ "GenSigTimeoutTime_CADM" SG_ 1472 FD14_CRC_TRSCM1 0;
BA_ "GenSigTimeoutTime_CVADAS" SG_ 1472 FD14_CRC_TRSCM1 0;
BA_ "GenSigTimeoutTime_ORC" SG_ 1472 FD14_CRC_TRSCM1 0;
BA_ "GenSigTimeoutTime_BSM2" SG_ 1472 FD14_MessageCounter_TRSCM1 0;
BA_ "GenSigTimeoutTime_CADM" SG_ 1472 FD14_MessageCounter_TRSCM1 0;
BA_ "GenSigTimeoutTime_CVADAS" SG_ 1472 FD14_MessageCounter_TRSCM1 0;
BA_ "GenSigTimeoutTime_ORC" SG_ 1472 FD14_MessageCounter_TRSCM1 0;
BA_ "GenSigSendType" SG_ 1472 FD14_THA_EPB_Req 4;
BA_ "GenSigTimeoutTime_BSM2" SG_ 1472 FD14_THA_EPB_Req 0;
BA_ "GenSigTimeoutTime_CADM" SG_ 1472 FD14_THA_EPB_Req 0;
BA_ "GenSigTimeoutTime_CVADAS" SG_ 1472 FD14_THA_EPB_Req 0;
BA_ "GenSigTimeoutTime_ECM" SG_ 1472 FD14_THA_EPB_Req 0;
BA_ "GenSigTimeoutTime_EPS" SG_ 1472 FD14_THA_EPB_Req 0;
BA_ "GenSigTimeoutTime_ORC" SG_ 1472 FD14_THA_EPB_Req 0;
BA_ "GenSigSendType" SG_ 1472 FD14_THA_Speed_Limit 4;
BA_ "GenSigTimeoutTime_BSM2" SG_ 1472 FD14_THA_Speed_Limit 0;
BA_ "GenSigTimeoutTime_CADM" SG_ 1472 FD14_THA_Speed_Limit 0;
BA_ "GenSigTimeoutTime_CVADAS" SG_ 1472 FD14_THA_Speed_Limit 0;
BA_ "GenSigTimeoutTime_ORC" SG_ 1472 FD14_THA_Speed_Limit 0;
BA_ "GenSigSendType" SG_ 1472 FD14_THA_SpeedLimit_Req 4;
BA_ "GenSigTimeoutTime_BSM2" SG_ 1472 FD14_THA_SpeedLimit_Req 0;
BA_ "GenSigTimeoutTime_CADM" SG_ 1472 FD14_THA_SpeedLimit_Req 0;
BA_ "GenSigTimeoutTime_CVADAS" SG_ 1472 FD14_THA_SpeedLimit_Req 0;
BA_ "GenSigTimeoutTime_EPS" SG_ 1472 FD14_THA_SpeedLimit_Req 0;
BA_ "GenSigTimeoutTime_ORC" SG_ 1472 FD14_THA_SpeedLimit_Req 0;
BA_ "GenSigSendType" SG_ 1472 FD14_THA_STAT 4;
BA_ "GenSigTimeoutTime_BSM2" SG_ 1472 FD14_THA_STAT 0;
BA_ "GenSigTimeoutTime_CADM" SG_ 1472 FD14_THA_STAT 0;
BA_ "GenSigTimeoutTime_CVADAS" SG_ 1472 FD14_THA_STAT 0;
BA_ "GenSigTimeoutTime_ORC" SG_ 1472 FD14_THA_STAT 0;
BA_ "GenSigStartValue" SG_ 1472 FD14_THA_SteeringDamping 100;
BA_ "GenSigSendType" SG_ 1472 FD14_THA_SteeringDamping 3;
BA_ "GenSigTimeoutTime_BSM" SG_ 1472 FD14_THA_SteeringDamping 0;
BA_ "GenSigTimeoutTime_BSM2" SG_ 1472 FD14_THA_SteeringDamping 0;
BA_ "GenSigTimeoutTime_CADM" SG_ 1472 FD14_THA_SteeringDamping 0;
BA_ "GenSigTimeoutTime_CVADAS" SG_ 1472 FD14_THA_SteeringDamping 0;
BA_ "GenSigTimeoutTime_ECM" SG_ 1472 FD14_THA_SteeringDamping 0;
BA_ "GenSigTimeoutTime_ORC" SG_ 1472 FD14_THA_SteeringDamping 0;
BA_ "GenSigStartValue" SG_ 1472 FD14_THA_SteeringTorqueInfo 1024;
BA_ "GenSigSendType" SG_ 1472 FD14_THA_SteeringTorqueInfo 3;
BA_ "GenSigTimeoutTime_BSM" SG_ 1472 FD14_THA_SteeringTorqueInfo 0;
BA_ "GenSigTimeoutTime_BSM2" SG_ 1472 FD14_THA_SteeringTorqueInfo 0;
BA_ "GenSigTimeoutTime_CADM" SG_ 1472 FD14_THA_SteeringTorqueInfo 0;
BA_ "GenSigTimeoutTime_CVADAS" SG_ 1472 FD14_THA_SteeringTorqueInfo 0;
BA_ "GenSigTimeoutTime_ECM" SG_ 1472 FD14_THA_SteeringTorqueInfo 0;
BA_ "GenSigTimeoutTime_ORC" SG_ 1472 FD14_THA_SteeringTorqueInfo 0;
BA_ "GenSigSendType" SG_ 1472 FD14_THA_SteeringTorqueReq 4;
BA_ "GenSigTimeoutTime_BSM" SG_ 1472 FD14_THA_SteeringTorqueReq 0;
BA_ "GenSigTimeoutTime_BSM2" SG_ 1472 FD14_THA_SteeringTorqueReq 0;
BA_ "GenSigTimeoutTime_CADM" SG_ 1472 FD14_THA_SteeringTorqueReq 0;
BA_ "GenSigTimeoutTime_CVADAS" SG_ 1472 FD14_THA_SteeringTorqueReq 0;
BA_ "GenSigTimeoutTime_ECM" SG_ 1472 FD14_THA_SteeringTorqueReq 0;
BA_ "GenSigTimeoutTime_ORC" SG_ 1472 FD14_THA_SteeringTorqueReq 0;
BA_ "GenSigSendType" SG_ 1472 FD14_TRSC_SpeedLimit_Req 3;
BA_ "GenSigTimeoutTime_BSM2" SG_ 1472 FD14_TRSC_SpeedLimit_Req 0;
BA_ "GenSigTimeoutTime_CADM" SG_ 1472 FD14_TRSC_SpeedLimit_Req 0;
BA_ "GenSigTimeoutTime_CVADAS" SG_ 1472 FD14_TRSC_SpeedLimit_Req 0;
BA_ "GenSigTimeoutTime_EPS" SG_ 1472 FD14_TRSC_SpeedLimit_Req 0;
BA_ "GenSigTimeoutTime_ORC" SG_ 1472 FD14_TRSC_SpeedLimit_Req 0;
BA_ "GenSigStartValue" SG_ 1472 FD14_TRSC_STAT 1;
BA_ "GenSigSendType" SG_ 1472 FD14_TRSC_STAT 3;
BA_ "GenSigTimeoutTime_BSM2" SG_ 1472 FD14_TRSC_STAT 0;
BA_ "GenSigTimeoutTime_CADM" SG_ 1472 FD14_TRSC_STAT 0;
BA_ "GenSigTimeoutTime_CVADAS" SG_ 1472 FD14_TRSC_STAT 0;
BA_ "GenSigTimeoutTime_EPS" SG_ 1472 FD14_TRSC_STAT 0;
BA_ "GenSigTimeoutTime_ORC" SG_ 1472 FD14_TRSC_STAT 0;
BA_ "GenSigStartValue" SG_ 1472 FD14_TRSC_SteeringDamping 100;
BA_ "GenSigTimeoutTime_BSM" SG_ 1472 FD14_TRSC_SteeringDamping 0;
BA_ "GenSigTimeoutTime_BSM2" SG_ 1472 FD14_TRSC_SteeringDamping 0;
BA_ "GenSigTimeoutTime_CADM" SG_ 1472 FD14_TRSC_SteeringDamping 0;
BA_ "GenSigTimeoutTime_CVADAS" SG_ 1472 FD14_TRSC_SteeringDamping 0;
BA_ "GenSigTimeoutTime_ECM" SG_ 1472 FD14_TRSC_SteeringDamping 0;
BA_ "GenSigTimeoutTime_ORC" SG_ 1472 FD14_TRSC_SteeringDamping 0;
BA_ "GenSigStartValue" SG_ 1472 FD14_TRSC_SteeringTorqueInfo 1024;
BA_ "GenSigSendType" SG_ 1472 FD14_TRSC_SteeringTorqueInfo 3;
BA_ "GenSigTimeoutTime_BSM" SG_ 1472 FD14_TRSC_SteeringTorqueInfo 0;
BA_ "GenSigTimeoutTime_BSM2" SG_ 1472 FD14_TRSC_SteeringTorqueInfo 0;
BA_ "GenSigTimeoutTime_CADM" SG_ 1472 FD14_TRSC_SteeringTorqueInfo 0;
BA_ "GenSigTimeoutTime_CVADAS" SG_ 1472 FD14_TRSC_SteeringTorqueInfo 0;
BA_ "GenSigTimeoutTime_ECM" SG_ 1472 FD14_TRSC_SteeringTorqueInfo 0;
BA_ "GenSigTimeoutTime_ORC" SG_ 1472 FD14_TRSC_SteeringTorqueInfo 0;
BA_ "GenSigSendType" SG_ 1472 FD14_TRSC_SteeringTorqueReq 3;
BA_ "GenSigTimeoutTime_BSM" SG_ 1472 FD14_TRSC_SteeringTorqueReq 0;
BA_ "GenSigTimeoutTime_BSM2" SG_ 1472 FD14_TRSC_SteeringTorqueReq 0;
BA_ "GenSigTimeoutTime_CADM" SG_ 1472 FD14_TRSC_SteeringTorqueReq 0;
BA_ "GenSigTimeoutTime_CVADAS" SG_ 1472 FD14_TRSC_SteeringTorqueReq 0;
BA_ "GenSigTimeoutTime_ECM" SG_ 1472 FD14_TRSC_SteeringTorqueReq 0;
BA_ "GenSigTimeoutTime_ORC" SG_ 1472 FD14_TRSC_SteeringTorqueReq 0;
BA_ "GenSigStartValue" SG_ 1472 FD14_TRSC_VehicleStop_Req 3;
BA_ "GenSigSendType" SG_ 1472 FD14_TRSC_VehicleStop_Req 3;
BA_ "GenSigTimeoutTime_BSM2" SG_ 1472 FD14_TRSC_VehicleStop_Req 0;
BA_ "GenSigTimeoutTime_CADM" SG_ 1472 FD14_TRSC_VehicleStop_Req 0;
BA_ "GenSigTimeoutTime_CVADAS" SG_ 1472 FD14_TRSC_VehicleStop_Req 0;
BA_ "GenSigTimeoutTime_ECM" SG_ 1472 FD14_TRSC_VehicleStop_Req 0;
BA_ "GenSigTimeoutTime_EPS" SG_ 1472 FD14_TRSC_VehicleStop_Req 0;
BA_ "GenSigTimeoutTime_ORC" SG_ 1472 FD14_TRSC_VehicleStop_Req 0;
VAL_ 609 FD14_ASRActive 0 "Not_active" 1 "Active" ;
VAL_ 609 FD14_BSM_LnchAbrtSts 0 "NOT" 1 "AwE" 2 "AwA" 3 "SNA" ;
VAL_ 609 FD14_BSM_LnchCtrl_SftBtn_SelectS 0 "False" 1 "True" ;
VAL_ 609 FD14_BSM_LnchMode 0 "LAUNCH_OFF" 1 "LAUNCH_ON" 2 "LAUNCH_ACT" 3 "CNC" 4 "LAUNCH_ACT_RPM_PHASE" 7 "SNA" ;
VAL_ 609 FD14_EPBSts 0 "Released" 1 "Applied" 2 "DynamicBrkESC" 3 "DynamicBrkEPB" 4 "Emergency_Braking" 5 "Applying" 6 "Maintenance_Mode" 7 "Assembly_Check" 8 "Inspection_Mode" 9 "Re_Clamping" 10 "Adjuste_Mode" 11 "Releasing" 12 "Fault_EPB_Released" 13 "Fault_EPB_Applied" 14 "Fault_Present" 15 "SNA" ;
VAL_ 609 FD14_ESC_OFF_Hrd_Sft_Button_sts 0 "STREET" 1 "SPORT" 2 "TRACK" 3 "OFF" 4 "SNOW" 5 "OFFROAD" 7 "SNA" ;
VAL_ 609 FD14_MSRActive 0 "Not_Active" 1 "Active" ;
VAL_ 609 FD14_TravelDistance 255 "SNA" ;
VAL_ 1155 FD14_ABSFailSts 0 "Fail_Not_Present" 1 "Fail_Present" ;
VAL_ 1155 FD14_ACCEngaged 0 "Not_Engaged" 1 "Engaged" ;
VAL_ 1155 FD14_BSM_THA_Brk_Resp 0 "Off" 1 "Active" 2 "Brakes Overheated" 3 "SNA" ;
VAL_ 1155 FD14_BSMSysSts 0 "Normal mode" 1 "Diagnosis mode" 2 "Alternative mode" 3 "SNA" ;
VAL_ 1155 FD14_CMMIntervention 0 "No_intervention" 1 "Intervention" ;
VAL_ 1155 FD14_EBDFailSts 0 "Fail_Not_Present" 1 "Fail_Present" ;
VAL_ 1155 FD14_ERMActive 0 "Not_Active" 1 "Active" ;
VAL_ 1155 FD14_ESC_TRSC_Brk_Resp 0 "OFF" 1 "Active" 2 "Brakes_Over_Heated" 3 "SNA" ;
VAL_ 1155 FD14_ESCFailSts 0 "Fail_Not_Present" 1 "Fail_Present" ;
VAL_ 1155 FD14_Function2Sts 0 "Not_Active" 1 "Active" ;
VAL_ 1155 FD14_FunctionFailSts 0 "Fail_Not_Present" 1 "Fail_Present" ;
VAL_ 1155 FD14_FunctionIntervention 0 "No_intervention" 1 "Intervention_blinking_lamp" ;
VAL_ 1155 FD14_FunctionSts 0 "Not_Active" 1 "Active" ;
VAL_ 1155 FD14_RollsModeAct 0 "Not_active" 1 "Active" ;
VAL_ 1155 FD14_TSCActive 0 "Not_Active" 1 "Active" ;
VAL_ 205 FD14_DriverReq_AxleTrq_Enabled_B 0 "No_Req" 1 "ACC_NCC" 2 "SSC" 3 "PPPA" 4 "RRCC" 15 "SNA" ;
VAL_ 205 FD14_DriverRequested_AxleTrq_BSM 65535 "SNA" ;
VAL_ 205 FD14_TotalAxle_Max_Rq_BSM 0 "Not_Active" 1 "Active" ;
VAL_ 205 FD14_TotalAxle_Min_Rq_BSM 0 "Not_Active" 1 "Active" ;
VAL_ 205 FD14_TotalAxle_Rq_BSM 65535 "SNA" ;
VAL_ 514 FD14_AEB_Type_Brk 0 "NONE" 1 "ACC" 2 "CMS" 3 "CMS_XTD" 4 "ABA" 5 "LSCM" 6 "PEB" 7 "ICA_L" 8 "ICA_R" 9 "HAS_MRM" 10 "RRCC" 15 "SNA" ;
VAL_ 514 FD14_Brake_OpStat_Prim 0 "Inactive" 1 "FullService" 2 "FailOperational" 3 "FailDegraded" 4 "Emergency" 5 "No_Function" ;
VAL_ 514 FD14_BrakePdlPosn 255 "SNA" ;
VAL_ 514 FD14_BrkPdl_Flt 0 "NOT FAULTED" 1 "FAULTED" ;
VAL_ 514 FD14_BrkPdl_Stat 0 "UPSTOP" 1 "PSD" 2 "NDEF2" 3 "SNA" ;
VAL_ 514 FD14_BSM_OpStat 0 "Inactive" 1 "FullService" 2 "FailOperational" 3 "FailDegraded" 4 "Emergency" 5 "No_Function" ;
VAL_ 514 FD14_PAM_Brk_Rq_RspSts 0 "Not_Active" 1 "Active" 2 "Faulted_Condition" 3 "SNA" ;
VAL_ 257 FD14_ABSActive_B2 0 "Not_active" 1 "Active" ;
VAL_ 257 FD14_Brk_Stat_B2 0 "IDLE" 1 "BRAKING" 2 "NDEF2" 3 "SNA" ;
VAL_ 257 FD14_Ft_RrAxleCoupling_TrqRq_B2 255 "SNA" ;
VAL_ 257 FD14_Ft_RrTrqCoupling_ModeRq_B2 0 "FREE" 1 "HOLD" 2 "OPEN" 3 "SNA" ;
VAL_ 257 FD14_Inlet_Pressure_Pos 0 "False" 1 "True" 3 "SNA" ;
VAL_ 257 FD14_LHF_FastPulseCounter_B2 255 "SNA" ;
VAL_ 257 FD14_LHF_Spin_B2 0 "Stand_Still" 1 "Forward" 2 "Backward" 3 "SNA" ;
VAL_ 257 FD14_LHF_WheelSensorFailSts_B2 0 "Fail_Not_Present" 1 "Fail_Present" ;
VAL_ 257 FD14_LHFWheelSpeed_B2 8191 "SNA" ;
VAL_ 257 FD14_R_DIFF_TRQ_RQ_B2 511 "SNA" ;
VAL_ 257 FD14_Rear_Diff_BSM_RQ_B2 0 "FREE" 1 "HOLD" 2 "OPEN" 3 "SNA" ;
VAL_ 257 FD14_RHF_FastPulseCounter_B2 255 "SNA" ;
VAL_ 257 FD14_RHF_Spin_B2 0 "Stand_Still" 1 "Forward" 2 "Backward" 3 "SNA" ;
VAL_ 257 FD14_RHF_WheelSensorFailSts_B2 0 "Fail_Not_Present" 1 "Fail_Present" ;
VAL_ 257 FD14_RHFWheelSpeed_B2 8191 "SNA" ;
VAL_ 257 FD14_VehicleSpeedVSOSig_B2 8191 "SNA" ;
VAL_ 524 FD14_AEB_Type_Brk_B2 0 "NONE" 1 "ACC" 2 "CMS" 3 "CMS_XTD" 4 "ABA" 5 "LSCM" 6 "PEB" 7 "ICA_L" 8 "ICA_R" 9 "HAS_MRM" 15 "SNA" ;
VAL_ 524 FD14_Brake_OpStat_Sec 0 "Inactive" 1 "FullService" 2 "FailOperational" 3 "FailDegraded" 4 "Emergency" 5 "No_Function" ;
VAL_ 524 FD14_BrkTrq_B2 32767 "SNA" ;
VAL_ 524 FD14_BSM2_OpStat 0 "Inactive" 1 "FullService" 2 "FailOperational" 3 "FailDegraded" 4 "Emergency" 5 "No_Function" ;
VAL_ 524 FD14_VehicleStandStillSts_B2 0 "True" 1 "False" 3 "SNA" ;
VAL_ 1156 FD14_ABSFailSts_B2 0 "Fail_Not_Present" 1 "Fail_Present" ;
VAL_ 1156 FD14_RollsModeAct_B2 0 "No Fault" 1 "Fault" ;
VAL_ 275 FD14_ManoeuvrePhase 0 "Backward" 1 "Forward" ;
VAL_ 275 FD14_ParkingGearShiftReq 0 "Idle" 1 "P" 2 "R" 3 "N" 4 "D" 5 "Not_Used" 6 "Not_Used" 7 "SNA" ;
VAL_ 275 FD14_PPPA_Interface_BSM 0 "Idle" 1 "CVPAM_Request" 2 "Faulted" 3 "SNA" ;
VAL_ 275 FD14_PPPA_MaxSpeed 255 "SNA" ;
VAL_ 275 FD14_PPPA_StandstillRqst 0 "Not_Active" 1 "Active" ;
VAL_ 275 FD14_PPPA_TargetDistance 1023 "SNA" ;
VAL_ 275 FD14_RR_PAM_Brk_RqSts 0 "Off" 1 "On" ;
VAL_ 275 FD14_RR_PAM_Dist 1023 "SNA" ;
VAL_ 275 FD14_SPM_Lat_Ctrl_RequestSts 0 "IDLE" 1 "Faulted" 2 "SPM_Request" ;
VAL_ 950 FD14_ParkingManeuverActive 0 "Idle" 1 "Enabled_Seeking" 2 "Engaged_Semi" 3 "Engaged_Full" 4 "Not_Used" 5 "Not_Used" 6 "Not_Used" 7 "SNA" ;
VAL_ 1054 FD14_ThermalManagementActive_W 0 "Not_active" 1 "Active" ;
VAL_ 262 FD14_ECM_LHOM_W 0 "Not_In_Limp_Home" 1 "In_Limp_Home" ;
VAL_ 262 FD14_EngineSpeed_W 16383 "SNA" ;
VAL_ 262 FD14_EngineSts_W 0 "Engine_Off" 1 "Engine_Cranking" 2 "Engine_On" 3 "SNA" ;
VAL_ 262 FD14_ESS_ENG_ST_W 1 "ENS Stopped / ENS_STOPPED" 2 "ENS Request Start / ENS_RQ_ST" 3 "ENS Running / ENS_RUN" 4 "ENS Stop Pending / ENS_STOP_PEND" 5 "ENS Start protection / ENS_ST_PRTCT" 6 "ENS Start inhibit / ENS_ST_INH" 7 "ENS disabled / ENS_DSBL" 8 "ENS_IHB_LATCH" 9 "ENS Starting / ENS_Starting" 15 "SNA" ;
VAL_ 262 FD14_GasPedalPosition_W 255 "SNA" ;
VAL_ 262 FD14_GasPedalPositionFailSts_W 0 "Fail_not_present" 1 "Fail_present" ;
VAL_ 262 FD14_LV12PwrFreeRq_W 0 "Level 1 or 2 Power free Mode NOT active" 1 "Level 1 or 2 Power free Mode Active" ;
VAL_ 262 FD14_PowertrainPrplsnActv 0 "Off" 1 "Active" ;
VAL_ 518 FD14_PdlPosActual 255 "SNA" ;
VAL_ 518 FD14_RPMOverRev_W 0 "FALSE" 1 "TRUE" ;
VAL_ 1448 FD14_ECM_THA_Resp 0 "Off" 1 "Active" 3 "SNA" ;
VAL_ 1448 FD14_ECM_TRSC_Resp 0 "OFF" 1 "Active" 3 "SNA" ;
VAL_ 264 FD14_ElectricSteeringFailSts 0 "Fail_Not_Present" 1 "Fail_Present" ;
VAL_ 264 FD14_EngineFanRequestActivation 0 "False" 1 "True" ;
VAL_ 264 FD14_EPS_ADAS_IMC_Fault 0 "No_Fault" 1 "Fault" ;
VAL_ 264 FD14_EPS_AsstStat 0 "AST_ACT" 1 "AST_OFF" 2 "AST_RT" 7 "SNA" ;
VAL_ 264 FD14_EPS_Curr 255 "SNA" ;
VAL_ 264 FD14_EPS_Hands_On_Sts 0 "Not_Detected" 1 "Detected" ;
VAL_ 264 FD14_EPS_HandsOnRecognition 0 "False" 1 "True" ;
VAL_ 264 FD14_EPSMotorTorque 2047 "SNA" ;
VAL_ 264 FD14_ESA_LAT_CTRL_ResponseSts 0 "IDLE" 1 "Permanently_Not_Avail" 2 "Temporarily_Not_Avail" 3 "ESA_Open" 4 "ESA_Open_Backup" 5 "INIT" 6 "Damped_Exit" 7 "SNA" ;
VAL_ 264 FD14_HAS_LAT_CTRL_ResponseSts 0 "IDLE" 1 "Permanent_Not_Avail" 2 "Temporarily_Not_Avail" 3 "HAS_Open" 4 "HAS_Open_Backup" 5 "INIT" 6 "Damped_Exit" 7 "Faulted" ;
VAL_ 264 FD14_LKA_LAT_CTRL_ResponseSts 0 "IDLE" 1 "Permanent_Not_Avail" 2 "Temporarily_Not_Avail" 3 "LKA_Open" ;
VAL_ 264 FD14_LwsAngle 65535 "SNA" ;
VAL_ 264 FD14_LwsAngleType 0 "Absolute" 1 "Relative" 3 "SNA" ;
VAL_ 264 FD14_LwsCalibration 0 "Not_calibrated" 1 "Calibrated" ;
VAL_ 264 FD14_LwsSpeed 4095 "SNA" ;
VAL_ 264 FD14_SPM_Lat_Ctrl_ResponseSts 0 "IDLE" 1 "Permanent_Not_Avail" 2 "Temporarily_Not_Avail" 3 "SPM_Open" ;
VAL_ 264 FD14_Steering_Column_Torque 2047 "SNA" ;
VAL_ 264 FD14_Steering_OpStat_Prim 0 "Inactive" 1 "FullService" 2 "FailOperational" 3 "FailDegraded" 4 "Emergency" 5 "No_Function" ;
VAL_ 264 FD14_SteeringVibration_Fault 0 "NO_FAULT" 1 "FAULTED" ;
VAL_ 264 FD14_SteeringVibration_Status 0 "Inactive" 1 "Active" ;
VAL_ 1056 FD14_EPS_MODE_STAT 0 "MODE_1" 1 "MODE_2" 2 "MODE_3" 3 "LAST" 7 "SNA" ;
VAL_ 1056 FD14_EPS_SteeringTouchStat 0 "False" 1 "True" ;
VAL_ 1056 FD14_EPS_SteeringTouq_Resp 0 "OFF" 1 "Active" 3 "SNA" ;
VAL_ 1056 FD14_EPS_THA_DriverTorqueOverrid 0 "False" 1 "True" 3 "SNA" ;
VAL_ 1056 FD14_EPS_THA_SteeringTorqueResp 0 "Temp_NA" 1 "Perm_NA" 2 "TOI_Available" 3 "TOI_Unavailable" 7 "SNA" ;
VAL_ 1056 FD14_EPS_Warn_Disp_Rq 0 "EPS function active OK" 1 "Warning - Service power steering ERR" 2 "Warning - Power steering-over temp ERR2" 3 "Service Required - High Priority SERV_HI" 7 "SNA" ;
VAL_ 1056 FD14_THA_SteeringTouchStat 0 "Hands Off" 1 "Hands On" 3 "SNA" ;
VAL_ 1626 FD14_IMPACT_B 0 "Do_Not_Actuate" 1 "Actuate" ;
VAL_ 1626 FD14_IMPACT_C 0 "Do_Not_Actuate" 1 "Actuate" ;
VAL_ 1626 FD14_IMPACT_F 0 "Do_Not_Actuate" 1 "Actuate" ;
VAL_ 1626 FD14_IMPACT_I 0 "Do_Not_Actuate" 1 "Actuate" ;
VAL_ 1626 FD14_IMPACT_K 0 "Do_Not_Actuate" 1 "Actuate" ;
VAL_ 1626 FD14_IMPACT_M 0 "Do_Not_Actuate" 1 "Actuate" ;
VAL_ 1626 FD14_IMPACTCommand 0 "Do_Not_Actuate" 1 "Actuate" ;
VAL_ 1626 FD14_IMPACTConfirm 0 "Actuate" 1 "Do_Not_Actuate" ;
VAL_ 1626 FD14_IMPACTFailSts 0 "Fail_Not_Present" 1 "Fail_Present" ;
VAL_ 1626 FD14_IMPACTThreshold 0 "Threshold_Not_Met" 1 "Threshold_Met" ;
VAL_ 2654486534 FD14_CBV_bit0_RepeatMessageReque 0 "Repeat_Message_State_not_requested" 1 "Repeat_Message_State_requested" ;
VAL_ 2654486534 FD14_CBV_bit3_NMCoordinatorBit 0 "Start_of_synchronized_shutdown_is_not_requested_by_main_coordinator" 1 "Start_of_synchronized_shutdown_is_requested_by_main_coordinator" ;
VAL_ 2654486534 FD14_CBV_bit4_ActiveWakeupBit 0 "PassiveWakeup" 1 "ActiveWakeup" ;
VAL_ 2654486534 FD14_CBV_bit6_PartialNtwInfBit 0 "NM_PDU_contains_no_Partial_Network_request_information" 1 "NM_PDU_contains_Partial_Network_request_information" ;
VAL_ 2654486676 FD14_CBV_bit0_RepeatMessage_0000 0 "Repeat_Message_State_not_requested" 1 "Repeat_Message_State_requested" ;
VAL_ 2654486676 FD14_CBV_bit3_NMCoordinatorBit 0 "Start_of_synchronized_shutdown_is_not_requested_by_main_coordinator" 1 "Start_of_synchronized_shutdown_is_requested_by_main_coordinator" ;
VAL_ 2654486676 FD14_CBV_bit4_ActiveWakeupBit 0 "PassiveWakeup" 1 "ActiveWakeup" ;
VAL_ 2654486676 FD14_CBV_bit6_PartialNtwInfBit 0 "NM_PDU_contains_no_Partial_Network_request_information" 1 "NM_PDU_contains_Partial_Network_request_information" ;
VAL_ 2654486669 FD14_CBV_bit0_RepeatMessage_0001 0 "Repeat_Message_State_not_requested" 1 "Repeat_Message_State_requested" ;
VAL_ 2654486669 FD14_CBV_bit3_NMCoordinatorBit 0 "Start_of_synchronized_shutdown_is_not_requested_by_main_coordinator" 1 "Start_of_synchronized_shutdown_is_requested_by_main_coordinator" ;
VAL_ 2654486669 FD14_CBV_bit4_ActiveWakeupBit 0 "PassiveWakeup" 1 "ActiveWakeup" ;
VAL_ 2654486669 FD14_CBV_bit6_PartialNtwInfBit 0 "NM_PDU_contains_no_Partial_Network_request_information" 1 "NM_PDU_contains_Partial_Network_request_information" ;
VAL_ 2654486529 FD14_CBV_bit0_RepeatMessage_0002 0 "Repeat_Message_State_not_requested" 1 "Repeat_Message_State_requested" ;
VAL_ 2654486529 FD14_CBV_bit3_NMCoordinatorBit 0 "Start_of_synchronized_shutdown_is_not_requested_by_main_coordinator" 1 "Start_of_synchronized_shutdown_is_requested_by_main_coordinator" ;
VAL_ 2654486529 FD14_CBV_bit4_ActiveWakeupBit 0 "PassiveWakeup" 1 "ActiveWakeup" ;
VAL_ 2654486529 FD14_CBV_bit6_PartialNtwInfBit 0 "NM_PDU_contains_no_Partial_Network_request_information" 1 "NM_PDU_contains_Partial_Network_request_information" ;
VAL_ 2654486530 FD14_CBV_bit0_RepeatMessage_0003 0 "Repeat_Message_State_not_requested" 1 "Repeat_Message_State_requested" ;
VAL_ 2654486530 FD14_CBV_bit3_NMCoordinatorBit 0 "Start_of_synchronized_shutdown_is_not_requested_by_main_coordinator" 1 "Start_of_synchronized_shutdown_is_requested_by_main_coordinator" ;
VAL_ 2654486530 FD14_CBV_bit4_ActiveWakeupBit 0 "PassiveWakeup" 1 "ActiveWakeup" ;
VAL_ 2654486530 FD14_CBV_bit6_PartialNtwInfBit 0 "NM_PDU_contains_no_Partial_Network_request_information" 1 "NM_PDU_contains_Partial_Network_request_information" ;
VAL_ 2654486554 FD14_CBV_bit0_RepeatMessage_0004 0 "Repeat Message State not requested" 1 "Repeat Message State requested" ;
VAL_ 2654486554 FD14_CBV_bit3_NMCoordinatorBit 0 "Start of synchronized shutdown is not requested by main coordinator" 1 "Start of synchronized shutdown is requested by main coordinator" ;
VAL_ 2654486554 FD14_CBV_bit4_ActiveWakeupBit 0 "PassiveWakeup" 1 "ActiveWakeup" ;
VAL_ 2654486554 FD14_CBV_bit6_PartialNtwInfBit 0 "NM PDU contains no Partial Network request information" 1 "NM PDU contains Partial Network request information" ;
VAL_ 2654486552 FD14_CBV_bit0_RepeatMessage_0005 0 "Repeat_Message_State_not_requested" 1 "Repeat_Message_State_requested" ;
VAL_ 2654486552 FD14_CBV_bit3_NMCoordinatorBit 0 "Start_of_synchronized_shutdown_is_not_requested_by_main_coordinator" 1 "Start_of_synchronized_shutdown_is_requested_by_main_coordinator" ;
VAL_ 2654486552 FD14_CBV_bit4_ActiveWakeupBit 0 "PassiveWakeup" 1 "ActiveWakeup" ;
VAL_ 2654486552 FD14_CBV_bit6_PartialNtwInfBit 0 "NM_PDU_contains_no_Partial_Network_request_information" 1 "NM_PDU_contains_Partial_Network_request_information" ;
VAL_ 611 FD14_SBR1RowDriverSeatSts 0 "Seat_Belt_Fasten" 1 "Seat_Belt_Not_Fasten" 3 "SNA" ;
VAL_ 274 FD14_InternalError 0 "No_int_processing_error_detected" 1 "Int_processing_error_detected" ;
VAL_ 274 FD14_LatAcceleration 4095 "SNA" ;
VAL_ 274 FD14_LatAccelerationFailSts 0 "Fail_Not_Present" 1 "Fail_Present" ;
VAL_ 274 FD14_LongAcceleration 4095 "SNA" ;
VAL_ 274 FD14_LongAccelerationFailSts 0 "Fail_Not_Present" 1 "Fail_Present" ;
VAL_ 274 FD14_YawRate 4095 "SNA" ;
VAL_ 274 FD14_YawRate_HR_Sign 0 "Negative" 1 "Positive" ;
VAL_ 274 FD14_YawRateFailSts 0 "Fail_Not_Present" 1 "Fail_Present" ;
VAL_ 255 FD14_ACC_NCC_TrqEnblRq_Allowed 0 "FALSE" 1 "TRUE" ;
VAL_ 255 FD14_Accel_Pedal_Override 0 "FALSE" 1 "TRUE" ;
VAL_ 255 FD14_ESC_TrqEnblRq_Allowed 0 "FALSE" 1 "TRUE" ;
VAL_ 255 FD14_PPPA_TrqEnblRq_Allowed 0 "FALSE" 1 "TRUE" ;
VAL_ 255 FD14_SSC_TrqEnblRq_Allowed 0 "FALSE" 1 "TRUE" ;
VAL_ 255 FD14_SumTorque_DrvReqMod 8191 "SNA" ;
VAL_ 255 FD14_SumTorqueExp 2047 "SNA" ;
VAL_ 255 FD14_SumTorqueMax 2047 "SNA" ;
VAL_ 255 FD14_SumTorqueMin 2047 "SNA" ;
VAL_ 255 FD14_SumTorqueSel_D_TTC 2047 "SNA" ;
VAL_ 255 FD14_SumTorqueStatic 2047 "SNA" ;
VAL_ 255 FD14_Total_AxleTorque_Static 65535 "SNA" ;
VAL_ 1472 FD14_THA_EPB_Req 0 "No_Request" 1 "EPB_Requested" 3 "SNA" ;
VAL_ 1472 FD14_THA_Speed_Limit 0 "No_Request" 1 "kph_1" 2 "kph_2" 3 "kph_3" 4 "kph_4" 5 "kph_5" 6 "kph_6" 7 "kph_7" 8 "kph_8" 9 "kph_9" 10 "kph_10" 31 "SNA" ;
VAL_ 1472 FD14_THA_SpeedLimit_Req 0 "No_Request" 1 "Requested" 3 "SNA" ;
VAL_ 1472 FD14_THA_STAT 0 "Initial" 1 "Idle" 2 "Enabled" 3 "Engaged" 4 "Complete" 5 "Faulted " 7 "SNA" ;
VAL_ 1472 FD14_THA_SteeringTorqueReq 0 "False" 1 "True" 3 "SNA" ;
VAL_ 1472 FD14_TRSC_SpeedLimit_Req 0 "Not_Limiting" 1 "SPD_4" 2 "SPD_5" 3 "SPD_6" 4 "SPD_7" 5 "SPD_8" 6 "SPD_9" 7 "SPD_10" 15 "SNA" ;
VAL_ 1472 FD14_TRSC_STAT 0 "Standby" 1 "Calibrating" 2 "PreActive" 3 "Active" 4 "OFF" 7 "SNA" ;
VAL_ 1472 FD14_TRSC_SteeringDamping 255 "SNA" ;
VAL_ 1472 FD14_TRSC_SteeringTorqueReq 0 "False" 1 "True" 3 "SNA" ;
VAL_ 1472 FD14_TRSC_VehicleStop_Req 0 "False" 1 "True" 3 "SNA" ;
